VERSION ""

NS_ :

BS_:

BU_: HC IDC_L3 RRR SRR_L SRR_R GW Tester RSDS_L RSDS_R FR IFC HAP PAS CR_L CR_R IDC_L2 HAP_PAS

BO_ 642 HAP_FD4: 64 HAP
 SG_ OD_Obj1_ID : 63|4@0+ (1,0) [0|15] ""  IDC_L3
 SG_ OD_Obj1_type : 15|3@0+ (1,0) [0|3] ""  IDC_L3
 SG_ OD_Obj1_Confidence : 23|4@0+ (0.1,0) [0|1] ""  IDC_L3
 SG_ OD_Obj1_width : 12|5@0+ (0.1,0) [0.1|3.1] "m"  IDC_L3
 SG_ OD_Obj1_length : 19|6@0+ (0.1,0) [0.1|6.3] "m"  IDC_L3
 SG_ OD_Obj1_height : 29|6@0+ (0.1,0) [0.1|6.3] "m"  IDC_L3
 SG_ OD_Obj1_Ground_Pos_X : 39|12@0+ (0.01,0) [0|40] "m"  IDC_L3
 SG_ OD_Obj1_Ground_Pos_Y : 43|12@0+ (0.01,0) [-20|20] "m"  IDC_L3
 SG_ OD_Obj2_ID : 127|4@0+ (1,0) [0|15] ""  IDC_L3
 SG_ OD_Obj2_type : 79|3@0+ (1,0) [0|3] ""  IDC_L3
 SG_ OD_Obj2_Confidence : 87|4@0+ (0.1,0) [0|1] ""  IDC_L3
 SG_ OD_Obj2_width : 76|5@0+ (0.1,0) [0.1|3.1] "m"  IDC_L3
 SG_ OD_Obj2_length : 83|6@0+ (0.1,0) [0.1|6.3] "m"  IDC_L3
 SG_ OD_Obj2_height : 93|6@0+ (0.1,0) [0.1|6.3] "m"  IDC_L3
 SG_ OD_Obj2_Ground_Pos_X : 103|12@0+ (0.01,0) [0|40] "m"  IDC_L3
 SG_ OD_Obj2_Ground_Pos_Y : 107|12@0+ (0.01,0) [-20|20] "m"  IDC_L3
 SG_ OD_Obj3_ID : 191|4@0+ (1,0) [0|15] ""  IDC_L3
 SG_ OD_Obj3_type : 143|3@0+ (1,0) [0|3] ""  IDC_L3
 SG_ OD_Obj3_Confidence : 151|4@0+ (0.1,0) [0|1] ""  IDC_L3
 SG_ OD_Obj3_width : 140|5@0+ (0.1,0) [0.1|3.1] "m"  IDC_L3
 SG_ OD_Obj3_length : 147|6@0+ (0.1,0) [0.1|6.3] "m"  IDC_L3
 SG_ OD_Obj3_height : 157|6@0+ (0.1,0) [0.1|6.3] "m"  IDC_L3
 SG_ OD_Obj3_Ground_Pos_X : 167|12@0+ (0.01,0) [0|40] "m"  IDC_L3
 SG_ OD_Obj3_Ground_Pos_Y : 171|12@0+ (0.01,0) [-20|20] "m"  IDC_L3
 SG_ OD_Obj4_ID : 255|4@0+ (1,0) [0|15] ""  IDC_L3
 SG_ OD_Obj4_type : 207|3@0+ (1,0) [0|3] ""  IDC_L3
 SG_ OD_Obj4_Confidence : 215|4@0+ (0.1,0) [0|1] ""  IDC_L3
 SG_ OD_Obj4_width : 204|5@0+ (0.1,0) [0.1|3.1] "m"  IDC_L3
 SG_ OD_Obj4_length : 211|6@0+ (0.1,0) [0.1|6.3] "m"  IDC_L3
 SG_ OD_Obj4_height : 221|6@0+ (0.1,0) [0.1|6.3] "m"  IDC_L3
 SG_ OD_Obj4_Ground_Pos_X : 231|12@0+ (0.01,0) [0|40] "m"  IDC_L3
 SG_ OD_Obj4_Ground_Pos_Y : 235|12@0+ (0.01,0) [-20|20] "m"  IDC_L3
 SG_ OD_Obj5_ID : 319|4@0+ (1,0) [0|15] ""  IDC_L3
 SG_ OD_Obj5_type : 271|3@0+ (1,0) [0|3] ""  IDC_L3
 SG_ OD_Obj5_Confidence : 279|4@0+ (0.1,0) [0|1] ""  IDC_L3
 SG_ OD_Obj5_width : 268|5@0+ (0.1,0) [0.1|3.1] "m"  IDC_L3
 SG_ OD_Obj5_length : 275|6@0+ (0.1,0) [0.1|6.3] "m"  IDC_L3
 SG_ OD_Obj5_height : 285|6@0+ (0.1,0) [0.1|6.3] "m"  IDC_L3
 SG_ OD_Obj5_Ground_Pos_X : 295|12@0+ (0.01,0) [0|40] "m"  IDC_L3
 SG_ OD_Obj5_Ground_Pos_Y : 299|12@0+ (0.01,0) [-20|20] "m"  IDC_L3
 SG_ OD_Obj6_ID : 383|4@0+ (1,0) [0|15] ""  IDC_L3
 SG_ OD_Obj6_type : 335|3@0+ (1,0) [0|3] ""  IDC_L3
 SG_ OD_Obj6_Confidence : 343|4@0+ (0.1,0) [0|1] ""  IDC_L3
 SG_ OD_Obj6_width : 332|5@0+ (0.1,0) [0.1|3.1] "m"  IDC_L3
 SG_ OD_Obj6_length : 339|6@0+ (0.1,0) [0.1|6.3] "m"  IDC_L3
 SG_ OD_Obj6_height : 349|6@0+ (0.1,0) [0.1|6.3] "m"  IDC_L3
 SG_ OD_Obj6_Ground_Pos_X : 359|12@0+ (0.01,0) [0|40] "m"  IDC_L3
 SG_ OD_Obj6_Ground_Pos_Y : 363|12@0+ (0.01,0) [-20|20] "m"  IDC_L3
 SG_ OD_Obj7_ID : 447|4@0+ (1,0) [0|15] ""  IDC_L3
 SG_ OD_Obj7_type : 399|3@0+ (1,0) [0|3] ""  IDC_L3
 SG_ OD_Obj7_Confidence : 407|4@0+ (0.1,0) [0|1] ""  IDC_L3
 SG_ OD_Obj7_width : 396|5@0+ (0.1,0) [0.1|3.1] "m"  IDC_L3
 SG_ OD_Obj7_length : 403|6@0+ (0.1,0) [0.1|6.3] "m"  IDC_L3
 SG_ OD_Obj7_height : 413|6@0+ (0.1,0) [0.1|6.3] "m"  IDC_L3
 SG_ OD_Obj7_Ground_Pos_X : 423|12@0+ (0.01,0) [0|40] "m"  IDC_L3
 SG_ OD_Obj7_Ground_Pos_Y : 427|12@0+ (0.01,0) [-20|20] "m"  IDC_L3

BO_ 643 IDC_L3_FD3: 16 IDC_L3
 SG_ Checksum_IDC_L3_2 : 7|8@0+ (1,0) [0|255] ""  GW
 SG_ HWP_OperSts : 47|4@0+ (1,0) [0|15] ""  GW
 SG_ EgoVehSpd : 23|12@0+ (0.1,0) [0|200] "km/h"  GW
 SG_ HWP_SpdMaxLim : 27|12@0+ (0.1,0) [0|200] "km/h"  GW
 SG_ HWP_CrsSpdSetVal : 15|8@0+ (1,0) [0|255] "kph/mph"  GW
 SG_ HWP_VehSpdUnit : 49|1@0+ (1,0) [0|1] ""  GW
 SG_ HWP_OperStsDecision : 43|4@0+ (1,0) [0|15] ""  GW
 SG_ HWP_TextWarn : 55|4@0+ (1,0) [0|15] ""  GW
 SG_ HWP_ChimeWarn : 51|2@0+ (1,0) [0|3] ""  GW
 SG_ HWP_HAP_Cmd : 63|2@0+ (1,0) [0|3] ""  HAP
 SG_ RollingCounter_IDC_L3_2 : 59|4@0+ (1,0) [0|15] ""  GW
 SG_ FreshnessValue_IDC_L3_FD3 : 71|16@0+ (1,0) [0|65535] ""  GW
 SG_ MAC_Check_IDC_L3_FD3 : 87|48@0+ (1,0) [0|281474976710655] ""  GW

BO_ 647 HC1: 16 HC
 SG_ CheckSum_HC1 : 7|8@0+ (1,0) [0|255] ""  GW,IFC,IDC_L2
 SG_ HighBeamSts_HC : 15|1@0+ (1,0) [0|1] ""  GW,IFC,IDC_L2
 SG_ ADBstatus : 14|2@0+ (1,0) [0|3] ""  GW,IFC,IDC_L2
 SG_ LeftLowBeamFailSts : 12|1@0+ (1,0) [0|1] ""  GW,IFC,IDC_L2
 SG_ RightLowBeamFailSts : 11|1@0+ (1,0) [0|1] ""  GW,IFC,IDC_L2
 SG_ LeftHighBeamFailSts : 10|1@0+ (1,0) [0|1] ""  GW,IFC,IDC_L2
 SG_ RightHighBeamFailSts : 9|1@0+ (1,0) [0|1] ""  GW,IFC,IDC_L2
 SG_ ALS_FailSts : 8|1@0+ (1,0) [0|1] ""  GW,IFC,IDC_L2
 SG_ ALSDrvSide_FB : 39|1@0+ (1,0) [0|1] ""  GW
 SG_ HBStatusSegment0 : 23|2@0+ (1,0) [0|3] ""  IFC,IDC_L2
 SG_ HBStatusSegment1 : 21|2@0+ (1,0) [0|3] ""  IFC,IDC_L2
 SG_ HBStatusSegment2 : 19|2@0+ (1,0) [0|3] ""  IFC,IDC_L2
 SG_ HBStatusSegment3 : 17|2@0+ (1,0) [0|3] ""  IFC,IDC_L2
 SG_ HBStatusSegment4 : 31|2@0+ (1,0) [0|3] ""  IFC,IDC_L2
 SG_ HBStatusSegment5 : 29|2@0+ (1,0) [0|3] ""  IFC,IDC_L2
 SG_ HBStatusSegment6 : 27|2@0+ (1,0) [0|3] ""  IFC,IDC_L2
 SG_ HBStatusSegment7 : 25|2@0+ (1,0) [0|3] ""  IFC,IDC_L2
 SG_ RollingCounter_HC1 : 59|4@0+ (1,0) [0|15] ""  GW,IFC,IDC_L2

BO_ 648 HUT_FD2: 64 GW
 SG_ HUT_OD_Obj0_ID : 15|4@0+ (1,0) [0|9] ""  HAP_PAS
 SG_ HUT_OD_Obj0_type : 23|3@0+ (1,0) [0|7] ""  HAP_PAS
 SG_ HUT_OD_Obj0_Confidence : 11|4@0+ (0.1,0) [0|1] ""  HAP_PAS
 SG_ HUT_OD_Obj0_width : 20|7@0+ (0.1,0) [0|12.6] "m"  HAP_PAS
 SG_ HUT_OD_Obj0_Ground_Pos_X : 39|12@0+ (0.01,0) [0|40] "m"  HAP_PAS
 SG_ HUT_OD_Obj0_Ground_Pos_Y : 43|12@0+ (0.01,-20) [-20|20] "m"  HAP_PAS
 SG_ HTU_OD_Obj1_ID : 79|4@0+ (1,0) [0|9] ""  HAP_PAS
 SG_ HUT_OD_Obj1_type : 87|3@0+ (1,0) [0|7] ""  HAP_PAS
 SG_ HUT_OD_Obj1_Confidence : 75|4@0+ (0.1,0) [0|1] ""  HAP_PAS
 SG_ HUT_OD_Obj1_width : 84|7@0+ (0.1,0) [0|12.6] "m"  HAP_PAS
 SG_ HUT_OD_Obj1_Ground_Pos_X : 103|12@0+ (0.01,0) [0|40] "m"  HAP_PAS
 SG_ HUT_OD_Obj1_Ground_Pos_Y : 107|12@0+ (0.01,-20) [-20|20] "m"  HAP_PAS
 SG_ HUT_OD_Obj2_ID : 143|4@0+ (1,0) [0|9] ""  HAP_PAS
 SG_ HUT_OD_Obj2_type : 151|3@0+ (1,0) [0|7] ""  HAP_PAS
 SG_ HUT_OD_Obj2_Confidence : 139|4@0+ (0.1,0) [0|1] ""  HAP_PAS
 SG_ HUT_OD_Obj2_width : 148|7@0+ (0.1,0) [0|12.6] "m"  HAP_PAS
 SG_ HUT_OD_Obj2_Ground_Pos_X : 167|12@0+ (0.01,0) [0|40] "m"  HAP_PAS
 SG_ HUT_OD_Obj2_Ground_Pos_Y : 171|12@0+ (0.01,-20) [-20|20] "m"  HAP_PAS
 SG_ HUT_OD_Obj3_ID : 207|4@0+ (1,0) [0|9] ""  HAP_PAS
 SG_ HUT_OD_Obj3_type : 215|3@0+ (1,0) [0|7] ""  HAP_PAS
 SG_ HUT_OD_Obj3_Confidence : 203|4@0+ (0.1,0) [0|1] ""  HAP_PAS
 SG_ HUT_OD_Obj3_width : 212|7@0+ (0.1,0) [0|12.6] "m"  HAP_PAS
 SG_ HUT_OD_Obj3_Ground_Pos_X : 231|12@0+ (0.01,0) [0|40] "m"  HAP_PAS
 SG_ HUT_OD_Obj3_Ground_Pos_Y : 235|12@0+ (0.01,-20) [-20|20] "m"  HAP_PAS
 SG_ HUT_OD_Obj4_ID : 271|4@0+ (1,0) [0|9] ""  HAP_PAS
 SG_ HUT_OD_Obj4_type : 279|3@0+ (1,0) [0|7] ""  HAP_PAS
 SG_ HUT_OD_Obj4_Confidence : 267|4@0+ (0.1,0) [0|1] ""  HAP_PAS
 SG_ HUT_OD_Obj4_width : 276|7@0+ (0.1,0) [0|12.6] "m"  HAP_PAS
 SG_ HUT_OD_Obj4_Ground_Pos_X : 295|12@0+ (0.01,0) [0|40] "m"  HAP_PAS
 SG_ HUT_OD_Obj4_Ground_Pos_Y : 299|12@0+ (0.01,-20) [-20|20] "m"  HAP_PAS
 SG_ HUT_OD_Obj5_ID : 335|4@0+ (1,0) [0|9] ""  HAP_PAS
 SG_ HUT_OD_Obj5_type : 343|3@0+ (1,0) [0|7] ""  HAP_PAS
 SG_ HUT_OD_Obj5_Confidence : 331|4@0+ (0.1,0) [0|1] ""  HAP_PAS
 SG_ HUT_OD_Obj5_width : 340|7@0+ (0.1,0) [0|12.6] "m"  HAP_PAS
 SG_ HUT_OD_Obj5_Ground_Pos_X : 359|12@0+ (0.01,0) [0|40] "m"  HAP_PAS
 SG_ HUT_OD_Obj5_Ground_Pos_Y : 363|12@0+ (0.01,-20) [-20|20] "m"  HAP_PAS
 SG_ HUT_OD_Obj6_ID : 399|4@0+ (1,0) [0|9] ""  HAP_PAS
 SG_ HUT_OD_Obj6_type : 407|3@0+ (1,0) [0|7] ""  HAP_PAS
 SG_ HUT_OD_Obj6_Confidence : 395|4@0+ (0.1,0) [0|1] ""  HAP_PAS
 SG_ HUT_OD_Obj6_width : 404|7@0+ (0.1,0) [0|12.6] "m"  HAP_PAS
 SG_ HUT_OD_Obj6_Ground_Pos_X : 423|12@0+ (0.01,0) [0|40] "m"  HAP_PAS
 SG_ HUT_OD_Obj6_Ground_Pos_Y : 427|12@0+ (0.01,-20) [-20|20] "m"  HAP_PAS

BO_ 649 HAP_FD6: 64 HAP
 SG_ HAP_RtCam_WorkSts : 61|2@0+ (1,0) [0|3] ""  GW
 SG_ HAP_RtSide_Obj1_ID : 15|4@0+ (1,0) [0|3] ""  GW
 SG_ HAP_RtSide_Obj1_type : 11|3@0+ (1,0) [0|7] ""  GW
 SG_ HAP_RtSide_Obj1_Confidence : 27|4@0+ (0.1,0) [0|1] ""  GW
 SG_ HAP_RtSide_Obj1_Ground_Pos_X : 23|12@0+ (0.01,0) [0|40] "m"  GW
 SG_ HAP_RtSide_Obj1_Ground_Pos_Y : 39|12@0+ (0.01,-20) [-20|20] "m"  GW
 SG_ HAP_RtSide_Obj2_ID : 79|4@0+ (1,0) [0|3] ""  GW
 SG_ HAP_RtSide_Obj2_type : 75|3@0+ (1,0) [0|7] ""  GW
 SG_ HAP_RtSide_Obj2_Confidence : 91|4@0+ (0.1,0) [0|1] ""  GW
 SG_ HAP_RtSide_Obj2_Ground_Pos_X : 87|12@0+ (0.01,0) [0|40] "m"  GW
 SG_ HAP_RtSide_Obj2_Ground_Pos_Y : 103|12@0+ (0.01,-20) [-20|20] "m"  GW
 SG_ HAP_RtSide_Obj3_ID : 143|4@0+ (1,0) [0|3] ""  GW
 SG_ HAP_RtSide_Obj3_type : 139|3@0+ (1,0) [0|7] ""  GW
 SG_ HAP_RtSide_Obj3_Confidence : 155|4@0+ (0.1,0) [0|1] ""  GW
 SG_ HAP_RtSide_Obj3_Ground_Pos_X : 151|12@0+ (0.01,0) [0|40] "m"  GW
 SG_ HAP_RtSide_Obj3_Ground_Pos_Y : 167|12@0+ (0.01,-20) [-20|20] "m"  GW
 SG_ HAP_RtSide_Obj4_ID : 207|4@0+ (1,0) [0|3] ""  GW
 SG_ HAP_RtSide_Obj4_type : 203|3@0+ (1,0) [0|7] ""  GW
 SG_ HAP_RtSide_Obj4_Confidence : 219|4@0+ (0.1,0) [0|1] ""  GW
 SG_ HAP_RtSide_Obj4_Ground_Pos_X : 215|12@0+ (0.01,0) [0|40] "m"  GW
 SG_ HAP_RtSide_Obj4_Ground_Pos_Y : 231|12@0+ (0.01,-20) [-20|20] "m"  GW
 SG_ USS_FLSide1_Status : 271|2@0+ (1,0) [0|3] ""  GW
 SG_ USS_FLSide1_Dist : 279|7@0+ (0.1,0) [0|12.6] "m"  GW
 SG_ USS_RLSide2_Status : 269|2@0+ (1,0) [0|3] ""  GW
 SG_ USS_RLSide2_Dist : 287|7@0+ (0.1,0) [0|12.6] "m"  GW
 SG_ USS_FRSide1_Status : 267|2@0+ (1,0) [0|3] ""  GW
 SG_ USS_FRSide1_Dist : 295|7@0+ (0.1,0) [0|12.6] "m"  GW
 SG_ USS_RRSide2_Status : 265|2@0+ (1,0) [0|3] ""  GW
 SG_ USS_RRSide2_Dist : 303|7@0+ (0.1,0) [0|12.6] "m"  GW
 SG_ USS_FrontSys_Status : 383|2@0+ (1,0) [0|3] ""  FR
 SG_ USS_FLCNear_Obj_Confidence : 339|4@0+ (0.1,0) [0|1] ""  FR
 SG_ USS_FLCNear_Obj_Pos_X : 335|6@0+ (0.1,0) [0|6.2] "m"  FR
 SG_ USS_FLCNear_Obj_Pos_Y : 329|6@0+ (0.1,-3.1) [-3.1|3.1] "m"  FR
 SG_ USS_FLMNear_Obj_Confidence : 355|4@0+ (0.1,0) [0|1] ""  FR
 SG_ USS_FLMNear_Obj_Pos_X : 351|6@0+ (0.1,0) [0|6.2] "m"  FR
 SG_ USS_FLMNear_Obj_Pos_Y : 345|6@0+ (0.1,-3.1) [-3.1|3.1] "m"  FR
 SG_ USS_FRMNear_Obj_Confidence : 371|4@0+ (0.1,0) [0|1] ""  FR
 SG_ USS_FRMNear_Obj_Pos_X : 367|6@0+ (0.1,0) [0|6.2] "m"  FR
 SG_ USS_FRMNear_Obj_Pos_Y : 361|6@0+ (0.1,-3.1) [-3.1|3.1] "m"  FR
 SG_ USS_FRCNear_Obj_Confidence : 403|4@0+ (0.1,0) [0|1] ""  FR
 SG_ USS_FRCNear_Obj_Pos_X : 399|6@0+ (0.1,0) [0|6.2] "m"  FR
 SG_ USS_FRCNear_Obj_Pos_Y : 393|6@0+ (0.1,-3.1) [-3.1|3.1] "m"  FR

BO_ 657 HAP_FD5: 64 HAP
 SG_ Freespace_1_distance : 79|6@0+ (0.1,0) [0|6] "m"  IDC_L3
 SG_ Freespace_2_distance : 73|6@0+ (0.1,0) [0|6] "m"  IDC_L3
 SG_ Freespace_3_distance : 83|6@0+ (0.1,0) [0|6] "m"  IDC_L3
 SG_ Freespace_4_distance : 93|6@0+ (0.1,0) [0|6] "m"  IDC_L3
 SG_ Freespace_5_distance : 103|6@0+ (0.1,0) [0|6] "m"  IDC_L3
 SG_ Freespace_6_distance : 97|6@0+ (0.1,0) [0|6] "m"  IDC_L3
 SG_ Freespace_7_distance : 107|6@0+ (0.1,0) [0|6] "m"  IDC_L3
 SG_ Freespace_8_distance : 117|6@0+ (0.1,0) [0|6] "m"  IDC_L3
 SG_ Freespace_9_distance : 143|6@0+ (0.1,0) [0|6] "m"  IDC_L3
 SG_ Freespace_10_distance : 137|6@0+ (0.1,0) [0|6] "m"  IDC_L3
 SG_ Freespace_11_distance : 147|6@0+ (0.1,0) [0|6] "m"  IDC_L3
 SG_ Freespace_12_distance : 157|6@0+ (0.1,0) [0|6] "m"  IDC_L3
 SG_ Freespace_13_distance : 167|6@0+ (0.1,0) [0|6] "m"  IDC_L3
 SG_ Freespace_14_distance : 161|6@0+ (0.1,0) [0|6] "m"  IDC_L3
 SG_ Freespace_15_distance : 171|6@0+ (0.1,0) [0|6] "m"  IDC_L3
 SG_ Freespace_16_distance : 181|6@0+ (0.1,0) [0|6] "m"  IDC_L3
 SG_ Freespace_17_distance : 207|6@0+ (0.1,0) [0|6] "m"  IDC_L3
 SG_ Freespace_18_distance : 201|6@0+ (0.1,0) [0|6] "m"  IDC_L3
 SG_ Freespace_19_distance : 211|6@0+ (0.1,0) [0|6] "m"  IDC_L3
 SG_ Freespace_20_distance : 221|6@0+ (0.1,0) [0|6] "m"  IDC_L3
 SG_ Freespace_21_distance : 231|6@0+ (0.1,0) [0|6] "m"  IDC_L3
 SG_ Freespace_22_distance : 225|6@0+ (0.1,0) [0|6] "m"  IDC_L3
 SG_ Freespace_23_distance : 235|6@0+ (0.1,0) [0|6] "m"  IDC_L3
 SG_ Freespace_24_distance : 245|6@0+ (0.1,0) [0|6] "m"  IDC_L3
 SG_ Freespace_25_distance : 271|6@0+ (0.1,0) [0|6] "m"  IDC_L3
 SG_ Freespace_26_distance : 265|6@0+ (0.1,0) [0|6] "m"  IDC_L3
 SG_ Freespace_27_distance : 275|6@0+ (0.1,0) [0|6] "m"  IDC_L3
 SG_ Freespace_28_distance : 285|6@0+ (0.1,0) [0|6] "m"  IDC_L3
 SG_ Freespace_29_distance : 295|6@0+ (0.1,0) [0|6] "m"  IDC_L3
 SG_ Freespace_30_distance : 289|6@0+ (0.1,0) [0|6] "m"  IDC_L3
 SG_ Freespace_31_distance : 299|6@0+ (0.1,0) [0|6] "m"  IDC_L3
 SG_ Freespace_32_distance : 309|6@0+ (0.1,0) [0|6] "m"  IDC_L3
 SG_ Freespace_33_distance : 335|6@0+ (0.1,0) [0|6] "m"  IDC_L3
 SG_ Freespace_34_distance : 329|6@0+ (0.1,0) [0|6] "m"  IDC_L3
 SG_ Freespace_35_distance : 339|6@0+ (0.1,0) [0|6] "m"  IDC_L3
 SG_ Freespace_36_distance : 349|6@0+ (0.1,0) [0|6] "m"  IDC_L3
 SG_ Freespace_37_distance : 359|6@0+ (0.1,0) [0|6] "m"  IDC_L3
 SG_ Freespace_38_distance : 353|6@0+ (0.1,0) [0|6] "m"  IDC_L3
 SG_ Freespace_39_distance : 363|6@0+ (0.1,0) [0|6] "m"  IDC_L3
 SG_ Freespace_40_distance : 373|6@0+ (0.1,0) [0|6] "m"  IDC_L3
 SG_ Freespace_41_distance : 399|6@0+ (0.1,0) [0|6] "m"  IDC_L3
 SG_ Freespace_42_distance : 393|6@0+ (0.1,0) [0|6] "m"  IDC_L3
 SG_ Freespace_43_distance : 403|6@0+ (0.1,0) [0|6] "m"  IDC_L3
 SG_ Freespace_44_distance : 413|6@0+ (0.1,0) [0|6] "m"  IDC_L3
 SG_ Freespace_45_distance : 423|6@0+ (0.1,0) [0|6] "m"  IDC_L3
 SG_ Freespace_46_distance : 417|6@0+ (0.1,0) [0|6] "m"  IDC_L3
 SG_ Freespace_47_distance : 427|6@0+ (0.1,0) [0|6] "m"  IDC_L3
 SG_ Freespace_48_distance : 437|6@0+ (0.1,0) [0|6] "m"  IDC_L3

BO_ 661 PEPS2: 8 GW
 SG_ SysPowerMod : 15|2@0+ (1,0) [0|3] ""  HC,RSDS_R,RSDS_L,HAP,HAP_PAS,CR_L,CR_R,IDC_L2,IDC_L3
 SG_ SysPowerModVld : 13|1@0+ (1,0) [0|1] ""  RSDS_R,RSDS_L,HAP,HAP_PAS,CR_L,CR_R,IDC_L2,IDC_L3

BO_ 664 HAP_FD3: 64 HAP_PAS
 SG_ RPAS_NearBrrdstn : 15|8@0+ (1,0) [0|150] ""  GW
 SG_ APS_ObjRiSideAr1 : 79|4@0+ (1,0) [0|15] ""  GW
 SG_ APS_ObjRiSideAr2 : 75|4@0+ (1,0) [0|15] ""  GW
 SG_ APS_ObjRiSideAr3 : 87|4@0+ (1,0) [0|15] ""  GW
 SG_ APS_ObjRiSideAr4 : 83|4@0+ (1,0) [0|15] ""  GW
 SG_ APS_ObjRiSideAr5 : 95|4@0+ (1,0) [0|15] ""  GW
 SG_ APS_ObjLeSideAr1 : 91|4@0+ (1,0) [0|15] ""  GW
 SG_ APS_ObjLeSideAr2 : 103|4@0+ (1,0) [0|15] ""  GW
 SG_ APS_ObjLeSideAr3 : 99|4@0+ (1,0) [0|15] ""  GW
 SG_ APS_ObjLeSideAr4 : 111|4@0+ (1,0) [0|15] ""  GW
 SG_ APS_ObjLeSideAr5 : 107|4@0+ (1,0) [0|15] ""  GW
 SG_ APS_FRSideSnsrFailSts : 119|1@0+ (1,0) [0|1] ""  GW
 SG_ APS_FLSideSnsrFailSts : 118|1@0+ (1,0) [0|1] ""  GW
 SG_ APS_RRSideSnsrFailSts : 117|1@0+ (1,0) [0|1] ""  GW
 SG_ APS_RLSideSnsrFailSts : 116|1@0+ (1,0) [0|1] ""  GW
 SG_ SDW_SoundIndcn : 115|2@0+ (1,0) [0|3] ""  GW
 SG_ SDWActiveSts : 112|1@0+ (1,0) [0|1] ""  GW
 SG_ RPAS_ObjRRCornrAr1 : 143|4@0+ (1,0) [0|15] ""  GW
 SG_ RPAS_ObjRRCornrAr2 : 139|4@0+ (1,0) [0|15] ""  GW
 SG_ RPAS_ObjRRMidlAr1 : 151|4@0+ (1,0) [0|15] ""  GW
 SG_ RPAS_ObjRRMidlAr2 : 147|4@0+ (1,0) [0|15] ""  GW
 SG_ RPAS_ObjRLMidlAr1 : 159|4@0+ (1,0) [0|15] ""  GW
 SG_ RPAS_ObjRLMidlAr2 : 155|4@0+ (1,0) [0|15] ""  GW
 SG_ RPAS_ObjRLCornrAr1 : 167|4@0+ (1,0) [0|15] ""  GW
 SG_ RPAS_ObjRLCornrAr2 : 163|4@0+ (1,0) [0|15] ""  GW
 SG_ RPAS_RLCornrSnsrFailSts : 175|1@0+ (1,0) [0|1] ""  GW
 SG_ RPAS_RLMiddlSnsrFailSts : 174|1@0+ (1,0) [0|1] ""  GW
 SG_ RPAS_RRMiddlSnsrFailSts : 173|1@0+ (1,0) [0|1] ""  GW
 SG_ RPAS_RRCornrSnsrFailSts : 172|1@0+ (1,0) [0|1] ""  GW
 SG_ RPAS_WorkSts : 171|2@0+ (1,0) [0|3] ""  GW
 SG_ RPAS_SoundIndcn : 183|2@0+ (1,0) [0|3] ""  GW
 SG_ MEBWorkSts : 180|2@0+ (1,0) [0|3] ""  GW
 SG_ MEB_EnableSts : 178|1@0+ (1,0) [0|1] ""  GW
 SG_ FPAS_ObjFLCornrAr1 : 207|4@0+ (1,0) [0|15] ""  GW
 SG_ FPAS_ObjFLCornrAr2 : 203|4@0+ (1,0) [0|15] ""  GW
 SG_ FPAS_ObjFLMidlAr1 : 215|4@0+ (1,0) [0|15] ""  GW
 SG_ FPAS_ObjFLMidlAr2 : 211|4@0+ (1,0) [0|15] ""  GW
 SG_ FPAS_ObjFRMidlAr1 : 223|4@0+ (1,0) [0|15] ""  GW
 SG_ FPAS_ObjFRMidlAr2 : 219|4@0+ (1,0) [0|15] ""  GW
 SG_ FPAS_ObjFRCornrAr1 : 231|4@0+ (1,0) [0|15] ""  GW
 SG_ FPAS_ObjFRCornrAr2 : 227|4@0+ (1,0) [0|15] ""  GW
 SG_ FPAS_FLCornrSnsrFailSts : 239|1@0+ (1,0) [0|1] ""  GW
 SG_ FPAS_FLMiddlSnsrFailSts : 238|1@0+ (1,0) [0|1] ""  GW
 SG_ FPAS_FRMiddlSnsrFailSts : 237|1@0+ (1,0) [0|1] ""  GW
 SG_ FPAS_FRCornrSnsrFailSts : 236|1@0+ (1,0) [0|1] ""  GW
 SG_ FPAS_WorkSts : 235|2@0+ (1,0) [0|3] ""  GW
 SG_ FPAS_DispCmd : 233|1@0+ (1,0) [0|1] ""  GW
 SG_ FPAS_AutoModSts : 232|1@0+ (1,0) [0|1] ""  GW
 SG_ FPAS_SoundIndcn : 247|2@0+ (1,0) [0|3] ""  GW
 SG_ FPAS_NearBrrdstn : 242|7@0+ (1,0) [0|100] ""  GW
 SG_ APA_MenuDispCtrlCmd : 279|4@0+ (1,0) [0|15] ""  GW
 SG_ APA_FuncSts : 271|2@0+ (1,0) [0|3] ""  GW
 SG_ P2P_FuncSts : 269|2@0+ (1,0) [0|3] ""  GW
 SG_ RADS_FuncSts : 267|2@0+ (1,0) [0|3] ""  GW
 SG_ FADS_FuncSts : 265|2@0+ (1,0) [0|3] ""  GW
 SG_ HAP_TextIconDispCtrl : 275|2@0+ (1,0) [0|3] ""  GW
 SG_ OrvmCtrlCmd : 273|2@0+ (1,0) [0|3] ""  GW
 SG_ RmtPrkgFinishReq : 287|2@0+ (1,0) [0|3] ""  GW
 SG_ RmtPrkgSts : 285|1@0+ (1,0) [0|1] ""  GW
 SG_ APS_Coordinate_Angle : 284|9@0+ (1,0) [0|359] "deg"  GW
 SG_ APS_Coordinate_X : 291|9@0+ (2,-500) [-500|500] "cm"  GW
 SG_ APS_Coordinate_Y : 298|11@0+ (2,-2000) [-2000|2000] "cm"  GW
 SG_ HAPob_WorkSts : 335|2@0+ (1,0) [0|3] ""  IDC_L3
 SG_ LtCobfi : 375|7@0+ (0.01,0) [0|1] ""  IDC_L3
 SG_ LtCurVtur : 351|12@0+ (1E-005,-0.02) [-0.02|0.02] "1/m"  IDC_L3
 SG_ LtSlope : 333|14@0+ (0.001,-6) [-6|6] ""  IDC_L3
 SG_ Ltlntcep : 353|10@0+ (0.01,-5) [-5|5] "m"  IDC_L3
 SG_ RtCobfi : 439|7@0+ (0.01,0) [0|1] ""  IDC_L3
 SG_ RtCurVtur : 415|12@0+ (1E-005,-0.02) [-0.02|0.02] "1/m"  IDC_L3
 SG_ RtSlope : 397|14@0+ (0.001,-6) [-6|-6] ""  IDC_L3
 SG_ Rtlntcep : 417|10@0+ (0.01,-5) [-5|5] "m"  IDC_L3
 SG_ FreshnessValue_HAP_FD3 : 455|16@0+ (1,0) [0|65535] ""  GW
 SG_ MAC_Check_HAP_FD3 : 471|48@0+ (1,0) [0|281474976710655] ""  GW

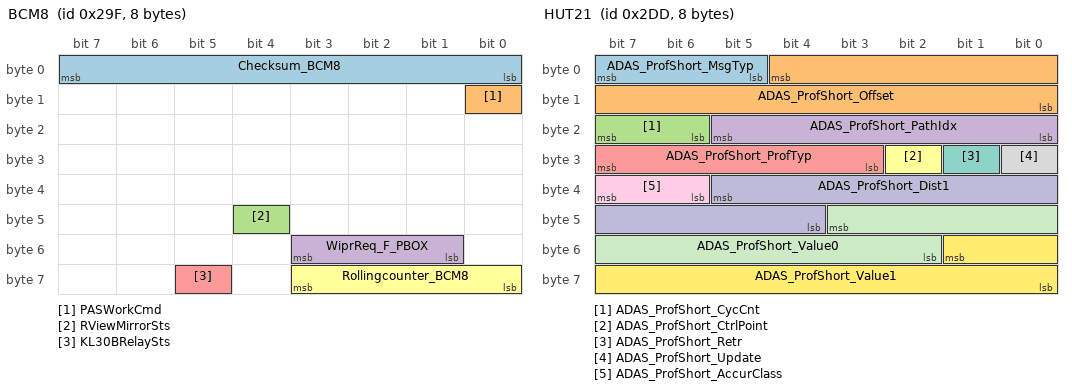
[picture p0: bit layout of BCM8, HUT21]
BO_ 671 BCM8: 8 GW
 SG_ Checksum_BCM8 : 7|8@0+ (1,0) [0|255] ""  HAP,HAP_PAS
 SG_ PASWorkCmd : 8|1@0+ (1,0) [0|1] ""  HAP,HAP_PAS
 SG_ RViewMirrorSts : 44|1@0+ (1,0) [0|1] ""  HAP,HAP_PAS
 SG_ WiprReq_F_PBOX : 51|3@0+ (1,0) [0|7] ""  IFC,HC,IDC_L2
 SG_ KL30BRelaySts : 61|1@0+ (1,0) [0|1] ""  IFC,IDC_L2
 SG_ Rollingcounter_BCM8 : 59|4@0+ (1,0) [0|15] ""  HAP,HAP_PAS

BO_ 680 EEM1: 8 GW
 SG_ TranPMode_Sts : 7|1@0+ (1,0) [0|1] ""  HC
 SG_ Stat_PwrSv_Lvl : 6|3@0+ (1,0) [0|7] ""  HC

BO_ 683 ACC_FD2: 64 FR
 SG_ ACC_LeTgt_02_Dy : 15|7@0+ (0.1,0) [0|8] "m"  GW
 SG_ ACC_LeTgt_02_Dx : 8|9@0+ (0.5,0) [0|150] "m"  GW
 SG_ ACC_LeTgt_02_Typ : 31|3@0+ (1,0) [0|7] ""  GW
 SG_ ACC_LeTargrt_02_Detn : 28|2@0+ (1,0) [0|3] ""  GW
 SG_ ACC_RiTargrt_02_Detn : 26|2@0+ (1,0) [0|3] ""  GW
 SG_ ACC_RiTgt_02_Dy : 55|7@0+ (0.1,-8) [-8|0] "m"  GW
 SG_ ACC_RiTgt_02_Dx : 24|9@0+ (0.5,0) [0|150] "m"  GW
 SG_ ACC_RiTgt_02_Typ : 63|3@0+ (1,0) [0|7] ""  GW
 SG_ ACC_LeTgtObjBarDisp : 47|3@0+ (1,0) [0|7] ""  GW
 SG_ ACC_RiTgtObjBarDisp : 44|3@0+ (1,0) [0|7] ""  GW
 SG_ Checksum_ACC3 : 71|8@0+ (1,0) [0|255] ""  GW
 SG_ ISL_Resp : 79|1@0+ (1,0) [0|1] ""  GW
 SG_ ICA_HandsOffResp : 78|1@0+ (1,0) [0|1] ""  GW
 SG_ Longctrl_VehHldReq_DVR : 87|1@0+ (1,0) [0|1] ""  GW
 SG_ Longctrl_DrvOFF_Req_DVR : 86|1@0+ (1,0) [0|1] ""  GW
 SG_ Longctrl_ModSts_DVR : 85|4@0+ (1,0) [0|15] ""  GW
 SG_ Longctrl_Decel_Req_DVR : 81|1@0+ (1,0) [0|1] ""  GW
 SG_ Longctrl_EngTrqReq_DVR : 95|16@0+ (0.0030518,-100) [-100|99.999713] "%"  GW
 SG_ Longctrl_EngTrqReqActive_DVR : 80|1@0+ (1,0) [0|1] ""  GW
 SG_ Longctrl_DecelToStopReq_DVR : 119|1@0+ (1,0) [0|1] ""  GW
 SG_ Longctrl_ParkShiftReq_DVR : 118|2@0+ (1,0) [0|3] ""  GW
 SG_ Longctrl_Decel_ReqValue_DVR : 111|8@0+ (0.05,-7) [-7|5.75] "m/s^2"  GW
 SG_ Longctrl_HCUTrqReqActive_DVR : 116|1@0+ (1,0) [0|1] ""  GW
 SG_ HWA_SnvtySet_Resp : 76|2@0+ (1,0) [0|3] ""  GW
 SG_ HWA_Resp : 77|1@0+ (1,0) [0|1] ""  GW
 SG_ ALC_Resp : 73|1@0+ (1,0) [0|1] ""  GW
 SG_ ALC_InterSysInfoDisp : 127|2@0+ (1,0) [0|3] ""  GW
 SG_ RollingCounter_ACC3 : 123|4@0+ (1,0) [0|15] ""  GW
 SG_ Checksum_ACC8 : 199|8@0+ (1,0) [0|255] ""  GW
 SG_ Longctrl_HCUTrqReq_DVR : 231|16@0+ (0.5,-16384) [-16384|16383.5] "NM"  GW
 SG_ HWA_warning : 217|2@0+ (1,0) [0|3] ""  GW
 SG_ HWA_ModDisp : 207|4@0+ (1,0) [0|15] ""  GW
 SG_ HWA_InterSysInfoDisp : 203|4@0+ (1,0) [0|15] ""  GW
 SG_ HWA_LaneChangeReq : 223|3@0+ (1,0) [0|7] ""  GW
 SG_ HWA_LaneChange : 213|2@0+ (1,0) [0|3] ""  GW
 SG_ ADAS_DriverInloop_Monitor : 211|3@0+ (1,7) [7|7] ""  GW
 SG_ RollingCounter_ACC8 : 251|4@0+ (1,0) [0|15] ""  GW
 SG_ Checksum_ACC4 : 135|8@0+ (1,0) [0|255] ""  GW
 SG_ ACC_ObjDetecte : 143|1@0+ (1,0) [0|1] ""  GW
 SG_ ACC_TakeOverReq : 142|1@0+ (1,0) [0|1] ""  GW
 SG_ ACC_InterSysInfoDisp : 141|5@0+ (1,0) [0|31] ""  GW
 SG_ ACC_ModDisp : 151|5@0+ (1,0) [0|31] ""  GW
 SG_ ACC_FctSts : 146|2@0+ (1,0) [0|3] ""  GW
 SG_ ACC_TgtObjBarDisp : 159|3@0+ (1,0) [0|7] ""  GW
 SG_ ACC_TimeGapSet : 170|3@0+ (1,0) [0|7] ""  GW
 SG_ ACC_SpdSetValue : 183|8@0+ (1,0) [0|255] "kph/mph"  GW
 SG_ Longctrl_HazActv : 156|2@0+ (1,0) [0|3] ""  GW
 SG_ TJA_ACC_SelSts : 154|3@0+ (1,0) [0|7] ""  GW
 SG_ TJA_ICA_ModDisp : 175|3@0+ (1,0) [0|7] ""  GW
 SG_ TJA_ICA_InterSysInfoDisp : 163|3@0+ (1,0) [0|7] ""  GW
 SG_ ISL_InterSysInfoDisp : 172|2@0+ (1,0) [0|3] ""  GW
 SG_ CruCha_ModDisp : 167|4@0+ (1,0) [0|15] ""  GW
 SG_ CruChar_InterSysInfoDisp : 191|4@0+ (1,0) [0|15] ""  GW
 SG_ RollingCounter_ACC4 : 187|4@0+ (1,0) [0|15] ""  GW
 SG_ Checksum_ACC6 : 263|8@0+ (1,0) [0|255] ""  GW
 SG_ ACC_PotentialTgtDy : 271|8@0+ (0.1,-8) [-8|8] "m"  GW
 SG_ ACC_PotentialTgtDx : 279|9@0+ (0.5,0) [0|150] "m"  GW
 SG_ ACC_RlvTgtDetn : 286|2@0+ (1,0) [0|3] ""  GW,HAP
 SG_ ACC_EgoStatus : 284|2@0+ (1,0) [0|3] ""  GW
 SG_ ACC_RlvTgtTyp : 282|3@0+ (1,0) [0|7] ""  GW,HAP
 SG_ ACC_RlvTgtDy : 295|8@0+ (0.1,-8) [-8|8] "m"  GW,HAP
 SG_ ACC_RlvTgtDx : 303|9@0+ (0.5,0) [0|150] "m"  GW,HAP
 SG_ ACC_PotentialTgtDetn : 309|2@0+ (1,0) [0|3] ""  GW
 SG_ ACC_PotentialTgtTyp : 307|3@0+ (1,0) [0|7] ""  GW
 SG_ IntelligentCurveAct : 319|1@0+ (1,0) [0|1] "" Vector__XXX
 SG_ RollingCounter_ACC6 : 315|4@0+ (1,0) [0|15] ""  GW
 SG_ Checksum_ACC7 : 327|8@0+ (1,0) [0|255] ""  GW
 SG_ Request_driveoff : 383|3@0+ (1,0) [0|7] ""  GW
 SG_ ACC_LeTgtDy : 335|8@0+ (0.1,-8) [-8|8] "m"  GW,HAP
 SG_ ACC_LeTgtDx : 343|9@0+ (0.5,0) [0|150] "m"  GW,HAP
 SG_ ACC_LeTgtTyp : 350|3@0+ (1,0) [0|7] ""  GW,HAP
 SG_ ACC_LeTargrtDection : 347|2@0+ (1,0) [0|3] ""  GW,HAP
 SG_ ACC_RiTargrtDetn : 345|2@0+ (1,0) [0|3] ""  GW,HAP
 SG_ ACC_RiTgtDy : 359|8@0+ (0.1,-8) [-8|8] "m"  GW,HAP
 SG_ ACC_RiTgtDx : 367|9@0+ (0.5,0) [0|150] "m"  GW,HAP
 SG_ ACC_RiTgtTyp : 374|3@0+ (1,0) [0|7] ""  GW,HAP
 SG_ RollingCounter_ACC7 : 379|4@0+ (1,0) [0|15] ""  GW
 SG_ ACC_RlvTgtfusion : 399|1@0+ (1,0) [0|1] ""  GW
 SG_ ACC_RlvTgtHeading : 398|6@0+ (0.05,-1.5) [-1.5|1.5] "rad"  GW
 SG_ ACC_LeTgtfusion : 392|1@0+ (1,0) [0|1] ""  GW
 SG_ ACC_LeTgtHeading : 407|6@0+ (0.05,-1.5) [-1.5|1.5] "rad"  GW
 SG_ ACC_RiTgtfusion : 401|1@0+ (1,0) [0|1] ""  GW
 SG_ ACC_RiTgtHeading : 415|6@0+ (0.05,-1.5) [-1.5|1.5] "rad"  GW
 SG_ ACC_PotentialTgtfusion : 400|1@0+ (1,0) [0|1] ""  GW
 SG_ ACC_PotentialTgtHeading : 409|6@0+ (0.05,-1.5) [-1.5|1.5] "rad"  GW
 SG_ TargetCutinPro : 419|6@0+ (0.02,0) [0|1] ""  GW
 SG_ TargetCutoutPro : 429|6@0+ (0.02,0) [0|1] ""  GW
 SG_ FreshnessValue_ACC_FD2 : 455|16@0+ (1,0) [0|65535] ""  GW,HAP
 SG_ MAC_Check_ACC_FD2 : 471|48@0+ (1,0) [0|281474976710655] ""  GW,HAP

BO_ 692 ACC_FD3: 64 FR
 SG_ AEB_LePedDetn : 41|2@0+ (1,0) [0|3] ""  GW
 SG_ AEB_LePedDy : 15|8@0+ (0.1,-8) [-8|8] "m"  GW
 SG_ AEB_LePedTyp : 55|3@0+ (1,0) [0|7] ""  GW
 SG_ AEB_LePed_collisionprob : 63|1@0+ (1,0) [0|1] ""  GW
 SG_ AEB_RiPedDetn : 49|2@0+ (1,0) [0|3] ""  GW
 SG_ AEB_RiPedDy : 23|8@0+ (0.1,-8) [-8|8] "m"  GW
 SG_ AEB_RiPedTyp : 52|3@0+ (1,0) [0|7] ""  GW
 SG_ AEB_RiPed_collisionprob : 62|1@0+ (1,0) [0|1] ""  GW
 SG_ AEB_LeCyclistDy : 31|8@0+ (0.1,-8) [-8|8] "m"  GW
 SG_ AEB_LeCyclist_collisionprob : 61|1@0+ (1,0) [0|1] ""  GW
 SG_ AEB_RiCyclistDy : 39|8@0+ (0.1,-8) [-8|8] "m"  GW
 SG_ AEB_RiCyclist_collisionprob : 60|1@0+ (1,0) [0|1] ""  GW
 SG_ JAPedObjExist : 47|6@0+ (0.015625,0) [0|0.984375] "%"  GW
 SG_ AEBJAObjID : 79|8@0+ (1,0) [0|255] ""  GW
 SG_ AEBJAObjExist : 87|6@0+ (0.015625,0) [0|0.984375] "%"  GW
 SG_ JAPedObjID : 119|8@0+ (1,0) [0|255] ""  GW
 SG_ AEBJAObjVideoCfmd : 81|1@0+ (1,0) [0|1] ""  GW
 SG_ AEBJAObjVx : 95|12@0+ (0.0625,-128) [-128|127] "m/s"  GW
 SG_ AEBJAObjDx : 99|12@0+ (0.0625,0) [0|255.9375] "m"  GW
 SG_ JAPedObjVideoCfmd : 80|1@0+ (1,0) [0|1] ""  GW
 SG_ AEBJAObjState : 127|3@0+ (1,0) [0|7] ""  GW
 SG_ AEBJAObjCntAlive : 143|12@0+ (17,0) [0|65535] ""  GW
 SG_ AEBJAObjDy : 147|11@0+ (0.125,-128) [-128|127.875] "m"  GW
 SG_ JAPedObjState : 191|3@0+ (1,0) [0|7] ""  GW
 SG_ AEBJAObjObstcl : 152|5@0+ (0.03125,0) [0|0.96875] "%"  GW
 SG_ AEBJAObjVy : 163|10@0+ (0.125,-64) [-64|63.875] "m/s"  GW
 SG_ AEBJAObjAx : 169|10@0+ (0.03125,-16) [-16|15.96875] "m/s2"  GW
 SG_ AEBJAObjAy : 207|10@0+ (0.03125,-16) [-16|15.96875] "m/s2"  GW
 SG_ JAPedObjObstcl : 213|5@0+ (0.03125,0) [0|0.96875] "%"  GW
 SG_ JAPedObjDy : 223|11@0+ (0.125,-128) [-128|127.875] "m"  GW
 SG_ JAPedObjDx : 228|12@0+ (0.0625,0) [0|255.9375] "m"  GW
 SG_ FCWAEB_JATTC : 247|6@0+ (0.1,0) [0|6.3] "s"  GW
 SG_ JAPedObjVx : 271|12@0+ (0.0625,-128) [-128|127] "m/s"  GW
 SG_ JAPedObjVy : 295|10@0+ (0.125,-64) [-64|63.875] "m/s"  GW
 SG_ JAPedObjAy : 301|10@0+ (0.03125,-16) [-16|15.96875] "m/s2"  GW
 SG_ JAPedObjCntAlive : 275|12@0+ (17,0) [0|65535] ""  GW
 SG_ AEB_LePedHeading : 341|6@0+ (0.05,-3) [-3|0] "rad"  GW
 SG_ AEB_RiPedHeading : 351|6@0+ (0.05,0) [0|3] "rad"  GW
 SG_ AEB_LeCyclistHeading : 345|6@0+ (0.05,-3) [-3|0] "rad"  GW
 SG_ AEB_RiCyclistHeading : 355|6@0+ (0.05,0) [0|3] "rad"  GW
 SG_ FCWAEB_longTTC : 365|6@0+ (0.1,0) [0|6.3] "s"  GW
 SG_ FCWAEB_crossingTTC : 375|6@0+ (0.1,0) [0|6.3] "s"  GW
 SG_ JAPedObjAx : 335|10@0+ (0.03125,-16) [-16|15.96875] "m/s2"  GW
 SG_ AEB_LePedDx : 399|9@0+ (0.5,0) [0|150] "m"  GW
 SG_ AEB_RiPedDx : 406|9@0+ (0.5,0) [0|150] "m"  GW
 SG_ AEB_LeCyclistDetn : 413|2@0+ (1,0) [0|3] ""  GW
 SG_ AEB_LeCyclistDx : 423|9@0+ (0.5,0) [0|150] "m"  GW
 SG_ AEB_LeCyclistTyp : 411|3@0+ (1,0) [0|7] ""  GW
 SG_ AEB_RiCyclistDetn : 430|2@0+ (1,0) [0|3] ""  GW
 SG_ AEB_RiCyclistDx : 428|9@0+ (0.5,0) [0|150] "m"  GW
 SG_ AEB_RiCyclistTyp : 435|3@0+ (1,0) [0|7] ""  GW

BO_ 696 ACC_FD4: 64 FR
 SG_ AEBObjID : 7|8@0+ (1,0) [0|255] ""  GW
 SG_ AEBObjExist : 15|6@0+ (0.015625,0) [0|0.984375] "%"  GW
 SG_ AEBObjVideoCfmd : 9|1@0+ (1,0) [0|1] ""  GW
 SG_ AEBObjVx : 23|12@0+ (0.0625,-128) [-128|127] "m/s"  GW
 SG_ AEBObjDx : 27|12@0+ (0.0625,0) [0|255.9375] "m"  GW
 SG_ AEBObjCntAlive : 47|12@0+ (17,0) [0|65535] ""  GW
 SG_ AEBObjDy : 50|11@0+ (0.125,-128) [-128|127.875] "m"  GW
 SG_ AEBObjState : 71|3@0+ (1,0) [0|7] ""  GW
 SG_ AEBObjObstcl : 68|5@0+ (0.03125,0) [0|0.96875] "%"  GW
 SG_ AEBObjVy : 79|10@0+ (0.125,-64) [-64|63.875] "m/s"  GW
 SG_ CyclistObjExist : 85|6@0+ (0.015625,0) [0|0.984375] "%"  GW
 SG_ AEBObjAx : 95|10@0+ (0.03125,-16) [-16|15.96875] "m/s2"  GW
 SG_ AEBObjAy : 101|10@0+ (0.03125,-16) [-16|15.96875] "m/s2"  GW
 SG_ CyclistObjDx : 107|12@0+ (0.0625,0) [0|255.9375] "m"  GW
 SG_ CyclistObjID : 127|8@0+ (1,0) [0|255] ""  GW
 SG_ CyclistObjObstcl : 135|5@0+ (0.03125,0) [0|0.96875] "%"  GW
 SG_ CyclistObjDy : 130|11@0+ (0.125,-128) [-128|127.875] "m"  GW
 SG_ CyclistObjVx : 151|12@0+ (0.0625,-128) [-128|127] "m/s"  GW
 SG_ CyclistObjCntAlive : 155|12@0+ (17,0) [0|65535] ""  GW
 SG_ CyclistObjVy : 175|10@0+ (0.125,-64) [-64|63.875] "m/s"  GW
 SG_ CyclistObjState : 181|3@0+ (1,0) [0|7] ""  GW
 SG_ CyclistObjVideoCfmd : 178|1@0+ (1,0) [0|1] ""  GW
 SG_ CyclistObjAx : 177|10@0+ (0.03125,-16) [-16|15.96875] "m/s2"  GW
 SG_ CyclistObjAy : 199|10@0+ (0.03125,-16) [-16|15.96875] "m/s2"  GW
 SG_ PedObjExist : 205|6@0+ (0.015625,0) [0|0.984375] "%"  GW
 SG_ PedObjID : 215|8@0+ (1,0) [0|255] ""  GW
 SG_ PedObjObstcl : 223|5@0+ (0.03125,0) [0|0.96875] "%"  GW
 SG_ PedObjDy : 218|11@0+ (0.125,-128) [-128|127.875] "m"  GW
 SG_ PedObjDx : 239|12@0+ (0.0625,0) [0|255.9375] "m"  GW
 SG_ PedObjVx : 243|12@0+ (0.0625,-128) [-128|127] "m/s"  GW
 SG_ PedObjVy : 263|10@0+ (0.125,-64) [-64|63.875] "m/s"  GW
 SG_ PedObjVideoCfmd : 269|1@0+ (1,0) [0|1] ""  GW
 SG_ ACCTgtObjDx : 267|12@0+ (0.0625,0) [0|255.9375] "m"  GW
 SG_ PedObjAy : 287|10@0+ (0.03125,-16) [-16|15.96875] "m/s2"  GW
 SG_ PedObjCntAlive : 293|12@0+ (17,0) [0|65535] ""  GW
 SG_ PedObjAx : 297|10@0+ (0.03125,-16) [-16|15.96875] "m/s2"  GW
 SG_ ACCTgtObjID : 319|8@0+ (1,0) [0|255] ""  GW
 SG_ ACCTgtObjObstcl : 327|5@0+ (0.03125,0) [0|0.96875] "%"  GW
 SG_ ACCTgtObjDy : 322|11@0+ (0.125,-128) [-128|127.875] "m"  GW
 SG_ ACCTgtObjExist : 343|6@0+ (0.015625,0) [0|0.984375] "%"  GW
 SG_ ACCTgtObjVy : 337|10@0+ (0.125,-64) [-64|63.875] "m/s"  GW
 SG_ ACCTgtObjVx : 359|12@0+ (0.0625,-128) [-128|127] "m/s"  GW
 SG_ ACCTgtObjAx : 363|10@0+ (0.03125,-16) [-16|15.96875] "m/s2"  GW
 SG_ ACCTgtObjAy : 369|10@0+ (0.03125,-16) [-16|15.96875] "m/s2"  GW
 SG_ ACCTgtObjState : 391|3@0+ (1,0) [0|7] ""  GW
 SG_ ACCTgtObjVideoCfmd : 388|1@0+ (1,0) [0|1] ""  GW
 SG_ ACCTgtObjCntAlive : 387|12@0+ (17,0) [0|65536] ""  GW
 SG_ RadarHorMisalign : 407|12@0+ (0.0001,-0.2048) [-0.2048|0.2047] "rad"  GW
 SG_ HandsoffDetd : 411|2@0+ (1,0) [0|3] ""  GW
 SG_ DrvgOnHiWay : 409|2@0+ (1,0) [0|3] ""  GW
 SG_ RoadCrvt : 423|10@0+ (0.00032,-0.16352) [-0.16352|0.16352] ""  GW
 SG_ SpdLimitDst : 429|6@0+ (10,0) [0|600] "m"  GW
 SG_ RoadCrvtFar : 439|10@0+ (0.00032,-0.16352) [-0.16352|0.16352] ""  GW
 SG_ RampDst : 445|6@0+ (10,0) [0|600] "m"  GW
 SG_ SpdLimit : 455|8@0+ (1,0) [0|255] ""  GW
 SG_ CurveDst : 463|6@0+ (10,0) [0|600] "m"  GW
 SG_ NavSpdLimUnit : 457|2@0+ (1,0) [0|3] ""  GW
 SG_ TunnelDst : 471|6@0+ (10,0) [0|600] "m"  GW
 SG_ DrvgOnRiLane : 465|2@0+ (1,0) [0|3] ""  GW
 SG_ BrdgDst : 479|6@0+ (10,0) [0|600] "m"  GW
 SG_ RadarDrvrAttentive : 473|1@0+ (1,0) [0|1] ""  GW
 SG_ ACC_DataRecReq : 487|3@0+ (1,0) [0|7] ""  GW
 SG_ ACC_SOSReq : 484|2@0+ (1,0) [0|3] ""  GW
 SG_ PedObjState : 482|3@0+ (1,0) [0|7] ""  GW
 SG_ MapDataValid : 495|1@0+ (1,0) [0|1] ""  GW
 SG_ DrvrSts : 494|3@0+ (1,0) [0|7] ""  GW
 SG_ AEBObjOverlap : 491|5@0+ (1,0) [0|1] ""  GW
 SG_ AEBObjDrvby : 502|5@0+ (1,0) [0|1] ""  GW

BO_ 707 HUT_FD1: 64 GW
 SG_ IFC_SnvtySet : 77|2@0+ (1,0) [0|3] ""  IFC,IDC_L2
 SG_ DOWSwtReq : 104|1@0+ (1,0) [0|1] ""  RSDS_R,RSDS_L
 SG_ AEB_PedSwtReq : 105|1@0+ (1,0) [0|1] ""  FR,IDC_L2
 SG_ LCASwtReq : 85|1@0+ (1,0) [0|1] ""  RSDS_R,RSDS_L
 SG_ RCTASwtReq : 84|1@0+ (1,0) [0|1] ""  RSDS_R,RSDS_L
 SG_ RCTABrkSwtReq : 83|1@0+ (1,0) [0|1] ""  RSDS_R,RSDS_L
 SG_ RCWSwtReq : 82|1@0+ (1,0) [0|1] ""  RSDS_R,RSDS_L
 SG_ FCW_SnvtySet : 81|2@0+ (1,0) [0|3] ""  FR,CR_L,CR_R,IDC_L2
 SG_ AEB_VehSwtReq : 95|1@0+ (1,0) [0|1] ""  FR,IDC_L2
 SG_ LKASwtReq : 93|1@0+ (1,0) [0|1] ""  IFC,IDC_L2
 SG_ LCKSwtReq : 92|1@0+ (1,0) [0|1] ""  IFC,IDC_L2
 SG_ ELKSwtReq : 91|1@0+ (1,0) [0|1] ""  IFC,IDC_L2
 SG_ ESS_PedSwtReq : 90|1@0+ (1,0) [0|1] ""  IFC,IDC_L2
 SG_ ESS_VehSwtReq : 89|1@0+ (1,0) [0|1] ""  IFC,IDC_L2
 SG_ LDWSwtReq : 88|1@0+ (1,0) [0|1] ""  IFC,IDC_L2
 SG_ TSRSwtReq : 102|1@0+ (1,0) [0|1] ""  IFC,IDC_L2
 SG_ TSRWarnSwtReq : 101|1@0+ (1,0) [0|1] ""  IFC,IDC_L2
 SG_ ICA_HandsOffSwtReq : 127|1@0+ (1,0) [0|1] ""  FR,IDC_L2
 SG_ ISLSwtReq : 126|1@0+ (1,0) [0|1] ""  FR,IDC_L2
 SG_ TSR_SnvtySet : 125|5@0+ (1,-15) [-15|15] "km/h"  IFC,IDC_L2
 SG_ LSSWarnFormSwtReq : 100|2@0+ (1,0) [0|3] ""  IFC,IDC_L2
 SG_ LSSSwtReq : 106|1@0+ (1,0) [0|1] ""  IFC,IDC_L2
 SG_ IntelligentEvaSwtReq : 107|1@0+ (1,0) [0|1] ""  IFC,IDC_L2
 SG_ NavVehToTrafEyeDist : 239|10@0+ (1,0) [0|1023] ""  IFC,IDC_L2
 SG_ NavRoadType : 311|4@0+ (1,0) [0|15] ""  IFC,IDC_L2
 SG_ NavSpdLimType : 307|2@0+ (1,0) [0|3] ""  IFC,IDC_L2
 SG_ NavSpdLimValue : 271|6@0+ (1,0) [0|63] ""  IFC,IDC_L2
 SG_ NavSpdLimUnit_HUT : 265|2@0+ (1,0) [0|3] ""  IFC,IDC_L2
 SG_ NavCtryType : 279|10@0+ (1,0) [0|1023] ""  IFC,IDC_L2
 SG_ NavSpdLimSignSts : 285|3@0+ (1,0) [0|7] ""  IFC,IDC_L2
 SG_ NavTSRTrafSign : 295|8@0+ (1,0) [0|255] ""  IFC,IDC_L2
 SG_ FCTASwtReq : 301|1@0+ (1,0) [0|1] ""  CR_L,CR_R
 SG_ AESSwtReq : 298|1@0+ (1,0) [0|1] ""  IFC,IDC_L2
 SG_ FCTABrkSwtReq : 300|1@0+ (1,0) [0|1] ""  CR_L,CR_R
 SG_ HWA_SwtReq : 280|1@0+ (1,0) [0|1] ""  IDC_L2
 SG_ HWA_SnvtySet : 303|2@0+ (1,0) [0|3] ""  IDC_L2
 SG_ AEB_JASwtReq : 299|1@0+ (1,0) [0|1] ""  FR,IDC_L2
 SG_ ALC_SwtReq : 296|1@0+ (1,0) [0|1] ""  IDC_L2
 SG_ ADAS_Posn_MsgTye : 327|3@0+ (1,0) [0|7] ""  IFC,IDC_L2
 SG_ ADAS_Posn_Offset : 324|13@0+ (1,0) [0|8190] "m"  IFC,IDC_L2
 SG_ ADAS_Posn_CycCnt : 343|2@0+ (1,0) [0|3] ""  IFC,IDC_L2
 SG_ ADAS_Posn_Pathldx : 341|6@0+ (1,0) [0|63] ""  IFC,IDC_L2
 SG_ ADAS_Posn_Idx : 351|2@0+ (1,0) [0|3] "m"  IFC,IDC_L2
 SG_ ADAS_Posn_PosProbb : 349|5@0+ (3.33,0) [0|100] ""  IFC,IDC_L2
 SG_ ADAS_Posn_Age : 344|9@0+ (5,0) [0|2545] "ms"  IFC,IDC_L2
 SG_ ADAS_Posn_PosConfdc : 366|3@0+ (1,0) [0|7] ""  IFC,IDC_L2
 SG_ ADAS_Posn_CurLane : 363|3@0+ (1,0) [0|7] ""  IFC,IDC_L2
 SG_ ADAS_Posn_Spd : 360|9@0+ (0.2,-12.8) [-12.8|89.2] "m/s"  IFC,IDC_L2
 SG_ ADAS_Posn_Rehead : 383|8@0+ (3,0) [0|358.583] ""  IFC,IDC_L2
 SG_ FreshnessValue_HUT_FD1 : 455|16@0+ (1,0) [0|65535] ""  FR,IDC_L2
 SG_ MAC_Check_HUT_FD1 : 471|48@0+ (1,0) [0|281474976710655] ""  FR,IDC_L2

BO_ 714 DDCM1: 8 GW
 SG_ RSDS_Driver_LED_Sts : 9|1@0+ (1,0) [0|1] ""  RSDS_R,RSDS_L
 SG_ DrvMirrFold_UnfoldSts : 23|1@0+ (1,0) [0|1] ""  HAP,HAP_PAS

BO_ 717 PDCM1: 8 GW
 SG_ PassMirrFold_UnfoldSts : 12|1@0+ (1,0) [0|1] ""  HAP,HAP_PAS
 SG_ RSDS_Pass_LED_Sts : 8|1@0+ (1,0) [0|1] ""  RSDS_R,RSDS_L

BO_ 719 IFC_FD3: 64 IFC
 SG_ Checksum_IFC7 : 71|8@0+ (1,0) [0|255] "" Vector__XXX
 SG_ TSRResp : 79|1@0+ (1,0) [0|1] ""  GW
 SG_ TSRSpdLimUnit : 78|2@0+ (1,0) [0|3] ""  GW
 SG_ TSRSpdLim : 87|6@0+ (1,0) [0|63] ""  GW
 SG_ TSRSpdLimCfdc : 76|2@0+ (1,0) [0|3] ""  GW
 SG_ TSRSts : 74|3@0+ (1,0) [0|7] ""  GW
 SG_ TSRSpdLimSts : 81|2@0+ (1,0) [0|3] ""  GW
 SG_ TSRTrfcSignValCfdc : 95|2@0+ (1,0) [0|3] ""  GW
 SG_ TSRTrfcSignVal : 93|8@0+ (1,0) [0|255] ""  GW
 SG_ TSRSpdLimWarn : 101|1@0+ (1,0) [0|1] ""  GW
 SG_ TSRWarnResp : 108|1@0+ (1,0) [0|1] ""  GW
 SG_ TSR_Snvty : 100|5@0+ (1,-15) [-15|15] "km/h"  GW
 SG_ HMA_Sts : 127|3@0+ (1,0) [0|7] ""  GW
 SG_ HMA_HibeamReq : 113|2@0+ (1,0) [0|3] ""  GW
 SG_ RollingCounter_IFC7 : 123|4@0+ (1,0) [0|15] "" Vector__XXX

BO_ 728 HUT23: 8 GW
 SG_ ADAS_Stub_MsgTyp : 7|3@0+ (1,0) [0|7] ""  IFC,IDC_L2
 SG_ ADAS_Stub_Offset : 4|13@0+ (1,0) [0|8190] "m"  IFC,IDC_L2
 SG_ ADAS_Stub_CycCnt : 23|2@0+ (1,0) [0|3] ""  IFC,IDC_L2
 SG_ ADAS_Stub_PathIdx : 21|6@0+ (1,0) [0|63] ""  IFC,IDC_L2
 SG_ ADAS_Stub_StubPathIdx : 31|6@0+ (1,0) [0|63] ""  IFC,IDC_L2
 SG_ ADAS_Stub_Retr : 25|1@0+ (1,0) [0|1] ""  IFC,IDC_L2
 SG_ ADAS_Stub_Update : 24|1@0+ (1,0) [0|1] ""  IFC,IDC_L2
 SG_ ADAS_Stub_RelProbb : 39|5@0+ (1,0) [0|100] ""  IFC,IDC_L2
 SG_ ADAS_Stub_FuncRoadClass : 34|3@0+ (1,0) [0|7] ""  IFC,IDC_L2
 SG_ ADAS_Stub_PartOfCalcRoute : 47|2@0+ (1,0) [0|3] ""  IFC,IDC_L2
 SG_ ADAS_Stub_CmplxInsct : 45|2@0+ (1,0) [0|3] ""  IFC,IDC_L2
 SG_ ADAS_Stub_FormOfWay : 43|4@0+ (1,0) [0|15] ""  IFC,IDC_L2
 SG_ ADAS_Stub_TurnAngl : 55|8@0+ (3,0) [0|358.583] ""  IFC,IDC_L2
 SG_ ADAS_Stub_LastStub : 63|1@0+ (1,0) [0|1] ""  IFC,IDC_L2
 SG_ ADAS_Stub_RtOfWay : 62|2@0+ (1,0) [0|3] ""  IFC,IDC_L2
 SG_ ADAS_Stub_NumOfLaneOppDir : 60|2@0+ (1,0) [0|3] ""  IFC,IDC_L2
 SG_ ADAS_Stub_NumOfLaneDrvDir : 58|3@0+ (1,0) [0|7] ""  IFC,IDC_L2

BO_ 730 HUT22: 8 GW
 SG_ ADAS_Seg_MsgTyp : 7|3@0+ (1,0) [0|7] ""  IFC,IDC_L2
 SG_ ADAS_Seg_Offset : 4|13@0+ (1,0) [0|8190] "m"  IFC,IDC_L2
 SG_ ADAS_Seg_CycCnt : 23|2@0+ (1,0) [0|3] ""  IFC,IDC_L2
 SG_ ADAS_Seg_PathIdx : 21|6@0+ (1,0) [0|63] "0"  IFC,IDC_L2
 SG_ ADAS_Seg_Tunnel : 31|2@0+ (1,0) [0|3] ""  IFC,IDC_L2
 SG_ ADAS_Seg_Brdg : 29|2@0+ (1,0) [0|3] ""  IFC,IDC_L2
 SG_ ADAS_Seg_BuildUpArea : 27|2@0+ (1,0) [0|3] ""  IFC,IDC_L2
 SG_ ADAS_Seg_Retr : 25|1@0+ (1,0) [0|1] ""  IFC,IDC_L2
 SG_ ADAS_Seg_Update : 24|1@0+ (1,0) [0|1] ""  IFC,IDC_L2
 SG_ ADAS_Seg_RelProbb : 39|5@0+ (1,0) [0|100] ""  IFC,IDC_L2
 SG_ ADAS_Seg_FuncRoadClass : 34|3@0+ (1,0) [0|7] ""  IFC,IDC_L2
 SG_ ADAS_Seg_PartOfCalcRoute : 47|2@0+ (1,0) [0|3] ""  IFC,IDC_L2
 SG_ ADAS_Seg_CmplxInsct : 45|2@0+ (1,0) [0|3] ""  IFC,IDC_L2
 SG_ ADAS_Seg_FormOfWay : 43|4@0+ (1,0) [0|15] ""  IFC,IDC_L2
 SG_ ADAS_Seg_EffSpdLmt : 55|5@0+ (1,0) [0|31] ""  IFC,IDC_L2
 SG_ ADAS_Seg_EffSpdLmtTyp : 50|3@0+ (1,0) [0|7] ""  IFC,IDC_L2
 SG_ ADAS_Seg_DivideRoad : 62|2@0+ (1,0) [0|3] ""  IFC,IDC_L2
 SG_ ADAS_Seg_NumOfLaneOppDir : 60|2@0+ (1,0) [0|3] ""  IFC,IDC_L2
 SG_ ADAS_Seg_NumOfLaneDrvDir : 58|3@0+ (1,0) [0|7] ""  IFC,IDC_L2

BO_ 733 HUT21: 8 GW
 SG_ ADAS_ProfShort_MsgTyp : 7|3@0+ (1,0) [0|7] ""  IFC,IDC_L2
 SG_ ADAS_ProfShort_Offset : 4|13@0+ (1,0) [0|8190] "m"  IFC,IDC_L2
 SG_ ADAS_ProfShort_CycCnt : 23|2@0+ (1,0) [0|3] ""  IFC,IDC_L2
 SG_ ADAS_ProfShort_PathIdx : 21|6@0+ (1,0) [0|63] ""  IFC,IDC_L2
 SG_ ADAS_ProfShort_ProfTyp : 31|5@0+ (1,0) [0|31] ""  IFC,IDC_L2
 SG_ ADAS_ProfShort_CtrlPoint : 26|1@0+ (1,0) [0|1] ""  IFC,IDC_L2
 SG_ ADAS_ProfShort_Retr : 25|1@0+ (1,0) [0|1] ""  IFC,IDC_L2
 SG_ ADAS_ProfShort_Update : 24|1@0+ (1,0) [0|1] ""  IFC,IDC_L2
 SG_ ADAS_ProfShort_AccurClass : 39|2@0+ (1,0) [0|3] ""  IFC,IDC_L2
 SG_ ADAS_ProfShort_Dist1 : 37|10@0+ (1,0) [0|1022] "m"  IFC,IDC_L2
 SG_ ADAS_ProfShort_Value0 : 43|10@0+ (1,0) [0|1022] ""  IFC,IDC_L2
 SG_ ADAS_ProfShort_Value1 : 49|10@0+ (1,0) [0|1022] ""  IFC,IDC_L2

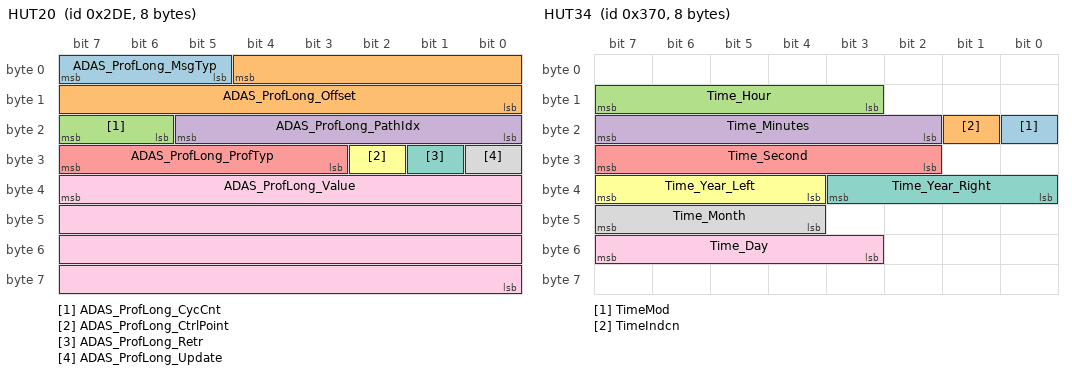
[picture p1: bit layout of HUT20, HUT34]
BO_ 734 HUT20: 8 GW
 SG_ ADAS_ProfLong_MsgTyp : 7|3@0+ (1,0) [0|7] ""  IFC,IDC_L2
 SG_ ADAS_ProfLong_Offset : 4|13@0+ (1,0) [0|8190] "m"  IFC,IDC_L2
 SG_ ADAS_ProfLong_CycCnt : 23|2@0+ (1,0) [0|3] ""  IFC,IDC_L2
 SG_ ADAS_ProfLong_PathIdx : 21|6@0+ (1,0) [0|63] ""  IFC,IDC_L2
 SG_ ADAS_ProfLong_ProfTyp : 31|5@0+ (1,0) [0|31] ""  IFC,IDC_L2
 SG_ ADAS_ProfLong_CtrlPoint : 26|1@0+ (1,0) [0|1] ""  IFC,IDC_L2
 SG_ ADAS_ProfLong_Retr : 25|1@0+ (1,0) [0|1] ""  IFC,IDC_L2
 SG_ ADAS_ProfLong_Update : 24|1@0+ (1,0) [0|1] ""  IFC,IDC_L2
 SG_ ADAS_ProfLong_Value : 39|32@0+ (1,0) [0|4294967295] ""  IFC,IDC_L2

BO_ 743 BCM10: 16 GW
 SG_ Checksum_BCM10 : 7|8@0+ (1,0) [0|255] ""  IDC_L3
 SG_ HiBeamWorkCmd : 11|1@0+ (1,0) [0|1] ""  IDC_L3
 SG_ LowBeamWorkCmd : 10|1@0+ (1,0) [0|1] ""  IDC_L3
 SG_ RTurnLmpWorkCmd : 9|1@0+ (1,0) [0|1] ""  IDC_L3
 SG_ LTurnLampWorkCmd : 8|1@0+ (1,0) [0|1] ""  IDC_L3
 SG_ FFogLmpAsstSts : 23|1@0+ (1,0) [0|1] ""  IDC_L3
 SG_ HornWorkCmd : 22|1@0+ (1,0) [0|1] ""  IDC_L3
 SG_ RDayRunngLmpWorkCmd : 21|1@0+ (1,0) [0|1] ""  IDC_L3
 SG_ LDayRunngLmpWorkCmd : 20|1@0+ (1,0) [0|1] ""  IDC_L3
 SG_ RFFogLmpWorkCmd : 19|1@0+ (1,0) [0|1] ""  IDC_L3
 SG_ LFFogLmpWorkCmd : 18|1@0+ (1,0) [0|1] ""  IDC_L3
 SG_ AsstPosnLmpSts : 31|1@0+ (1,0) [0|1] ""  IDC_L3
 SG_ ChildLockProtWorkCmd : 30|2@0+ (1,0) [0|3] ""  IDC_L3
 SG_ LicPlateLmpWorkCmd : 27|1@0+ (1,0) [0|1] ""  IDC_L3
 SG_ ReversLampWorkCmd : 26|1@0+ (1,0) [0|1] ""  IDC_L3
 SG_ BrkLmpWorkCmd : 25|1@0+ (1,0) [0|1] ""  IDC_L3
 SG_ RFogLmpWorkCmd : 24|1@0+ (1,0) [0|1] ""  IDC_L3
 SG_ LasHdLmpWorkCmd : 37|1@0+ (1,0) [0|1] ""  IDC_L3
 SG_ LCornrLmpWorkCmd : 36|1@0+ (1,0) [0|1] ""  IDC_L3
 SG_ RCornrLmpWorkCmd : 35|1@0+ (1,0) [0|1] ""  IDC_L3
 SG_ RHorseRaceLmpWorkCmd : 34|1@0+ (1,0) [0|1] ""  IDC_L3
 SG_ LHorseRaceLmpWorkCmd : 33|1@0+ (1,0) [0|1] ""  IDC_L3
 SG_ TrunkLmpWorkCmd : 32|1@0+ (1,0) [0|1] ""  IDC_L3
 SG_ Rollingcounter_BCM10 : 59|4@0+ (1,0) [0|15] ""  IDC_L3
 SG_ FreshnessValue_BCM10 : 71|16@0+ (1,0) [0|65535] ""  IDC_L3
 SG_ MAC_Check_BCM10 : 87|48@0+ (1,0) [0|281474976710655] ""  IDC_L3

BO_ 745 HUT_FD3: 64 GW
 SG_ HUT_OD_Obj7_ID : 15|4@0+ (1,0) [0|9] ""  HAP_PAS
 SG_ HUT_OD_Obj7_type : 23|3@0+ (1,0) [0|7] ""  HAP_PAS
 SG_ HUT_OD_Obj7_Confidence : 11|4@0+ (0.1,0) [0|1] ""  HAP_PAS
 SG_ HUT_OD_Obj7_width : 20|7@0+ (0.1,0) [0|12.6] "m"  HAP_PAS
 SG_ HUT_OD_Obj7_Ground_Pos_X : 39|12@0+ (0.01,0) [0|40] "m"  HAP_PAS
 SG_ HUT_OD_Obj7_Ground_Pos_Y : 43|12@0+ (0.01,-20) [-20|20] "m"  HAP_PAS
 SG_ HUT_OD_WorkSts : 113|2@0+ (1,0) [0|3] ""  HAP_PAS
 SG_ HUT_OD_Obj_Timestamp : 79|16@0+ (1,0) [0|65535] "ms"  HAP_PAS
 SG_ HUT_FSD1_distance : 95|6@0+ (0.1,0) [0|6] "m"  HAP_PAS
 SG_ HUT_FSD2_distance : 89|6@0+ (0.1,0) [0|6] "m"  HAP_PAS
 SG_ HUT_FSD3_distance : 99|6@0+ (0.1,0) [0|6] "m"  HAP_PAS
 SG_ HUT_FSD4_distance : 109|6@0+ (0.1,0) [0|6] "m"  HAP_PAS
 SG_ HUT_FSD5_distance : 119|6@0+ (0.1,0) [0|6] "m"  HAP_PAS
 SG_ HUT_FSD6_distance : 143|6@0+ (0.1,0) [0|6] "m"  HAP_PAS
 SG_ HUT_FSD7_distance : 137|6@0+ (0.1,0) [0|6] "m"  HAP_PAS
 SG_ HUT_FSD8_distance : 147|6@0+ (0.1,0) [0|6] "m"  HAP_PAS
 SG_ HUT_FSD9_distance : 157|6@0+ (0.1,0) [0|6] "m"  HAP_PAS
 SG_ HUT_FSD10_distance : 167|6@0+ (0.1,0) [0|6] "m"  HAP_PAS
 SG_ HUT_FSD11_distance : 161|6@0+ (0.1,0) [0|6] "m"  HAP_PAS
 SG_ HUT_FSD12_distance : 171|6@0+ (0.1,0) [0|6] "m"  HAP_PAS
 SG_ HUT_FSD13_distance : 181|6@0+ (0.1,0) [0|6] "m"  HAP_PAS
 SG_ HUT_FSD14_distance : 207|6@0+ (0.1,0) [0|6] "m"  HAP_PAS
 SG_ HUT_FSD15_distance : 201|6@0+ (0.1,0) [0|6] "m"  HAP_PAS
 SG_ HUT_FSD16_distance : 211|6@0+ (0.1,0) [0|6] "m"  HAP_PAS
 SG_ HUT_FSD17_distance : 221|6@0+ (0.1,0) [0|6] "m"  HAP_PAS
 SG_ HUT_FSD18_distance : 231|6@0+ (0.1,0) [0|6] "m"  HAP_PAS

BO_ 748 DVR_FD1: 64 GW
 SG_ DVR_360VideoCaptureReq : 9|1@0+ (1,0) [0|1] ""  HAP

BO_ 762 HCU_PT4: 8 GW
 SG_ HCU_RdyLmpSts : 37|1@0+ (1,0) [0|1] ""  HC

BO_ 769 ECM_FD3: 64 GW
 SG_ MaxEngTrqNorm : 87|7@0+ (5,0) [0|510] "Nm"  FR,HAP,IDC_L2,IDC_L3
 SG_ EngLimpHomeSts : 115|1@0+ (1,0) [0|1] ""  FR,IDC_L2,IDC_L3

BO_ 778 RSDS_FD2: 64 RSDS_R
 SG_ RCTA_B_TTC : 15|6@0+ (0.1,0) [0|6.3] "s"  GW
 SG_ BSD_LCA_Left_TTC : 9|6@0+ (0.1,0) [0|6.3] "s"  GW
 SG_ BSD_LCA_Right_TTC : 19|6@0+ (0.1,0) [0|6.3] "s"  GW
 SG_ RCW_TTC : 29|6@0+ (0.1,0) [0|6.3] "s"  GW
 SG_ RSDS_LeTgt_01 : 79|1@0+ (1,0) [0|1] ""  GW
 SG_ RSDS_LeTgt_01_dx : 87|10@0+ (0.1,-90) [-90|5] "m"  GW
 SG_ RSDS_LeTgt_01_dy : 78|7@0+ (0.1,0) [0|8] "m"  GW
 SG_ RSDS_LeTgt_02 : 93|1@0+ (1,0) [0|1] ""  GW
 SG_ RSDS_LeTgt_02_dx : 92|10@0+ (0.1,-90) [-90|5] "m"  GW
 SG_ RSDS_LeTgt_02_dy : 98|7@0+ (0.1,0) [0|8] "m"  GW
 SG_ RSDS_RiTgt_01 : 107|1@0+ (1,0) [0|1] ""  GW
 SG_ RSDS_RiTgt_01_dx : 106|10@0+ (0.1,-90) [-90|5] "m"  GW
 SG_ RSDS_RiTgt_01_dy : 143|7@0+ (0.1,-8) [-8|0] "m"  GW
 SG_ RSDS_RiTgt_02 : 136|1@0+ (1,0) [0|1] ""  GW
 SG_ RSDS_RiTgt_02_dx : 151|10@0+ (0.1,-90) [-90|5] "m"  GW
 SG_ RSDS_RiTgt_02_dy : 157|7@0+ (0.1,-8) [-8|0] "m"  GW
 SG_ RSDS_MidTgt_01 : 166|1@0+ (1,0) [0|1] ""  GW
 SG_ RSDS_MidTgt_01_dx : 165|10@0+ (0.1,-90) [-90|5] "m"  GW
 SG_ RSDS_MidTgt_01_dy : 171|7@0+ (0.1,-4) [-4|4] "m"  GW
 SG_ RSDS_MidTgt_02 : 180|1@0+ (1,0) [0|1] ""  GW
 SG_ RSDS_MidTgt_02_dx : 207|10@0+ (0.1,-90) [-90|5] "m"  GW
 SG_ RSDS_MidTgt_02_dy : 213|7@0+ (0.1,-4) [-4|4] "m"  GW

BO_ 793 BCM1: 16 GW
 SG_ TrunkSts : 23|1@0+ (1,0) [0|1] ""  HAP,HAP_PAS,IDC_L3
 SG_ DrvDoorSts : 22|1@0+ (1,0) [0|1] ""  IFC,FR,RSDS_R,RSDS_L,HAP,HAP_PAS,CR_L,CR_R,IDC_L2,IDC_L3
 SG_ LRDoorSts : 21|1@0+ (1,0) [0|1] ""  IFC,FR,RSDS_R,RSDS_L,HAP,HAP_PAS,IDC_L2,IDC_L3
 SG_ PassengerDoorSts : 20|1@0+ (1,0) [0|1] ""  IFC,FR,RSDS_R,RSDS_L,HAP,HAP_PAS,IDC_L2,IDC_L3
 SG_ RRDoorSts : 19|1@0+ (1,0) [0|1] ""  IFC,FR,RSDS_R,RSDS_L,HAP,HAP_PAS,IDC_L2,IDC_L3
 SG_ WindshldWiprActvSts : 17|1@0+ (1,0) [0|1] ""  IFC,FR,IDC_L2,IDC_L3
 SG_ BrkPedalSts_BCM : 16|1@0+ (1,0) [0|1] ""  IDC_L3
 SG_ BrkPedalFailSts : 31|1@0+ (1,0) [0|1] ""  IDC_L3
 SG_ ParkBrkSts : 46|2@0+ (1,0) [0|3] ""  IDC_L3
 SG_ ReversGearSts : 42|2@0+ (1,0) [0|3] ""  IDC_L3
 SG_ PosnLightReq : 61|1@0+ (1,0) [0|1] ""  IDC_L3
 SG_ RLSFailSts : 63|1@0+ (1,0) [0|1] ""  IDC_L3
 SG_ FreshnessValue_BCM1 : 71|16@0+ (1,0) [0|65535] ""  FR,IDC_L2,IDC_L3
 SG_ MAC_Check_BCM1 : 87|48@0+ (1,0) [0|281474976710655] ""  FR,IDC_L2,IDC_L3

BO_ 833 TPMS1: 16 GW
 SG_ FLTirePressIndSts : 15|3@0+ (1,0) [0|4] ""  IDC_L3
 SG_ FRTirePressIndSts : 12|3@0+ (1,0) [0|4] ""  IDC_L3
 SG_ TirePressSysFailrIndcn : 9|2@0+ (1,0) [0|1] ""  IDC_L3
 SG_ RLTirePressIndSts : 23|3@0+ (1,0) [0|4] ""  IDC_L3
 SG_ RRTirePressIndSts : 20|3@0+ (1,0) [0|4] ""  IDC_L3
 SG_ FLTireTempSts : 31|2@0+ (1,0) [0|3] ""  IDC_L3
 SG_ FRTireTempSts : 29|2@0+ (1,0) [0|3] ""  IDC_L3
 SG_ RLTireTempSts : 27|2@0+ (1,0) [0|3] ""  IDC_L3
 SG_ RRTireTempSts : 25|2@0+ (1,0) [0|3] ""  IDC_L3
 SG_ TPMS_AutoLoctSts : 39|4@0+ (1,0) [0|5] ""  IDC_L3
 SG_ FreshnessValue_TPMS1 : 71|16@0+ (1,0) [0|65535] ""  IDC_L3
 SG_ MAC_Check_TPMS1 : 87|48@0+ (1,0) [0|281474976710655] ""  IDC_L3

BO_ 837 BCM3: 16 GW
 SG_ BCM_HWPWorkSts : 42|2@0+ (1,0) [0|3] ""  IDC_L3
 SG_ HazardLmpSwtSts : 8|1@0+ (1,0) [0|1] ""  IFC,FR,IDC_L2,IDC_L3
 SG_ FreshnessValue_BCM3 : 71|16@0+ (1,0) [0|65535] ""  FR,IDC_L2,IDC_L3
 SG_ MAC_Check_BCM3 : 87|48@0+ (1,0) [0|281474976710655] ""  FR,IDC_L2,IDC_L3

BO_ 846 ACC_FD5: 16 FR
 SG_ Sync_CRC : 15|8@0+ (1,0) [0|255] ""  CR_L,CR_R
 SG_ Sync_OVS : 25|2@0+ (1,0) [0|3] ""  CR_L,CR_R
 SG_ Sync_Resd : 31|5@0+ (1,0) [0|31] ""  CR_L,CR_R
 SG_ Sync_Counter : 19|4@0+ (1,0) [0|15] ""  CR_L,CR_R
 SG_ Sync_SGW : 26|1@0+ (1,0) [0|1] ""  CR_L,CR_R
 SG_ Sync_SyncTime : 39|32@0+ (1,0) [0|4294967295] ""  CR_L,CR_R
 SG_ Sync_TimeDomain : 23|4@0+ (1,0) [0|15] ""  CR_L,CR_R
 SG_ Sync_Type : 7|8@0+ (1,0) [0|255] ""  CR_L,CR_R

BO_ 849 ABM1: 16 GW
 SG_ CheckSum_ABM1 : 7|8@0+ (1,0) [0|255] ""  FR,HAP,HAP_PAS,IDC_L2,IDC_L3
 SG_ DrvSBR : 11|1@0+ (1,0) [0|1] ""  IFC,FR,HAP,HAP_PAS,IDC_L2,IDC_L3
 SG_ PassSBR : 9|1@0+ (1,0) [0|1] ""  IFC,FR,HAP,HAP_PAS,IDC_L2,IDC_L3
 SG_ PABSwtSts : 15|1@0+ (1,0) [0|1] ""  IDC_L3
 SG_ SecRowLSBR : 14|1@0+ (1,0) [0|1] ""  IDC_L3
 SG_ AirbFailLmpCmd : 13|1@0+ (1,0) [0|1] ""  IDC_L3
 SG_ SecRowMidSBR : 12|1@0+ (1,0) [0|1] ""  IDC_L3
 SG_ SecRowRSBR : 10|1@0+ (1,0) [0|1] ""  IDC_L3
 SG_ PassSBR_Visual : 27|2@0+ (1,0) [0|3] ""  IDC_L3
 SG_ DrvSBR_Visual : 25|2@0+ (1,0) [0|3] ""  IDC_L3
 SG_ SecRowLSBR_Visual : 29|2@0+ (1,0) [0|3] ""  IDC_L3
 SG_ SecRowMidSBR_Visual : 31|2@0+ (1,0) [0|3] ""  IDC_L3
 SG_ SecRowRSBR_Visual : 33|2@0+ (1,0) [0|3] ""  IDC_L3
 SG_ CrashOutputSts : 23|8@0+ (1,0) [0|18] ""  IDC_L3
 SG_ RollingCounter_ABM1 : 59|4@0+ (1,0) [0|15] ""  FR,HAP,HAP_PAS,IDC_L2,IDC_L3
 SG_ FreshnessValue_ABM1 : 71|16@0+ (1,0) [0|65535] ""  FR,IDC_L2,IDC_L3
 SG_ MAC_Check_ABM1 : 87|48@0+ (1,0) [0|281474976710655] ""  FR,IDC_L2,IDC_L3

BO_ 880 HUT34: 8 GW
 SG_ TimeMod : 16|1@0+ (1,0) [0|1] ""  IFC,HAP,HAP_PAS,IDC_L2,IDC_L3
 SG_ TimeIndcn : 17|1@0+ (1,0) [0|1] ""  IFC,HAP,HAP_PAS,IDC_L2,IDC_L3
 SG_ Time_Hour : 15|5@0+ (1,0) [0|31] ""  IFC,HC,FR,RSDS_R,RSDS_L,HAP,HAP_PAS,CR_L,CR_R,IDC_L2,IDC_L3
 SG_ Time_Minutes : 23|6@0+ (1,0) [0|63] ""  IFC,HC,FR,RSDS_R,RSDS_L,HAP,HAP_PAS,CR_L,CR_R,IDC_L2,IDC_L3
 SG_ Time_Second : 31|6@0+ (1,0) [0|63] ""  IFC,FR,RSDS_R,RSDS_L,HAP,HAP_PAS,CR_L,CR_R,IDC_L2,IDC_L3
 SG_ Time_Year_Left : 39|4@0+ (1,0) [0|15] ""  IFC,HC,FR,RSDS_R,RSDS_L,HAP,HAP_PAS,CR_L,CR_R,IDC_L2,IDC_L3
 SG_ Time_Year_Right : 35|4@0+ (1,0) [0|15] ""  IFC,HC,FR,RSDS_R,RSDS_L,HAP,HAP_PAS,CR_L,CR_R,IDC_L2,IDC_L3
 SG_ Time_Month : 47|4@0+ (1,0) [0|15] ""  IFC,HC,FR,RSDS_R,RSDS_L,HAP,HAP_PAS,CR_L,CR_R,IDC_L2,IDC_L3
 SG_ Time_Day : 55|5@0+ (1,0) [0|31] ""  IFC,HC,FR,RSDS_R,RSDS_L,HAP,HAP_PAS,CR_L,CR_R,IDC_L2,IDC_L3

BO_ 901 AC2: 8 GW
 SG_ ACAmbTemp : 23|8@0+ (0.5,-40) [-40|86.5] "буC"  IFC,FR,HAP,HAP_PAS,IDC_L2,IDC_L3
 SG_ ACFrntBlwrSpd : 11|4@0+ (1,0) [0|15] ""  IDC_L3

BO_ 1001 T_Box_FD3: 16 GW
 SG_ T_Box_SysErrSts : 7|5@0+ (1,0) [0|1] ""  FR,IDC_L2
 SG_ FreshnessValue_T_Box_FD3 : 71|16@0+ (1,0) [0|65535] ""  FR,IDC_L2
 SG_ MAC_Check_T_Box_FD3 : 87|48@0+ (1,0) [0|281474976710655] ""  FR,IDC_L2

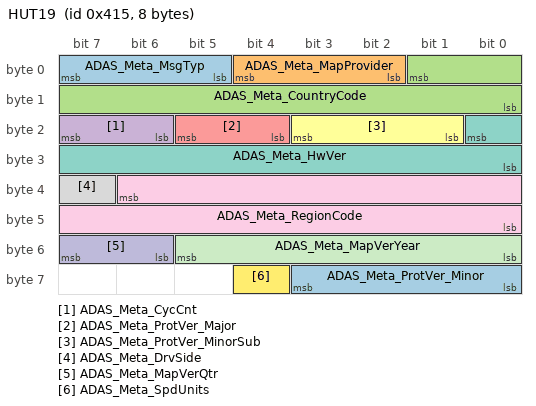
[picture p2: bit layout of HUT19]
BO_ 1045 HUT19: 8 GW
 SG_ ADAS_Meta_MsgTyp : 7|3@0+ (1,0) [0|7] ""  IFC,IDC_L2
 SG_ ADAS_Meta_MapProvider : 4|3@0+ (1,0) [0|7] ""  IFC,IDC_L2
 SG_ ADAS_Meta_CountryCode : 1|10@0+ (1,0) [0|1023] ""  IFC,IDC_L2
 SG_ ADAS_Meta_CycCnt : 23|2@0+ (1,0) [0|3] ""  IFC,IDC_L2
 SG_ ADAS_Meta_ProtVer_Major : 21|2@0+ (1,0) [0|3] ""  IFC,IDC_L2
 SG_ ADAS_Meta_ProtVer_MinorSub : 19|3@0+ (1,0) [0|7] ""  IFC,IDC_L2
 SG_ ADAS_Meta_HwVer : 16|9@0+ (1,0) [0|511] ""  IFC,IDC_L2
 SG_ ADAS_Meta_DrvSide : 39|1@0+ (1,0) [0|1] ""  IFC,IDC_L2
 SG_ ADAS_Meta_RegionCode : 38|15@0+ (1,0) [0|32767] ""  IFC,IDC_L2
 SG_ ADAS_Meta_MapVerQtr : 55|2@0+ (1,0) [0|3] ""  IFC,IDC_L2
 SG_ ADAS_Meta_MapVerYear : 53|6@0+ (1,0) [0|63] ""  IFC,IDC_L2
 SG_ ADAS_Meta_SpdUnits : 60|1@0+ (1,0) [0|1] ""  IFC,IDC_L2
 SG_ ADAS_Meta_ProtVer_Minor : 59|4@0+ (1,0) [0|15] ""  IFC,IDC_L2

BO_ 1305 HC_NM: 8 HC
 SG_ Destination_HC_NM : 7|8@0+ (1,0) [0|63] ""  GW,IDC_L3
 SG_ OpCode_HC_NM : 15|8@0+ (1,0) [0|63] ""  GW,IDC_L3

BO_ 1308 IDC_L3_NM: 8 IDC_L3
 SG_ Destination_IDC_L3_NM : 7|8@0+ (1,0) [0|63] ""  GW,HC,RRR,SRR_L,SRR_R
 SG_ OpCode_IDC_L3_NM : 15|8@0+ (1,0) [0|63] ""  GW,HC,RRR,SRR_L,SRR_R

BO_ 1309 RRR_NM: 8 RRR
 SG_ Destination_RRR_NM : 7|8@0+ (1,0) [0|63] ""  IDC_L3
 SG_ OpCode_RRR_NM : 15|8@0+ (1,0) [0|63] ""  IDC_L3

BO_ 1310 SRR_L_NM: 8 SRR_L
 SG_ Destination_SRR_L_NM : 7|8@0+ (1,0) [0|63] ""  IDC_L3,SRR_R
 SG_ OpCode_SRR_L_NM : 15|8@0+ (1,0) [0|63] ""  IDC_L3,SRR_R

BO_ 1311 SRR_R_NM: 8 SRR_R
 SG_ Destination_SRR_R_NM : 7|8@0+ (1,0) [0|63] ""  IDC_L3,SRR_L
 SG_ OpCode_SRR_R_NM : 15|8@0+ (1,0) [0|63] ""  IDC_L3,SRR_L

BO_ 1281 GW_NM: 8 GW
 SG_ Destination_GW_NM : 7|8@0+ (1,0) [0|63] ""  HC,IDC_L3
 SG_ OpCode_GW_NM : 15|8@0+ (1,0) [0|63] ""  HC,IDC_L3

BO_ 1888 DiagFuncReq: 8 Tester
 SG_ DiagFuncReq : 7|64@0+ (1,0) [0|1.84467440737096E+019] ""  GW,RSDS_L,RSDS_R,FR,IFC,HC,CR_L,CR_R,IDC_L2,IDC_L3,HAP,PAS,RRR,SRR_L,SRR_R

BO_ 1889 GW_Phy_Req: 8 Tester
 SG_ GW_Phy_Req : 7|64@0+ (1,0) [0|1.84467440737096E+019] ""  GW

BO_ 1902 RSDS_L_Phy_Req: 8 Tester
 SG_ RSDS_L_Phy_Req : 7|64@0+ (1,0) [0|1.84467440737096E+019] ""  GW,RSDS_L

BO_ 1903 RSDS_R_Phy_Req: 8 Tester
 SG_ RSDS_R_Phy_Req : 7|64@0+ (1,0) [0|1.84467440737096E+019] ""  GW,RSDS_R

BO_ 1906 FR_Phy_Req: 8 Tester
 SG_ FR_Phy_Req : 7|64@0+ (1,0) [0|1.84467440737096E+019] ""  GW,FR

BO_ 1914 IFC_Phy_Req: 8 Tester
 SG_ IFC_Phy_Req : 7|64@0+ (1,0) [0|1.84467440737096E+019] ""  GW,IFC

BO_ 1899 HC_Phy_Req: 8 Tester
 SG_ HC_Phy_Req : 7|64@0+ (1,0) [0|1.84467440737096E+019] ""  GW,HC

BO_ 1910 HAP_Phy_Req: 8 Tester
 SG_ HAP_Phy_Req : 7|64@0+ (1,0) [0|1.84467440737096E+019] ""  GW,HAP

BO_ 1909 PAS_Phy_Req: 8 Tester
 SG_ PAS_Phy_Req : 7|64@0+ (1,0) [0|1.84467440737096E+019] ""  GW,PAS

BO_ 1550 CR_L_Phy_Req: 8 Tester
 SG_ CR_L_Phy_Req : 7|64@0+ (1,0) [0|1.84467440737096E+019] ""  GW,CR_L

BO_ 1551 CR_R_Phy_Req: 8 Tester
 SG_ CR_R_Phy_Req : 7|64@0+ (1,0) [0|1.84467440737096E+019] ""  GW,CR_R

BO_ 1946 IDC_L2_Phy_Req: 8 Tester
 SG_ IDC_L2_Phy_Req : 7|64@0+ (1,0) [0|1.84467440737096E+019] ""  GW,IDC_L2

BO_ 1751 IDC_L3_Phy_Req: 8 Tester
 SG_ IDC_L3_Phy_Req : 7|64@0+ (1,0) [0|1.84467440737096E+019] ""  GW,IDC_L3

BO_ 1762 RRR_Phy_Req: 8 Tester
 SG_ RRR_Phy_Req : 7|64@0+ (1,0) [0|1.84467440737096E+019] ""  GW,IDC_L3,RRR

BO_ 1763 SRR_L_Phy_Req: 8 Tester
 SG_ SRR_L_Phy_Req : 7|64@0+ (1,0) [0|1.84467440737096E+019] ""  GW,IDC_L3,SRR_L

BO_ 1764 SRR_R_Phy_Req: 8 Tester
 SG_ SRR_R_Phy_Req : 7|64@0+ (1,0) [0|1.84467440737096E+019] ""  GW,IDC_L3,SRR_R

BO_ 1953 GW_Phy_Resp: 8 GW
 SG_ GW_Phy_Resp : 7|64@0+ (1,0) [0|1.84467440737096E+019] ""  Tester

BO_ 1966 RSDS_L_Phy_Resp: 8 RSDS_L
 SG_ RSDS_L_Phy_Resp : 7|64@0+ (1,0) [0|1.84467440737096E+019] ""  GW,Tester

BO_ 1967 RSDS_R_Phy_Resp: 8 RSDS_R
 SG_ RSDS_R_Phy_Resp : 7|64@0+ (1,0) [0|1.84467440737096E+019] ""  GW,Tester

BO_ 1970 FR_Phy_Resp: 8 FR
 SG_ FR_Phy_Resp : 7|64@0+ (1,0) [0|1.84467440737096E+019] ""  GW,Tester

BO_ 1978 IFC_Phy_Resp: 8 IFC
 SG_ IFC_Phy_Resp : 7|64@0+ (1,0) [0|1.84467440737096E+019] ""  GW,Tester

BO_ 1963 HC_Phy_Resp: 8 HC
 SG_ HC_Phy_Resp : 7|64@0+ (1,0) [0|1.84467440737096E+019] ""  GW,Tester

BO_ 1974 HAP_Phy_Resp: 8 HAP
 SG_ HAP_Phy_Resp : 7|64@0+ (1,0) [0|1.84467440737096E+019] ""  GW,Tester

BO_ 1973 PAS_Phy_Resp: 8 PAS
 SG_ PAS_Phy_Resp : 7|64@0+ (1,0) [0|1.84467440737096E+019] ""  GW,Tester

BO_ 1614 CR_L_Phy_Resp: 8 CR_L
 SG_ CR_L_Phy_Resp : 7|64@0+ (1,0) [0|1.84467440737096E+019] ""  GW,Tester

BO_ 1615 CR_R_Phy_Resp: 8 CR_R
 SG_ CR_R_Phy_Resp : 7|64@0+ (1,0) [0|1.84467440737096E+019] ""  GW,Tester

BO_ 2010 IDC_L2_Phy_Resp: 8 IDC_L2
 SG_ IDC_L2_Phy_Resp : 7|64@0+ (1,0) [0|1.84467440737096E+019] ""  GW,Tester

BO_ 1759 IDC_L3_Phy_Resp: 8 IDC_L3
 SG_ IDC_L3_Phy_Resp : 7|64@0+ (1,0) [0|1.84467440737096E+019] ""  GW,Tester

BO_ 1770 RRR_Phy_Resp: 8 RRR
 SG_ RRR_Phy_Resp : 7|64@0+ (1,0) [0|1.84467440737096E+019] ""  IDC_L3,GW,Tester

BO_ 1771 SRR_L_Phy_Resp: 8 SRR_L
 SG_ SRR_L_Phy_Resp : 7|64@0+ (1,0) [0|1.84467440737096E+019] ""  IDC_L3,GW,Tester

BO_ 1772 SRR_R_Phy_Resp: 8 SRR_R
 SG_ SRR_R_Phy_Resp : 7|64@0+ (1,0) [0|1.84467440737096E+019] ""  IDC_L3,GW,Tester

BA_DEF_ BO_  "DiagState" ENUM  "No","Yes";
BA_DEF_ BO_  "NmMessage" ENUM  "no","yes";
BA_DEF_ BO_  "GenMsgILSupport" ENUM  "No","Yes";
BA_DEF_ BO_  "GenMsgCycleTime" INT 0 65535;
BA_DEF_ BO_  "GenMsgMinAcceptLength" INT 0 8;
BA_DEF_ BO_  "GenMsgSendType" ENUM  "Cyclic","CyclicAndSpontanX","Event";
BA_DEF_ BO_  "CANFD_BRS" ENUM  "0","1";
BA_DEF_ BO_  "VFrameFormat" ENUM  "StandardCAN","ExtendedCAN","reserved","reserved","reserved","reserved","reserved","reserved","reserved","reserved","reserved","reserved","reserved","reserved","StandardCAN_FD","ExtendedCAN_FD";
BA_DEF_ SG_  "GenSigEnvVarType" ENUM  "undef","int","float";
BA_DEF_ SG_  "GenSigSendType" ENUM  "Cyclic","OnWrite","OnWriteWithRepetition","OnChange","OnChangeWithRepetition","IfActive","IfActiveWithRepetition","NoSigSendType","NotUsed","NotUsed","NotUsed","NotUsed","NotUsed";
BA_DEF_ SG_  "GenSigStartValue" FLOAT 0 1215752192;
BA_DEF_ SG_  "SystemSignalLongSymbol" STRING ;
BA_DEF_DEF_  "DiagState" "No";
BA_DEF_DEF_  "NmMessage" "no";
BA_DEF_DEF_  "GenMsgILSupport" "Yes";
BA_DEF_DEF_  "GenMsgCycleTime" 10;
BA_DEF_DEF_  "GenMsgMinAcceptLength" 8;
BA_DEF_DEF_  "GenMsgSendType" "Cyclic";
BA_DEF_DEF_  "CANFD_BRS" "1";
BA_DEF_DEF_  "VFrameFormat" "StandardCAN";
BA_DEF_DEF_  "GenSigEnvVarType" "undef";
BA_DEF_DEF_  "GenSigSendType" "Cyclic";
BA_DEF_DEF_  "GenSigStartValue" 0;
BA_DEF_DEF_  "SystemSignalLongSymbol" "";
BA_ "GenMsgCycleTime" BO_ 642 100;
BA_ "VFrameFormat" BO_ 642 14;
BA_ "GenMsgCycleTime" BO_ 643 100;
BA_ "VFrameFormat" BO_ 643 14;
BA_ "GenMsgCycleTime" BO_ 647 100;
BA_ "VFrameFormat" BO_ 647 14;
BA_ "GenMsgCycleTime" BO_ 648 100;
BA_ "VFrameFormat" BO_ 648 14;
BA_ "GenMsgCycleTime" BO_ 649 100;
BA_ "VFrameFormat" BO_ 649 14;
BA_ "GenMsgCycleTime" BO_ 657 100;
BA_ "VFrameFormat" BO_ 657 14;
BA_ "GenMsgCycleTime" BO_ 661 50;
BA_ "VFrameFormat" BO_ 661 14;
BA_ "GenMsgCycleTime" BO_ 664 100;
BA_ "VFrameFormat" BO_ 664 14;
BA_ "GenMsgCycleTime" BO_ 671 100;
BA_ "VFrameFormat" BO_ 671 14;
BA_ "GenMsgCycleTime" BO_ 680 100;
BA_ "VFrameFormat" BO_ 680 14;
BA_ "GenMsgCycleTime" BO_ 683 100;
BA_ "VFrameFormat" BO_ 683 14;
BA_ "GenMsgCycleTime" BO_ 692 100;
BA_ "VFrameFormat" BO_ 692 14;
BA_ "GenMsgCycleTime" BO_ 696 100;
BA_ "VFrameFormat" BO_ 696 14;
BA_ "GenMsgCycleTime" BO_ 707 100;
BA_ "VFrameFormat" BO_ 707 14;
BA_ "GenMsgCycleTime" BO_ 714 100;
BA_ "VFrameFormat" BO_ 714 14;
BA_ "GenMsgCycleTime" BO_ 717 100;
BA_ "VFrameFormat" BO_ 717 14;
BA_ "GenMsgCycleTime" BO_ 719 100;
BA_ "VFrameFormat" BO_ 719 14;
BA_ "GenMsgCycleTime" BO_ 728 0;
BA_ "GenMsgSendType" BO_ 728 2;
BA_ "VFrameFormat" BO_ 728 14;
BA_ "GenMsgCycleTime" BO_ 730 0;
BA_ "GenMsgSendType" BO_ 730 2;
BA_ "VFrameFormat" BO_ 730 14;
BA_ "GenMsgCycleTime" BO_ 733 0;
BA_ "GenMsgSendType" BO_ 733 2;
BA_ "VFrameFormat" BO_ 733 14;
BA_ "GenMsgCycleTime" BO_ 734 0;
BA_ "GenMsgSendType" BO_ 734 2;
BA_ "VFrameFormat" BO_ 734 14;
BA_ "GenMsgCycleTime" BO_ 743 50;
BA_ "VFrameFormat" BO_ 743 14;
BA_ "GenMsgCycleTime" BO_ 745 100;
BA_ "VFrameFormat" BO_ 745 14;
BA_ "GenMsgCycleTime" BO_ 748 100;
BA_ "VFrameFormat" BO_ 748 14;
BA_ "GenMsgCycleTime" BO_ 762 100;
BA_ "VFrameFormat" BO_ 762 14;
BA_ "GenMsgCycleTime" BO_ 769 100;
BA_ "VFrameFormat" BO_ 769 14;
BA_ "GenMsgCycleTime" BO_ 778 200;
BA_ "VFrameFormat" BO_ 778 14;
BA_ "GenMsgCycleTime" BO_ 793 50;
BA_ "VFrameFormat" BO_ 793 14;
BA_ "GenMsgCycleTime" BO_ 833 500;
BA_ "VFrameFormat" BO_ 833 14;
BA_ "GenMsgCycleTime" BO_ 837 50;
BA_ "VFrameFormat" BO_ 837 14;
BA_ "GenMsgCycleTime" BO_ 846 500;
BA_ "VFrameFormat" BO_ 846 14;
BA_ "GenMsgCycleTime" BO_ 849 500;
BA_ "GenMsgSendType" BO_ 849 1;
BA_ "VFrameFormat" BO_ 849 14;
BA_ "GenMsgCycleTime" BO_ 880 1000;
BA_ "VFrameFormat" BO_ 880 14;
BA_ "GenMsgCycleTime" BO_ 901 100;
BA_ "VFrameFormat" BO_ 901 14;
BA_ "GenMsgCycleTime" BO_ 1001 1000;
BA_ "VFrameFormat" BO_ 1001 14;
BA_ "GenMsgCycleTime" BO_ 1045 5000;
BA_ "VFrameFormat" BO_ 1045 14;
BA_ "NmMessage" BO_ 1305 1;
BA_ "GenMsgCycleTime" BO_ 1305 0;
BA_ "GenMsgSendType" BO_ 1305 2;
BA_ "NmMessage" BO_ 1308 1;
BA_ "GenMsgCycleTime" BO_ 1308 0;
BA_ "GenMsgSendType" BO_ 1308 2;
BA_ "NmMessage" BO_ 1309 1;
BA_ "GenMsgCycleTime" BO_ 1309 0;
BA_ "GenMsgSendType" BO_ 1309 2;
BA_ "NmMessage" BO_ 1310 1;
BA_ "GenMsgCycleTime" BO_ 1310 0;
BA_ "GenMsgSendType" BO_ 1310 2;
BA_ "NmMessage" BO_ 1311 1;
BA_ "GenMsgCycleTime" BO_ 1311 0;
BA_ "GenMsgSendType" BO_ 1311 2;
BA_ "NmMessage" BO_ 1281 1;
BA_ "GenMsgCycleTime" BO_ 1281 0;
BA_ "GenMsgSendType" BO_ 1281 2;
BA_ "DiagState" BO_ 1888 1;
BA_ "GenMsgCycleTime" BO_ 1888 0;
BA_ "GenMsgSendType" BO_ 1888 2;
BA_ "GenMsgCycleTime" BO_ 1889 0;
BA_ "GenMsgSendType" BO_ 1889 2;
BA_ "GenMsgCycleTime" BO_ 1902 0;
BA_ "GenMsgSendType" BO_ 1902 2;
BA_ "GenMsgCycleTime" BO_ 1903 0;
BA_ "GenMsgSendType" BO_ 1903 2;
BA_ "GenMsgCycleTime" BO_ 1906 0;
BA_ "GenMsgSendType" BO_ 1906 2;
BA_ "GenMsgCycleTime" BO_ 1914 0;
BA_ "GenMsgSendType" BO_ 1914 2;
BA_ "GenMsgCycleTime" BO_ 1899 0;
BA_ "GenMsgSendType" BO_ 1899 2;
BA_ "GenMsgCycleTime" BO_ 1910 0;
BA_ "GenMsgSendType" BO_ 1910 2;
BA_ "GenMsgCycleTime" BO_ 1909 0;
BA_ "GenMsgSendType" BO_ 1909 2;
BA_ "GenMsgCycleTime" BO_ 1550 0;
BA_ "GenMsgSendType" BO_ 1550 2;
BA_ "GenMsgCycleTime" BO_ 1551 0;
BA_ "GenMsgSendType" BO_ 1551 2;
BA_ "GenMsgCycleTime" BO_ 1946 0;
BA_ "GenMsgSendType" BO_ 1946 2;
BA_ "GenMsgCycleTime" BO_ 1751 0;
BA_ "GenMsgSendType" BO_ 1751 2;
BA_ "GenMsgCycleTime" BO_ 1762 0;
BA_ "GenMsgSendType" BO_ 1762 2;
BA_ "GenMsgCycleTime" BO_ 1763 0;
BA_ "GenMsgSendType" BO_ 1763 2;
BA_ "GenMsgCycleTime" BO_ 1764 0;
BA_ "GenMsgSendType" BO_ 1764 2;
BA_ "GenMsgCycleTime" BO_ 1953 0;
BA_ "GenMsgSendType" BO_ 1953 2;
BA_ "GenMsgCycleTime" BO_ 1966 0;
BA_ "GenMsgSendType" BO_ 1966 2;
BA_ "GenMsgCycleTime" BO_ 1967 0;
BA_ "GenMsgSendType" BO_ 1967 2;
BA_ "GenMsgCycleTime" BO_ 1970 0;
BA_ "GenMsgSendType" BO_ 1970 2;
BA_ "GenMsgCycleTime" BO_ 1978 0;
BA_ "GenMsgSendType" BO_ 1978 2;
BA_ "GenMsgCycleTime" BO_ 1963 0;
BA_ "GenMsgSendType" BO_ 1963 2;
BA_ "GenMsgCycleTime" BO_ 1974 0;
BA_ "GenMsgSendType" BO_ 1974 2;
BA_ "GenMsgCycleTime" BO_ 1973 0;
BA_ "GenMsgSendType" BO_ 1973 2;
BA_ "GenMsgCycleTime" BO_ 1614 0;
BA_ "GenMsgSendType" BO_ 1614 2;
BA_ "GenMsgCycleTime" BO_ 1615 0;
BA_ "GenMsgSendType" BO_ 1615 2;
BA_ "GenMsgCycleTime" BO_ 2010 0;
BA_ "GenMsgSendType" BO_ 2010 2;
BA_ "GenMsgCycleTime" BO_ 1759 0;
BA_ "GenMsgSendType" BO_ 1759 2;
BA_ "GenMsgCycleTime" BO_ 1770 0;
BA_ "GenMsgSendType" BO_ 1770 2;
BA_ "GenMsgCycleTime" BO_ 1771 0;
BA_ "GenMsgSendType" BO_ 1771 2;
BA_ "GenMsgCycleTime" BO_ 1772 0;
BA_ "GenMsgSendType" BO_ 1772 2;
BA_ "GenSigStartValue" SG_ 642 OD_Obj1_ID 15;
BA_ "GenSigStartValue" SG_ 642 OD_Obj1_type 7;
BA_ "GenSigStartValue" SG_ 642 OD_Obj1_Confidence 15;
BA_ "GenSigStartValue" SG_ 642 OD_Obj1_Ground_Pos_X 4095;
BA_ "GenSigStartValue" SG_ 642 OD_Obj1_Ground_Pos_Y 4095;
BA_ "GenSigStartValue" SG_ 642 OD_Obj2_ID 15;
BA_ "GenSigStartValue" SG_ 642 OD_Obj2_type 7;
BA_ "GenSigStartValue" SG_ 642 OD_Obj2_Confidence 15;
BA_ "GenSigStartValue" SG_ 642 OD_Obj2_Ground_Pos_X 4095;
BA_ "GenSigStartValue" SG_ 642 OD_Obj2_Ground_Pos_Y 4095;
BA_ "GenSigStartValue" SG_ 642 OD_Obj3_ID 15;
BA_ "GenSigStartValue" SG_ 642 OD_Obj3_type 7;
BA_ "GenSigStartValue" SG_ 642 OD_Obj3_Confidence 15;
BA_ "GenSigStartValue" SG_ 642 OD_Obj3_Ground_Pos_X 4095;
BA_ "GenSigStartValue" SG_ 642 OD_Obj3_Ground_Pos_Y 4095;
BA_ "GenSigStartValue" SG_ 642 OD_Obj4_ID 15;
BA_ "GenSigStartValue" SG_ 642 OD_Obj4_type 7;
BA_ "GenSigStartValue" SG_ 642 OD_Obj4_Confidence 15;
BA_ "GenSigStartValue" SG_ 642 OD_Obj4_Ground_Pos_X 4095;
BA_ "GenSigStartValue" SG_ 642 OD_Obj4_Ground_Pos_Y 4095;
BA_ "GenSigStartValue" SG_ 642 OD_Obj5_ID 15;
BA_ "GenSigStartValue" SG_ 642 OD_Obj5_type 7;
BA_ "GenSigStartValue" SG_ 642 OD_Obj5_Confidence 15;
BA_ "GenSigStartValue" SG_ 642 OD_Obj5_Ground_Pos_X 4095;
BA_ "GenSigStartValue" SG_ 642 OD_Obj5_Ground_Pos_Y 4095;
BA_ "GenSigStartValue" SG_ 642 OD_Obj6_ID 15;
BA_ "GenSigStartValue" SG_ 642 OD_Obj6_type 7;
BA_ "GenSigStartValue" SG_ 642 OD_Obj6_Confidence 15;
BA_ "GenSigStartValue" SG_ 642 OD_Obj6_Ground_Pos_X 4095;
BA_ "GenSigStartValue" SG_ 642 OD_Obj6_Ground_Pos_Y 4095;
BA_ "GenSigStartValue" SG_ 642 OD_Obj7_ID 15;
BA_ "GenSigStartValue" SG_ 642 OD_Obj7_type 7;
BA_ "GenSigStartValue" SG_ 642 OD_Obj7_Confidence 15;
BA_ "GenSigStartValue" SG_ 642 OD_Obj7_Ground_Pos_X 4095;
BA_ "GenSigStartValue" SG_ 642 OD_Obj7_Ground_Pos_Y 4095;
BA_ "GenSigStartValue" SG_ 643 HWP_CrsSpdSetVal 255;
BA_ "GenSigStartValue" SG_ 643 HWP_VehSpdUnit 1;
BA_ "GenSigStartValue" SG_ 649 HAP_RtCam_WorkSts 1;
BA_ "GenSigStartValue" SG_ 649 USS_FLSide1_Status 1;
BA_ "GenSigStartValue" SG_ 649 USS_RLSide2_Status 1;
BA_ "GenSigStartValue" SG_ 649 USS_FRSide1_Status 1;
BA_ "GenSigStartValue" SG_ 649 USS_RRSide2_Status 1;
BA_ "GenSigStartValue" SG_ 649 USS_FrontSys_Status 1;
BA_ "GenSigStartValue" SG_ 657 Freespace_1_distance 63;
BA_ "GenSigStartValue" SG_ 657 Freespace_2_distance 63;
BA_ "GenSigStartValue" SG_ 657 Freespace_3_distance 63;
BA_ "GenSigStartValue" SG_ 657 Freespace_4_distance 63;
BA_ "GenSigStartValue" SG_ 657 Freespace_5_distance 63;
BA_ "GenSigStartValue" SG_ 657 Freespace_6_distance 63;
BA_ "GenSigStartValue" SG_ 657 Freespace_7_distance 63;
BA_ "GenSigStartValue" SG_ 657 Freespace_8_distance 63;
BA_ "GenSigStartValue" SG_ 657 Freespace_9_distance 63;
BA_ "GenSigStartValue" SG_ 657 Freespace_10_distance 63;
BA_ "GenSigStartValue" SG_ 657 Freespace_11_distance 63;
BA_ "GenSigStartValue" SG_ 657 Freespace_12_distance 63;
BA_ "GenSigStartValue" SG_ 657 Freespace_13_distance 63;
BA_ "GenSigStartValue" SG_ 657 Freespace_14_distance 63;
BA_ "GenSigStartValue" SG_ 657 Freespace_15_distance 63;
BA_ "GenSigStartValue" SG_ 657 Freespace_16_distance 63;
BA_ "GenSigStartValue" SG_ 657 Freespace_17_distance 63;
BA_ "GenSigStartValue" SG_ 657 Freespace_18_distance 63;
BA_ "GenSigStartValue" SG_ 657 Freespace_19_distance 63;
BA_ "GenSigStartValue" SG_ 657 Freespace_20_distance 63;
BA_ "GenSigStartValue" SG_ 657 Freespace_21_distance 63;
BA_ "GenSigStartValue" SG_ 657 Freespace_22_distance 63;
BA_ "GenSigStartValue" SG_ 657 Freespace_23_distance 63;
BA_ "GenSigStartValue" SG_ 657 Freespace_24_distance 63;
BA_ "GenSigStartValue" SG_ 657 Freespace_25_distance 63;
BA_ "GenSigStartValue" SG_ 657 Freespace_26_distance 63;
BA_ "GenSigStartValue" SG_ 657 Freespace_27_distance 63;
BA_ "GenSigStartValue" SG_ 657 Freespace_28_distance 63;
BA_ "GenSigStartValue" SG_ 657 Freespace_29_distance 63;
BA_ "GenSigStartValue" SG_ 657 Freespace_30_distance 63;
BA_ "GenSigStartValue" SG_ 657 Freespace_31_distance 63;
BA_ "GenSigStartValue" SG_ 657 Freespace_32_distance 63;
BA_ "GenSigStartValue" SG_ 657 Freespace_33_distance 63;
BA_ "GenSigStartValue" SG_ 657 Freespace_34_distance 63;
BA_ "GenSigStartValue" SG_ 657 Freespace_35_distance 63;
BA_ "GenSigStartValue" SG_ 657 Freespace_36_distance 63;
BA_ "GenSigStartValue" SG_ 657 Freespace_37_distance 63;
BA_ "GenSigStartValue" SG_ 657 Freespace_38_distance 63;
BA_ "GenSigStartValue" SG_ 657 Freespace_39_distance 63;
BA_ "GenSigStartValue" SG_ 657 Freespace_40_distance 63;
BA_ "GenSigStartValue" SG_ 657 Freespace_41_distance 63;
BA_ "GenSigStartValue" SG_ 657 Freespace_42_distance 63;
BA_ "GenSigStartValue" SG_ 657 Freespace_43_distance 63;
BA_ "GenSigStartValue" SG_ 657 Freespace_44_distance 63;
BA_ "GenSigStartValue" SG_ 657 Freespace_45_distance 63;
BA_ "GenSigStartValue" SG_ 657 Freespace_46_distance 63;
BA_ "GenSigStartValue" SG_ 657 Freespace_47_distance 63;
BA_ "GenSigStartValue" SG_ 657 Freespace_48_distance 63;
BA_ "GenSigStartValue" SG_ 664 RPAS_NearBrrdstn 255;
BA_ "GenSigStartValue" SG_ 664 FPAS_NearBrrdstn 127;
BA_ "GenSigStartValue" SG_ 664 LtCobfi 127;
BA_ "GenSigStartValue" SG_ 664 LtCurVtur 4095;
BA_ "GenSigStartValue" SG_ 664 LtSlope 16383;
BA_ "GenSigStartValue" SG_ 664 Ltlntcep 1023;
BA_ "GenSigStartValue" SG_ 664 RtCobfi 255;
BA_ "GenSigStartValue" SG_ 664 RtCurVtur 4095;
BA_ "GenSigStartValue" SG_ 664 RtSlope 16383;
BA_ "GenSigStartValue" SG_ 664 Rtlntcep 1023;
BA_ "GenSigStartValue" SG_ 683 Longctrl_ModSts_DVR 1;
BA_ "GenSigStartValue" SG_ 683 Longctrl_EngTrqReq_DVR 32767;
BA_ "GenSigStartValue" SG_ 683 ACC_ModDisp 1;
BA_ "GenSigStartValue" SG_ 683 ACC_SpdSetValue 255;
BA_ "GenSigStartValue" SG_ 683 TJA_ICA_ModDisp 1;
BA_ "GenSigStartValue" SG_ 692 AEBJAObjID 255;
BA_ "GenSigStartValue" SG_ 692 JAPedObjID 255;
BA_ "GenSigStartValue" SG_ 696 AEBObjID 255;
BA_ "GenSigStartValue" SG_ 696 CyclistObjID 255;
BA_ "GenSigStartValue" SG_ 696 PedObjID 255;
BA_ "GenSigStartValue" SG_ 696 ACCTgtObjID 255;
BA_ "GenSigStartValue" SG_ 696 RoadCrvt 511;
BA_ "GenSigStartValue" SG_ 696 SpdLimitDst 63;
BA_ "GenSigStartValue" SG_ 696 RoadCrvtFar 511;
BA_ "GenSigStartValue" SG_ 696 RampDst 63;
BA_ "GenSigStartValue" SG_ 696 SpdLimit 254;
BA_ "GenSigStartValue" SG_ 696 CurveDst 63;
BA_ "GenSigStartValue" SG_ 696 TunnelDst 63;
BA_ "GenSigStartValue" SG_ 696 BrdgDst 63;
BA_ "GenSigStartValue" SG_ 707 AEB_PedSwtReq 1;
BA_ "GenSigStartValue" SG_ 707 AEB_VehSwtReq 1;
BA_ "GenSigStartValue" SG_ 707 TSR_SnvtySet 15;
BA_ "GenSigStartValue" SG_ 707 NavSpdLimUnit_HUT 1;
BA_ "GenSigStartValue" SG_ 707 NavCtryType 156;
BA_ "GenSigStartValue" SG_ 707 HWA_SwtReq 1;
BA_ "GenSigStartValue" SG_ 707 ADAS_Posn_Offset 8191;
BA_ "GenSigStartValue" SG_ 707 ADAS_Posn_Spd 511;
BA_ "GenSigStartValue" SG_ 719 TSRSpdLimUnit 1;
BA_ "GenSigStartValue" SG_ 719 TSR_Snvty 15;
BA_ "GenSigSendType" SG_ 728 ADAS_Stub_MsgTyp 10;
BA_ "GenSigSendType" SG_ 728 ADAS_Stub_Offset 10;
BA_ "GenSigSendType" SG_ 728 ADAS_Stub_CycCnt 10;
BA_ "GenSigSendType" SG_ 728 ADAS_Stub_PathIdx 10;
BA_ "GenSigSendType" SG_ 728 ADAS_Stub_StubPathIdx 10;
BA_ "GenSigSendType" SG_ 728 ADAS_Stub_Retr 10;
BA_ "GenSigSendType" SG_ 728 ADAS_Stub_Update 10;
BA_ "GenSigSendType" SG_ 728 ADAS_Stub_RelProbb 10;
BA_ "GenSigSendType" SG_ 728 ADAS_Stub_FuncRoadClass 10;
BA_ "GenSigSendType" SG_ 728 ADAS_Stub_PartOfCalcRoute 10;
BA_ "GenSigSendType" SG_ 728 ADAS_Stub_CmplxInsct 10;
BA_ "GenSigSendType" SG_ 728 ADAS_Stub_FormOfWay 10;
BA_ "GenSigSendType" SG_ 728 ADAS_Stub_TurnAngl 10;
BA_ "GenSigSendType" SG_ 728 ADAS_Stub_LastStub 10;
BA_ "GenSigSendType" SG_ 728 ADAS_Stub_RtOfWay 10;
BA_ "GenSigSendType" SG_ 728 ADAS_Stub_NumOfLaneOppDir 10;
BA_ "GenSigSendType" SG_ 728 ADAS_Stub_NumOfLaneDrvDir 10;
BA_ "GenSigSendType" SG_ 730 ADAS_Seg_MsgTyp 10;
BA_ "GenSigSendType" SG_ 730 ADAS_Seg_Offset 10;
BA_ "GenSigSendType" SG_ 730 ADAS_Seg_CycCnt 10;
BA_ "GenSigSendType" SG_ 730 ADAS_Seg_PathIdx 10;
BA_ "GenSigSendType" SG_ 730 ADAS_Seg_Tunnel 10;
BA_ "GenSigSendType" SG_ 730 ADAS_Seg_Brdg 10;
BA_ "GenSigSendType" SG_ 730 ADAS_Seg_BuildUpArea 10;
BA_ "GenSigSendType" SG_ 730 ADAS_Seg_Retr 10;
BA_ "GenSigSendType" SG_ 730 ADAS_Seg_Update 10;
BA_ "GenSigSendType" SG_ 730 ADAS_Seg_RelProbb 10;
BA_ "GenSigSendType" SG_ 730 ADAS_Seg_FuncRoadClass 10;
BA_ "GenSigSendType" SG_ 730 ADAS_Seg_PartOfCalcRoute 10;
BA_ "GenSigSendType" SG_ 730 ADAS_Seg_CmplxInsct 10;
BA_ "GenSigSendType" SG_ 730 ADAS_Seg_FormOfWay 10;
BA_ "GenSigSendType" SG_ 730 ADAS_Seg_EffSpdLmt 10;
BA_ "GenSigSendType" SG_ 730 ADAS_Seg_EffSpdLmtTyp 10;
BA_ "GenSigSendType" SG_ 730 ADAS_Seg_DivideRoad 10;
BA_ "GenSigSendType" SG_ 730 ADAS_Seg_NumOfLaneOppDir 10;
BA_ "GenSigSendType" SG_ 730 ADAS_Seg_NumOfLaneDrvDir 10;
BA_ "GenSigSendType" SG_ 733 ADAS_ProfShort_MsgTyp 10;
BA_ "GenSigSendType" SG_ 733 ADAS_ProfShort_Offset 10;
BA_ "GenSigSendType" SG_ 733 ADAS_ProfShort_CycCnt 10;
BA_ "GenSigSendType" SG_ 733 ADAS_ProfShort_PathIdx 10;
BA_ "GenSigSendType" SG_ 733 ADAS_ProfShort_ProfTyp 10;
BA_ "GenSigSendType" SG_ 733 ADAS_ProfShort_CtrlPoint 10;
BA_ "GenSigSendType" SG_ 733 ADAS_ProfShort_Retr 10;
BA_ "GenSigSendType" SG_ 733 ADAS_ProfShort_Update 10;
BA_ "GenSigStartValue" SG_ 733 ADAS_ProfShort_AccurClass 3;
BA_ "GenSigSendType" SG_ 733 ADAS_ProfShort_AccurClass 10;
BA_ "GenSigSendType" SG_ 733 ADAS_ProfShort_Dist1 10;
BA_ "GenSigSendType" SG_ 733 ADAS_ProfShort_Value0 10;
BA_ "GenSigSendType" SG_ 733 ADAS_ProfShort_Value1 10;
BA_ "GenSigSendType" SG_ 734 ADAS_ProfLong_MsgTyp 10;
BA_ "GenSigSendType" SG_ 734 ADAS_ProfLong_Offset 10;
BA_ "GenSigSendType" SG_ 734 ADAS_ProfLong_CycCnt 10;
BA_ "GenSigSendType" SG_ 734 ADAS_ProfLong_PathIdx 10;
BA_ "GenSigSendType" SG_ 734 ADAS_ProfLong_ProfTyp 10;
BA_ "GenSigSendType" SG_ 734 ADAS_ProfLong_CtrlPoint 10;
BA_ "GenSigSendType" SG_ 734 ADAS_ProfLong_Retr 10;
BA_ "GenSigSendType" SG_ 734 ADAS_ProfLong_Update 10;
BA_ "GenSigSendType" SG_ 734 ADAS_ProfLong_Value 10;
BA_ "GenSigStartValue" SG_ 849 DrvSBR 1;
BA_ "GenSigStartValue" SG_ 849 PassSBR 1;
BA_ "GenSigStartValue" SG_ 849 PABSwtSts 1;
BA_ "GenSigStartValue" SG_ 849 SecRowLSBR 1;
BA_ "GenSigStartValue" SG_ 849 AirbFailLmpCmd 1;
BA_ "GenSigStartValue" SG_ 849 SecRowMidSBR 1;
BA_ "GenSigStartValue" SG_ 849 SecRowRSBR 1;
BA_ "GenSigStartValue" SG_ 849 PassSBR_Visual 1;
BA_ "GenSigStartValue" SG_ 849 DrvSBR_Visual 1;
BA_ "GenSigStartValue" SG_ 849 SecRowLSBR_Visual 1;
BA_ "GenSigStartValue" SG_ 849 SecRowMidSBR_Visual 1;
BA_ "GenSigStartValue" SG_ 849 SecRowRSBR_Visual 1;
BA_ "GenSigStartValue" SG_ 880 Time_Hour 31;
BA_ "GenSigStartValue" SG_ 880 Time_Minutes 63;
BA_ "GenSigStartValue" SG_ 880 Time_Second 63;
BA_ "GenSigStartValue" SG_ 880 Time_Year_Left 15;
BA_ "GenSigStartValue" SG_ 880 Time_Year_Right 15;
BA_ "GenSigStartValue" SG_ 901 ACAmbTemp 254;
BA_ "GenSigStartValue" SG_ 901 ACFrntBlwrSpd 15;
BA_ "GenSigStartValue" SG_ 1045 ADAS_Meta_DrvSide 1;
BA_ "GenSigSendType" SG_ 1305 Destination_HC_NM 10;
BA_ "GenSigSendType" SG_ 1305 OpCode_HC_NM 10;
BA_ "GenSigSendType" SG_ 1308 Destination_IDC_L3_NM 10;
BA_ "GenSigSendType" SG_ 1308 OpCode_IDC_L3_NM 10;
BA_ "GenSigSendType" SG_ 1309 Destination_RRR_NM 10;
BA_ "GenSigSendType" SG_ 1309 OpCode_RRR_NM 10;
BA_ "GenSigSendType" SG_ 1310 Destination_SRR_L_NM 10;
BA_ "GenSigSendType" SG_ 1310 OpCode_SRR_L_NM 10;
BA_ "GenSigSendType" SG_ 1311 Destination_SRR_R_NM 10;
BA_ "GenSigSendType" SG_ 1311 OpCode_SRR_R_NM 10;
BA_ "GenSigSendType" SG_ 1281 Destination_GW_NM 10;
BA_ "GenSigSendType" SG_ 1281 OpCode_GW_NM 10;
BA_ "GenSigSendType" SG_ 1888 DiagFuncReq 10;
BA_ "GenSigSendType" SG_ 1889 GW_Phy_Req 10;
BA_ "GenSigSendType" SG_ 1902 RSDS_L_Phy_Req 10;
BA_ "GenSigSendType" SG_ 1903 RSDS_R_Phy_Req 10;
BA_ "GenSigSendType" SG_ 1906 FR_Phy_Req 10;
BA_ "GenSigSendType" SG_ 1914 IFC_Phy_Req 10;
BA_ "GenSigSendType" SG_ 1899 HC_Phy_Req 10;
BA_ "GenSigSendType" SG_ 1910 HAP_Phy_Req 10;
BA_ "GenSigSendType" SG_ 1909 PAS_Phy_Req 10;
BA_ "GenSigSendType" SG_ 1550 CR_L_Phy_Req 10;
BA_ "GenSigSendType" SG_ 1551 CR_R_Phy_Req 10;
BA_ "GenSigSendType" SG_ 1946 IDC_L2_Phy_Req 10;
BA_ "GenSigSendType" SG_ 1751 IDC_L3_Phy_Req 10;
BA_ "GenSigSendType" SG_ 1762 RRR_Phy_Req 10;
BA_ "GenSigSendType" SG_ 1763 SRR_L_Phy_Req 10;
BA_ "GenSigSendType" SG_ 1764 SRR_R_Phy_Req 10;
BA_ "GenSigSendType" SG_ 1953 GW_Phy_Resp 10;
BA_ "GenSigSendType" SG_ 1966 RSDS_L_Phy_Resp 10;
BA_ "GenSigSendType" SG_ 1967 RSDS_R_Phy_Resp 10;
BA_ "GenSigSendType" SG_ 1970 FR_Phy_Resp 10;
BA_ "GenSigSendType" SG_ 1978 IFC_Phy_Resp 10;
BA_ "GenSigSendType" SG_ 1963 HC_Phy_Resp 10;
BA_ "GenSigSendType" SG_ 1974 HAP_Phy_Resp 10;
BA_ "GenSigSendType" SG_ 1973 PAS_Phy_Resp 10;
BA_ "GenSigSendType" SG_ 1614 CR_L_Phy_Resp 10;
BA_ "GenSigSendType" SG_ 1615 CR_R_Phy_Resp 10;
BA_ "GenSigSendType" SG_ 2010 IDC_L2_Phy_Resp 10;
BA_ "GenSigSendType" SG_ 1759 IDC_L3_Phy_Resp 10;
BA_ "GenSigSendType" SG_ 1770 RRR_Phy_Resp 10;
BA_ "GenSigSendType" SG_ 1771 SRR_L_Phy_Resp 10;
BA_ "GenSigSendType" SG_ 1772 SRR_R_Phy_Resp 10;
VAL_ 642 OD_Obj1_ID 0 " Valid values " ;
VAL_ 642 OD_Obj1_type 0 " No target " 1 " Pedestrian and biker " 2 " vehicle " 3 " Unknown type " 4 " Reserved " ;
VAL_ 642 OD_Obj1_Confidence 0 " Valid value " 10 " Invalid " ;
VAL_ 642 OD_Obj1_width 0 " Invalid " 1 " Valid values " ;
VAL_ 642 OD_Obj1_length 0 " Invalid " 1 " Valid values " ;
VAL_ 642 OD_Obj1_height 0 " Invalid " 1 " Valid values " ;
VAL_ 642 OD_Obj1_Ground_Pos_X 0 " Valid values " 4001 " Reserved " 4095 " Invalid values " ;
VAL_ 642 OD_Obj1_Ground_Pos_Y 0 " Valid values " 4001 " Reserved " 4095 " Invalid values " ;
VAL_ 642 OD_Obj2_ID 0 " Valid values " ;
VAL_ 642 OD_Obj2_type 0 " No target " 1 " Pedestrian and biker " 2 " vehicle " 3 " Unknown type " 4 " Reserved " ;
VAL_ 642 OD_Obj2_Confidence 0 " Valid value " 10 " Invalid " ;
VAL_ 642 OD_Obj2_width 0 " Invalid " 1 " Valid values " ;
VAL_ 642 OD_Obj2_length 0 " Invalid " 1 " Valid values " ;
VAL_ 642 OD_Obj2_height 0 " Invalid " 1 " Valid values " ;
VAL_ 642 OD_Obj2_Ground_Pos_X 0 " Valid values " 4001 " Reserved " 4095 " Invalid values " ;
VAL_ 642 OD_Obj2_Ground_Pos_Y 0 " Valid values " 4001 " Reserved " 4095 " Invalid values " ;
VAL_ 642 OD_Obj3_ID 0 " Valid values " ;
VAL_ 642 OD_Obj3_type 0 " No target " 1 " Pedestrian and biker " 2 " vehicle " 3 " Unknown type " 4 " Reserved " ;
VAL_ 642 OD_Obj3_Confidence 0 " Valid value " 10 " Invalid " ;
VAL_ 642 OD_Obj3_width 0 " Invalid " 1 " Valid values " ;
VAL_ 642 OD_Obj3_length 0 " Invalid " 1 " Valid values " ;
VAL_ 642 OD_Obj3_height 0 " Invalid " 1 " Valid values " ;
VAL_ 642 OD_Obj3_Ground_Pos_X 0 " Valid values " 4001 " Reserved " 4095 " Invalid values " ;
VAL_ 642 OD_Obj3_Ground_Pos_Y 0 " Valid values " 4001 " Reserved " 4095 " Invalid values " ;
VAL_ 642 OD_Obj4_ID 0 " Valid values " ;
VAL_ 642 OD_Obj4_type 0 " No target " 1 " Pedestrian and biker " 2 " vehicle " 3 " Unknown type " 4 " Reserved " ;
VAL_ 642 OD_Obj4_Confidence 0 " Valid value " 10 " Invalid " ;
VAL_ 642 OD_Obj4_width 0 " Invalid " 1 " Valid values " ;
VAL_ 642 OD_Obj4_length 0 " Invalid " 1 " Valid values " ;
VAL_ 642 OD_Obj4_height 0 " Invalid " 1 " Valid values " ;
VAL_ 642 OD_Obj4_Ground_Pos_X 0 " Valid values " 4001 " Reserved " 4095 " Invalid values " ;
VAL_ 642 OD_Obj4_Ground_Pos_Y 0 " Valid values " 4001 " Reserved " 4095 " Invalid values " ;
VAL_ 642 OD_Obj5_ID 0 " Valid values " ;
VAL_ 642 OD_Obj5_type 0 " No target " 1 " Pedestrian and biker " 2 " vehicle " 3 " Unknown type " 4 " Reserved " ;
VAL_ 642 OD_Obj5_Confidence 0 " Valid value " 10 " Invalid " ;
VAL_ 642 OD_Obj5_width 0 " Invalid " 1 " Valid values " ;
VAL_ 642 OD_Obj5_length 0 " Invalid " 1 " Valid values " ;
VAL_ 642 OD_Obj5_height 0 " Invalid " 1 " Valid values " ;
VAL_ 642 OD_Obj5_Ground_Pos_X 0 " Valid values " 4001 " Reserved " 4095 " Invalid values " ;
VAL_ 642 OD_Obj5_Ground_Pos_Y 0 " Valid values " 4001 " Reserved " 4095 " Invalid values " ;
VAL_ 642 OD_Obj6_ID 0 " Valid values " ;
VAL_ 642 OD_Obj6_type 0 " No target " 1 " Pedestrian and biker " 2 " vehicle " 3 " Unknown type " 4 " Reserved " ;
VAL_ 642 OD_Obj6_Confidence 0 " Valid value " 10 " Invalid " ;
VAL_ 642 OD_Obj6_width 0 " Invalid " 1 " Valid values " ;
VAL_ 642 OD_Obj6_length 0 " Invalid " 1 " Valid values " ;
VAL_ 642 OD_Obj6_height 0 " Invalid " 1 " Valid values " ;
VAL_ 642 OD_Obj6_Ground_Pos_X 0 " Valid values " 4001 " Reserved " 4095 " Invalid values " ;
VAL_ 642 OD_Obj6_Ground_Pos_Y 0 " Valid values " 4001 " Reserved " 4095 " Invalid values " ;
VAL_ 642 OD_Obj7_ID 0 " Valid values " ;
VAL_ 642 OD_Obj7_type 0 " No target " 1 " Pedestrian and biker " 2 " vehicle " 3 " Unknown type " 4 " Reserved " ;
VAL_ 642 OD_Obj7_Confidence 0 " Valid value " 10 " Invalid " ;
VAL_ 642 OD_Obj7_width 0 " Invalid " 1 " Valid values " ;
VAL_ 642 OD_Obj7_length 0 " Invalid " 1 " Valid values " ;
VAL_ 642 OD_Obj7_height 0 " Invalid " 1 " Valid values " ;
VAL_ 642 OD_Obj7_Ground_Pos_X 0 " Valid values " 4001 " Reserved " 4095 " Invalid values " ;
VAL_ 642 OD_Obj7_Ground_Pos_Y 0 " Valid values " 4001 " Reserved " 4095 " Invalid values " ;
VAL_ 643 Checksum_IDC_L3_2 0 " Valid value " ;
VAL_ 643 HWP_OperSts 0 " OFF State " 1 " Standby State " 2 " Ready State " 3 " Active State " 4 " Safe State " 5 " Failure State " 6 " Reserved " ;
VAL_ 643 EgoVehSpd 0 " Validvalue  " 2000 " reserved " ;
VAL_ 643 HWP_SpdMaxLim 0 " Validvalue  " 2000 " reserved " ;
VAL_ 643 HWP_CrsSpdSetVal 0 " Valid value " 255 " No display " ;
VAL_ 643 HWP_VehSpdUnit 0 " kph " 1 " mph " ;
VAL_ 643 HWP_OperStsDecision 0 " No display " 1 " LC " 2 " LK " 3 " AEB " 4 " ALC " 5 " Cruise " 6 " Follow " 7 " Traffic jam " 8 " Reserved no display " ;
VAL_ 643 HWP_TextWarn 0 " No display " 1 " Take over request " 2 " Attention please " 3 " Handsoff alert " 4 " HWP need to restart the engine " 5 " Tunnel ahead " 6 " Road split ahead " 7 " Road merge ahead " 8 " Overtime for lane change " 9 " HWP control cancelled " 10 " Reserved " ;
VAL_ 643 HWP_ChimeWarn 0 " No Warning " 1 " Warning Level 1 " 2 " Warning Level 2 " 3 " Warning Level 3 " ;
VAL_ 643 HWP_HAP_Cmd 0 " OFF " 1 " Active " 2 " Reserved " ;
VAL_ 643 RollingCounter_IDC_L3_2 0 " Valid value " 15 " Invalid value " ;
VAL_ 647 CheckSum_HC1 0 " Valid values " ;
VAL_ 647 HighBeamSts_HC 0 " Off " 1 " On " ;
VAL_ 647 ADBstatus 0 " Off " 1 " ON " 2 " error " 3 " Reserved " ;
VAL_ 647 LeftLowBeamFailSts 0 " No failure " 1 " Failure " ;
VAL_ 647 RightLowBeamFailSts 0 " No failure " 1 " Failure " ;
VAL_ 647 LeftHighBeamFailSts 0 " No failure " 1 " Failure " ;
VAL_ 647 RightHighBeamFailSts 0 " No failure " 1 " Failure " ;
VAL_ 647 ALS_FailSts 0 " No failure " 1 " Failure " ;
VAL_ 647 ALSDrvSide_FB 0 " Normal Mode " 1 " Temporary Mode " ;
VAL_ 647 HBStatusSegment0 0 " All LEDs OFF " 1 " All LEDs ON " 2 " Mixed " 3 " Reserved " ;
VAL_ 647 HBStatusSegment1 0 " All LEDs OFF " 1 " All LEDs ON " 2 " Mixed " 3 " Reserved " ;
VAL_ 647 HBStatusSegment2 0 " All LEDs OFF " 1 " All LEDs ON " 2 " Mixed " 3 " Reserved " ;
VAL_ 647 HBStatusSegment3 0 " All LEDs OFF " 1 " All LEDs ON " 2 " Mixed " 3 " Reserved " ;
VAL_ 647 HBStatusSegment4 0 " All LEDs OFF " 1 " All LEDs ON " 2 " Mixed " 3 " Reserved " ;
VAL_ 647 HBStatusSegment5 0 " All LEDs OFF " 1 " All LEDs ON " 2 " Mixed " 3 " Reserved " ;
VAL_ 647 HBStatusSegment6 0 " All LEDs OFF " 1 " All LEDs ON " 2 " Mixed " 3 " Reserved " ;
VAL_ 647 HBStatusSegment7 0 " All LEDs OFF " 1 " All LEDs ON " 2 " Mixed " 3 " Reserved " ;
VAL_ 647 RollingCounter_HC1 0 " Valid value " 15 " Invalid value " ;
VAL_ 648 HUT_OD_Obj0_ID 0 " Valid values " 10 " Invalid values " ;
VAL_ 648 HUT_OD_Obj0_type 0 " No target " 1 " Pedestrian or Biker " 2 " Vehicle " 3 " Ground Locker or Barrier " 4 " Unknown type " 5 " Invalid values " ;
VAL_ 648 HUT_OD_Obj0_Confidence 0 " 0-1 " 11 " Invalid values " ;
VAL_ 648 HUT_OD_Obj0_width 0 " Valid values " 127 " Invalid values " ;
VAL_ 648 HUT_OD_Obj0_Ground_Pos_X 0 " Valid values " 4001 " Reserved " 4095 " Invalid values " ;
VAL_ 648 HUT_OD_Obj0_Ground_Pos_Y 0 " Valid values " 4001 " Reserved " 4095 " Invalid values " ;
VAL_ 648 HTU_OD_Obj1_ID 0 " Valid values " 10 " Invalid values " ;
VAL_ 648 HUT_OD_Obj1_type 0 " No target " 1 " Pedestrian or Biker " 2 " Vehicle " 3 " Ground Locker or Barrier " 4 " Unknown type " 5 " Invalid values " ;
VAL_ 648 HUT_OD_Obj1_Confidence 0 " 0-1 " 11 " Invalid values " ;
VAL_ 648 HUT_OD_Obj1_width 0 " Valid values " 127 " Invalid values " ;
VAL_ 648 HUT_OD_Obj1_Ground_Pos_X 0 " Valid values " 4001 " Reserved " 4095 " Invalid values " ;
VAL_ 648 HUT_OD_Obj1_Ground_Pos_Y 0 " Valid values " 4001 " Reserved " 4095 " Invalid values " ;
VAL_ 648 HUT_OD_Obj2_ID 0 " Valid values " 10 " Invalid values " ;
VAL_ 648 HUT_OD_Obj2_type 0 " No target " 1 " Pedestrian or Biker " 2 " Vehicle " 3 " Ground Locker or Barrier " 4 " Unknown type " 5 " Invalid values " ;
VAL_ 648 HUT_OD_Obj2_Confidence 0 " 0-1 " 11 " Invalid values " ;
VAL_ 648 HUT_OD_Obj2_width 0 " Valid values " 127 " Invalid values " ;
VAL_ 648 HUT_OD_Obj2_Ground_Pos_X 0 " Valid values " 4001 " Reserved " 4095 " Invalid values " ;
VAL_ 648 HUT_OD_Obj2_Ground_Pos_Y 0 " Valid values " 4001 " Reserved " 4095 " Invalid values " ;
VAL_ 648 HUT_OD_Obj3_ID 0 " Valid values " 10 " Invalid values " ;
VAL_ 648 HUT_OD_Obj3_type 0 " No target " 1 " Pedestrian or Biker " 2 " Vehicle " 3 " Ground Locker or Barrier " 4 " Unknown type " 5 " Invalid values " ;
VAL_ 648 HUT_OD_Obj3_Confidence 0 " 0-1 " 11 " Invalid values " ;
VAL_ 648 HUT_OD_Obj3_width 0 " Valid values " 127 " Invalid values " ;
VAL_ 648 HUT_OD_Obj3_Ground_Pos_X 0 " Valid values " 4001 " Reserved " 4095 " Invalid values " ;
VAL_ 648 HUT_OD_Obj3_Ground_Pos_Y 0 " Valid values " 4001 " Reserved " 4095 " Invalid values " ;
VAL_ 648 HUT_OD_Obj4_ID 0 " Valid values " 10 " Invalid values " ;
VAL_ 648 HUT_OD_Obj4_type 0 " No target " 1 " Pedestrian or Biker " 2 " Vehicle " 3 " Ground Locker or Barrier " 4 " Unknown type " 5 " Invalid values " ;
VAL_ 648 HUT_OD_Obj4_Confidence 0 " 0-1 " 11 " Invalid values " ;
VAL_ 648 HUT_OD_Obj4_width 0 " Valid values " 127 " Invalid values " ;
VAL_ 648 HUT_OD_Obj4_Ground_Pos_X 0 " Valid values " 4001 " Reserved " 4095 " Invalid values " ;
VAL_ 648 HUT_OD_Obj4_Ground_Pos_Y 0 " Valid values " 4001 " Reserved " 4095 " Invalid values " ;
VAL_ 648 HUT_OD_Obj5_ID 0 " Valid values " 10 " Invalid values " ;
VAL_ 648 HUT_OD_Obj5_type 0 " No target " 1 " Pedestrian or Biker " 2 " Vehicle " 3 " Ground Locker or Barrier " 4 " Unknown type " 5 " Invalid values " ;
VAL_ 648 HUT_OD_Obj5_Confidence 0 " 0-1 " 11 " Invalid values " ;
VAL_ 648 HUT_OD_Obj5_width 0 " Valid values " 127 " Invalid values " ;
VAL_ 648 HUT_OD_Obj5_Ground_Pos_X 0 " Valid values " 4001 " Reserved " 4095 " Invalid values " ;
VAL_ 648 HUT_OD_Obj5_Ground_Pos_Y 0 " Valid values " 4001 " Reserved " 4095 " Invalid values " ;
VAL_ 648 HUT_OD_Obj6_ID 0 " Valid values " 10 " Invalid values " ;
VAL_ 648 HUT_OD_Obj6_type 0 " No target " 1 " Pedestrian or Biker " 2 " Vehicle " 3 " Ground Locker or Barrier " 4 " Unknown type " 5 " Invalid values " ;
VAL_ 648 HUT_OD_Obj6_Confidence 0 " 0-1 " 11 " Invalid values " ;
VAL_ 648 HUT_OD_Obj6_width 0 " Valid values " 127 " Invalid values " ;
VAL_ 648 HUT_OD_Obj6_Ground_Pos_X 0 " Valid values " 4001 " Reserved " 4095 " Invalid values " ;
VAL_ 648 HUT_OD_Obj6_Ground_Pos_Y 0 " Valid values " 4001 " Reserved " 4095 " Invalid values " ;
VAL_ 649 HAP_RtCam_WorkSts 0 " Disable " 1 " Enable " 2 " Active " 3 " Failed " ;
VAL_ 649 HAP_RtSide_Obj1_ID 0 " Valid values " 4 " Invalid values " ;
VAL_ 649 HAP_RtSide_Obj1_type 0 " No target " 1 " Pedestrian " 2 " Biker " 3 " Vehicle " 4 " Ground Locker " 5 " Barrier " 6 " Reserved " 7 " Unknown type " ;
VAL_ 649 HAP_RtSide_Obj1_Confidence 0 " Valid value " 10 " Invalid " ;
VAL_ 649 HAP_RtSide_Obj1_Ground_Pos_X 0 " Valid values " 4001 " Reserved " 4095 " Invalid values " ;
VAL_ 649 HAP_RtSide_Obj1_Ground_Pos_Y 0 " Valid values " 4001 " Reserved " 4095 " Invalid values " ;
VAL_ 649 HAP_RtSide_Obj2_ID 0 " Valid values " 4 " Invalid values " ;
VAL_ 649 HAP_RtSide_Obj2_type 0 " No target " 1 " Pedestrian " 2 " Biker " 3 " Vehicle " 4 " Ground Locker " 5 " Barrier " 6 " Reserved " 7 " Unknown type " ;
VAL_ 649 HAP_RtSide_Obj2_Confidence 0 " Valid value " 10 " Invalid " ;
VAL_ 649 HAP_RtSide_Obj2_Ground_Pos_X 0 " Valid values " 4001 " Reserved " 4095 " Invalid values " ;
VAL_ 649 HAP_RtSide_Obj2_Ground_Pos_Y 0 " Valid values " 4001 " Reserved " 4095 " Invalid values " ;
VAL_ 649 HAP_RtSide_Obj3_ID 0 " Valid values " 4 " Invalid values " ;
VAL_ 649 HAP_RtSide_Obj3_type 0 " No target " 1 " Pedestrian " 2 " Biker " 3 " Vehicle " 4 " Ground Locker " 5 " Barrier " 6 " Reserved " 7 " Unknown type " ;
VAL_ 649 HAP_RtSide_Obj3_Confidence 0 " Valid value " 10 " Invalid " ;
VAL_ 649 HAP_RtSide_Obj3_Ground_Pos_X 0 " Valid values " 4001 " Reserved " 4095 " Invalid values " ;
VAL_ 649 HAP_RtSide_Obj3_Ground_Pos_Y 0 " Valid values " 4001 " Reserved " 4095 " Invalid values " ;
VAL_ 649 HAP_RtSide_Obj4_ID 0 " Valid values " 4 " Invalid values " ;
VAL_ 649 HAP_RtSide_Obj4_type 0 " No target " 1 " Pedestrian " 2 " Biker " 3 " Vehicle " 4 " Ground Locker " 5 " Barrier " 6 " Reserved " 7 " Unknown type " ;
VAL_ 649 HAP_RtSide_Obj4_Confidence 0 " Valid value " 10 " Invalid " ;
VAL_ 649 HAP_RtSide_Obj4_Ground_Pos_X 0 " Valid values " 4001 " Reserved " 4095 " Invalid values " ;
VAL_ 649 HAP_RtSide_Obj4_Ground_Pos_Y 0 " Valid values " 4001 " Reserved " 4095 " Invalid values " ;
VAL_ 649 USS_FLSide1_Status 0 " Disable " 1 " Enable " 2 " Active " 3 " Failed " ;
VAL_ 649 USS_FLSide1_Dist 0 " Valid values " 127 " Invalid " ;
VAL_ 649 USS_RLSide2_Status 0 " Disable " 1 " Enable " 2 " Active " 3 " Failed " ;
VAL_ 649 USS_RLSide2_Dist 0 " Valid values " 127 " Invalid " ;
VAL_ 649 USS_FRSide1_Status 0 " Disable " 1 " Enable " 2 " Active " 3 " Failed " ;
VAL_ 649 USS_FRSide1_Dist 0 " Valid values " 127 " Invalid " ;
VAL_ 649 USS_RRSide2_Status 0 " Disable " 1 " Enable " 2 " Active " 3 " Failed " ;
VAL_ 649 USS_RRSide2_Dist 0 " Valid values " 127 " Invalid " ;
VAL_ 649 USS_FrontSys_Status 0 " Disable " 1 " Enable " 2 " Active " 3 " Failed " ;
VAL_ 649 USS_FLCNear_Obj_Confidence 0 " Valid value " 10 " Invalid " ;
VAL_ 649 USS_FLCNear_Obj_Pos_X 0 " Valid values " 63 " Invalid " ;
VAL_ 649 USS_FLCNear_Obj_Pos_Y 0 " Valid values " 63 " Invalid " ;
VAL_ 649 USS_FLMNear_Obj_Confidence 0 " Valid value " 10 " Invalid " ;
VAL_ 649 USS_FLMNear_Obj_Pos_X 0 " Valid values " 63 " Invalid " ;
VAL_ 649 USS_FLMNear_Obj_Pos_Y 0 " Valid values " 63 " Invalid " ;
VAL_ 649 USS_FRMNear_Obj_Confidence 0 " Valid value " 10 " Invalid " ;
VAL_ 649 USS_FRMNear_Obj_Pos_X 0 " Valid values " 63 " Invalid " ;
VAL_ 649 USS_FRMNear_Obj_Pos_Y 0 " Valid values " 63 " Invalid " ;
VAL_ 649 USS_FRCNear_Obj_Confidence 0 " Valid value " 10 " Invalid " ;
VAL_ 649 USS_FRCNear_Obj_Pos_X 0 " Valid values " 63 " Invalid " ;
VAL_ 649 USS_FRCNear_Obj_Pos_Y 0 " Valid values " 63 " Invalid " ;
VAL_ 657 Freespace_1_distance 0 " Valid values " 61 " Invalid values " ;
VAL_ 657 Freespace_2_distance 0 " Valid values " 61 " Invalid values " ;
VAL_ 657 Freespace_3_distance 0 " Valid values " 61 " Invalid values " ;
VAL_ 657 Freespace_4_distance 0 " Valid values " 61 " Invalid values " ;
VAL_ 657 Freespace_5_distance 0 " Valid values " 61 " Invalid values " ;
VAL_ 657 Freespace_6_distance 0 " Valid values " 61 " Invalid values " ;
VAL_ 657 Freespace_7_distance 0 " Valid values " 61 " Invalid values " ;
VAL_ 657 Freespace_8_distance 0 " Valid values " 61 " Invalid values " ;
VAL_ 657 Freespace_9_distance 0 " Valid values " 61 " Invalid values " ;
VAL_ 657 Freespace_10_distance 0 " Valid values " 61 " Invalid values " ;
VAL_ 657 Freespace_11_distance 0 " Valid values " 61 " Invalid values " ;
VAL_ 657 Freespace_12_distance 0 " Valid values " 61 " Invalid values " ;
VAL_ 657 Freespace_13_distance 0 " Valid values " 61 " Invalid values " ;
VAL_ 657 Freespace_14_distance 0 " Valid values " 61 " Invalid values " ;
VAL_ 657 Freespace_15_distance 0 " Valid values " 61 " Invalid values " ;
VAL_ 657 Freespace_16_distance 0 " Valid values " 61 " Invalid values " ;
VAL_ 657 Freespace_17_distance 0 " Valid values " 61 " Invalid values " ;
VAL_ 657 Freespace_18_distance 0 " Valid values " 61 " Invalid values " ;
VAL_ 657 Freespace_19_distance 0 " Valid values " 61 " Invalid values " ;
VAL_ 657 Freespace_20_distance 0 " Valid values " 61 " Invalid values " ;
VAL_ 657 Freespace_21_distance 0 " Valid values " 61 " Invalid values " ;
VAL_ 657 Freespace_22_distance 0 " Valid values " 61 " Invalid values " ;
VAL_ 657 Freespace_23_distance 0 " Valid values " 61 " Invalid values " ;
VAL_ 657 Freespace_24_distance 0 " Valid values " 61 " Invalid values " ;
VAL_ 657 Freespace_25_distance 0 " Valid values " 61 " Invalid values " ;
VAL_ 657 Freespace_26_distance 0 " Valid values " 61 " Invalid values " ;
VAL_ 657 Freespace_27_distance 0 " Valid values " 61 " Invalid values " ;
VAL_ 657 Freespace_28_distance 0 " Valid values " 61 " Invalid values " ;
VAL_ 657 Freespace_29_distance 0 " Valid values " 61 " Invalid values " ;
VAL_ 657 Freespace_30_distance 0 " Valid values " 61 " Invalid values " ;
VAL_ 657 Freespace_31_distance 0 " Valid values " 61 " Invalid values " ;
VAL_ 657 Freespace_32_distance 0 " Valid values " 61 " Invalid values " ;
VAL_ 657 Freespace_33_distance 0 " Valid values " 61 " Invalid values " ;
VAL_ 657 Freespace_34_distance 0 " Valid values " 61 " Invalid values " ;
VAL_ 657 Freespace_35_distance 0 " Valid values " 61 " Invalid values " ;
VAL_ 657 Freespace_36_distance 0 " Valid values " 61 " Invalid values " ;
VAL_ 657 Freespace_37_distance 0 " Valid values " 61 " Invalid values " ;
VAL_ 657 Freespace_38_distance 0 " Valid values " 61 " Invalid values " ;
VAL_ 657 Freespace_39_distance 0 " Valid values " 61 " Invalid values " ;
VAL_ 657 Freespace_40_distance 0 " Valid values " 61 " Invalid values " ;
VAL_ 657 Freespace_41_distance 0 " Valid values " 61 " Invalid values " ;
VAL_ 657 Freespace_42_distance 0 " Valid values " 61 " Invalid values " ;
VAL_ 657 Freespace_43_distance 0 " Valid values " 61 " Invalid values " ;
VAL_ 657 Freespace_44_distance 0 " Valid values " 61 " Invalid values " ;
VAL_ 657 Freespace_45_distance 0 " Valid values " 61 " Invalid values " ;
VAL_ 657 Freespace_46_distance 0 " Valid values " 61 " Invalid values " ;
VAL_ 657 Freespace_47_distance 0 " Valid values " 61 " Invalid values " ;
VAL_ 657 Freespace_48_distance 0 " Valid values " 61 " Invalid values " ;
VAL_ 661 SysPowerMod 0 " OFF " 1 " ACC (reserved) " 2 " ON " 3 " Crank " ;
VAL_ 661 SysPowerModVld 0 " Invalid " 1 " Valid " ;
VAL_ 664 RPAS_NearBrrdstn 0 " Valid value " 151 " Reserved " 255 " No Display " ;
VAL_ 664 APS_ObjRiSideAr1 0 " No object " 1 " Object in zone 1, 0~10cm " 2 " Object in zone 2, 11~20cm " 3 " Object in zone 3, 21~30cm " 4 " Object in zone 4, 31~40cm " 5 " Object in zone 5, 41~50cm " 6 " Object in zone 6, 51~60cm " 7 " Reserved " ;
VAL_ 664 APS_ObjRiSideAr2 0 " No object " 1 " Object in zone 1, 0~10cm " 2 " Object in zone 2, 11~20cm " 3 " Object in zone 3, 21~30cm " 4 " Object in zone 4, 31~40cm " 5 " Object in zone 5, 41~50cm " 6 " Object in zone 6, 51~60cm " 7 " Reserved " ;
VAL_ 664 APS_ObjRiSideAr3 0 " No object " 1 " Object in zone 1, 0~10cm " 2 " Object in zone 2, 11~20cm " 3 " Object in zone 3, 21~30cm " 4 " Object in zone 4, 31~40cm " 5 " Object in zone 5, 41~50cm " 6 " Object in zone 6, 51~60cm " 7 " Reserved " ;
VAL_ 664 APS_ObjRiSideAr4 0 " No object " 1 " Object in zone 1, 0~10cm " 2 " Object in zone 2, 11~20cm " 3 " Object in zone 3, 21~30cm " 4 " Object in zone 4, 31~40cm " 5 " Object in zone 5, 41~50cm " 6 " Object in zone 6, 51~60cm " 7 " Reserved " ;
VAL_ 664 APS_ObjRiSideAr5 0 " No object " 1 " Object in zone 1, 0~10cm " 2 " Object in zone 2, 11~20cm " 3 " Object in zone 3, 21~30cm " 4 " Object in zone 4, 31~40cm " 5 " Object in zone 5, 41~50cm " 6 " Object in zone 6, 51~60cm " 7 " Reserved " ;
VAL_ 664 APS_ObjLeSideAr1 0 " No object " 1 " Object in zone 1, 0~10cm " 2 " Object in zone 2, 11~20cm " 3 " Object in zone 3, 21~30cm " 4 " Object in zone 4, 31~40cm " 5 " Object in zone 5, 41~50cm " 6 " Object in zone 6, 51~60cm " 7 " Reserved " ;
VAL_ 664 APS_ObjLeSideAr2 0 " No object " 1 " Object in zone 1, 0~10cm " 2 " Object in zone 2, 11~20cm " 3 " Object in zone 3, 21~30cm " 4 " Object in zone 4, 31~40cm " 5 " Object in zone 5, 41~50cm " 6 " Object in zone 6, 51~60cm " 7 " Reserved " ;
VAL_ 664 APS_ObjLeSideAr3 0 " No object " 1 " Object in zone 1, 0~10cm " 2 " Object in zone 2, 11~20cm " 3 " Object in zone 3, 21~30cm " 4 " Object in zone 4, 31~40cm " 5 " Object in zone 5, 41~50cm " 6 " Object in zone 6, 51~60cm " 7 " Reserved " ;
VAL_ 664 APS_ObjLeSideAr4 0 " No object " 1 " Object in zone 1, 0~10cm " 2 " Object in zone 2, 11~20cm " 3 " Object in zone 3, 21~30cm " 4 " Object in zone 4, 31~40cm " 5 " Object in zone 5, 41~50cm " 6 " Object in zone 6, 51~60cm " 7 " Reserved " ;
VAL_ 664 APS_ObjLeSideAr5 0 " No object " 1 " Object in zone 1, 0~10cm " 2 " Object in zone 2, 11~20cm " 3 " Object in zone 3, 21~30cm " 4 " Object in zone 4, 31~40cm " 5 " Object in zone 5, 41~50cm " 6 " Object in zone 6, 51~60cm " 7 " Reserved " ;
VAL_ 664 APS_FRSideSnsrFailSts 0 " no failure " 1 " failure " ;
VAL_ 664 APS_FLSideSnsrFailSts 0 " no failure " 1 " failure " ;
VAL_ 664 APS_RRSideSnsrFailSts 0 " no failure " 1 " failure " ;
VAL_ 664 APS_RLSideSnsrFailSts 0 " no failure " 1 " failure " ;
VAL_ 664 SDW_SoundIndcn 0 " Tone 0 - No warning " 1 " Tone 1 - Long beep " 2 " Tone 2 - 1.5 Hz " 3 " Tone 3 - 3Hz " ;
VAL_ 664 SDWActiveSts 0 " Not active " 1 " Active " ;
VAL_ 664 RPAS_ObjRRCornrAr1 0 " No object " 1 " Object in zone 1, 0~10cm " 2 " Object in zone 2, 11~20cm " 3 " Object in zone 3, 21~30cm " 4 " Object in zone 4, 31~40cm " 5 " Object in zone 5, 41~50cm " 6 " Object in zone 6, 51~60cm " 7 " Reserved " ;
VAL_ 664 RPAS_ObjRRCornrAr2 0 " No object " 1 " Object in zone 1, 0~10cm " 2 " Object in zone 2, 11~20cm " 3 " Object in zone 3, 21~30cm " 4 " Object in zone 4, 31~40cm " 5 " Object in zone 5, 41~50cm " 6 " Object in zone 6, 51~60cm " 7 " Reserved " ;
VAL_ 664 RPAS_ObjRRMidlAr1 0 " No object " 1 " Object in zone 1, 0~10cm " 2 " Object in zone 2, 11~20cm " 3 " Object in zone 3, 21~30cm " 4 " Object in zone 4, 31~40cm " 5 " Object in zone 5, 41~50cm " 6 " Object in zone 6, 51~60cm " 7 " Object in zone 7, 61~70cm " 8 " Object in zone 8, 71~80cm " 9 " Object in zone 9, 81~90cm " 10 " Object in zone 10, 91~100cm " 11 " Object in zone 11, 101~110cm " 12 " Object in zone 12, 111~120cm " 13 " Object in zone 13, 121~130cm " 14 " Object in zone 14, 131~140cm " 15 " Object in zone 15, 141~150cm " ;
VAL_ 664 RPAS_ObjRRMidlAr2 0 " No object " 1 " Object in zone 1, 0~10cm " 2 " Object in zone 2, 11~20cm " 3 " Object in zone 3, 21~30cm " 4 " Object in zone 4, 31~40cm " 5 " Object in zone 5, 41~50cm " 6 " Object in zone 6, 51~60cm " 7 " Object in zone 7, 61~70cm " 8 " Object in zone 8, 71~80cm " 9 " Object in zone 9, 81~90cm " 10 " Object in zone 10, 91~100cm " 11 " Object in zone 11, 101~110cm " 12 " Object in zone 12, 111~120cm " 13 " Object in zone 13, 121~130cm " 14 " Object in zone 14, 131~140cm " 15 " Object in zone 15, 141~150cm " ;
VAL_ 664 RPAS_ObjRLMidlAr1 0 " No object " 1 " Object in zone 1, 0~10cm " 2 " Object in zone 2, 11~20cm " 3 " Object in zone 3, 21~30cm " 4 " Object in zone 4, 31~40cm " 5 " Object in zone 5, 41~50cm " 6 " Object in zone 6, 51~60cm " 7 " Object in zone 7, 61~70cm " 8 " Object in zone 8, 71~80cm " 9 " Object in zone 9, 81~90cm " 10 " Object in zone 10, 91~100cm " 11 " Object in zone 11, 101~110cm " 12 " Object in zone 12, 111~120cm " 13 " Object in zone 13, 121~130cm " 14 " Object in zone 14, 131~140cm " 15 " Object in zone 15, 141~150cm " ;
VAL_ 664 RPAS_ObjRLMidlAr2 0 " No object " 1 " Object in zone 1, 0~10cm " 2 " Object in zone 2, 11~20cm " 3 " Object in zone 3, 21~30cm " 4 " Object in zone 4, 31~40cm " 5 " Object in zone 5, 41~50cm " 6 " Object in zone 6, 51~60cm " 7 " Object in zone 7, 61~70cm " 8 " Object in zone 8, 71~80cm " 9 " Object in zone 9, 81~90cm " 10 " Object in zone 10, 91~100cm " 11 " Object in zone 11, 101~110cm " 12 " Object in zone 12, 111~120cm " 13 " Object in zone 13, 121~130cm " 14 " Object in zone 14, 131~140cm " 15 " Object in zone 15, 141~150cm " ;
VAL_ 664 RPAS_ObjRLCornrAr1 0 " No object " 1 " Object in zone 1, 0~10cm " 2 " Object in zone 2, 11~20cm " 3 " Object in zone 3, 21~30cm " 4 " Object in zone 4, 31~40cm " 5 " Object in zone 5, 41~50cm " 6 " Object in zone 6, 51~60cm " 7 " Reserved " ;
VAL_ 664 RPAS_ObjRLCornrAr2 0 " No object " 1 " Object in zone 1, 0~10cm " 2 " Object in zone 2, 11~20cm " 3 " Object in zone 3, 21~30cm " 4 " Object in zone 4, 31~40cm " 5 " Object in zone 5, 41~50cm " 6 " Object in zone 6, 51~60cm " 7 " Reserved " ;
VAL_ 664 RPAS_RLCornrSnsrFailSts 0 " no failure " 1 " failure " ;
VAL_ 664 RPAS_RLMiddlSnsrFailSts 0 " no failure " 1 " failure " ;
VAL_ 664 RPAS_RRMiddlSnsrFailSts 0 " no failure " 1 " failure " ;
VAL_ 664 RPAS_RRCornrSnsrFailSts 0 " no failure " 1 " failure " ;
VAL_ 664 RPAS_WorkSts 0 " Disable " 1 " Enable " 2 " Active " 3 " Failed " ;
VAL_ 664 RPAS_SoundIndcn 0 " Tone zero No warning " 1 " Tone one  Long beep " 2 " Tone two 1.5 Hz " 3 " Tone three  3Hz " ;
VAL_ 664 MEBWorkSts 0 " Off " 1 " Enable " 2 " Active " 3 " Failed " ;
VAL_ 664 MEB_EnableSts 0 " Disable " 1 " Enable " ;
VAL_ 664 FPAS_ObjFLCornrAr1 0 " No object " 1 " Object in zone 1, 0~10cm " 2 " Object in zone 2, 11~20cm " 3 " Object in zone 3, 21~30cm " 4 " Object in zone 4, 31~40cm " 5 " Object in zone 5, 41~50cm " 6 " Object in zone 6, 51~60cm " 7 " Reserved " ;
VAL_ 664 FPAS_ObjFLCornrAr2 0 " No object " 1 " Object in zone 1, 0~10cm " 2 " Object in zone 2, 11~20cm " 3 " Object in zone 3, 21~30cm " 4 " Object in zone 4, 31~40cm " 5 " Object in zone 5, 41~50cm " 6 " Object in zone 6, 51~60cm " 7 " Reserved " ;
VAL_ 664 FPAS_ObjFLMidlAr1 0 " No object " 1 " Object in zone 1, 0~10cm " 2 " Object in zone 2, 11~20cm " 3 " Object in zone 3, 21~30cm " 4 " Object in zone 4, 31~40cm " 5 " Object in zone 5, 41~50cm " 6 " Object in zone 6, 51~60cm " 7 " Object in zone 7, 61~70cm " 8 " Object in zone 8, 71~80cm " 9 " Object in zone 9, 81~90cm " 10 " Object in zone 10, 91~100cm " 11 " Reserved " ;
VAL_ 664 FPAS_ObjFLMidlAr2 0 " No object " 1 " Object in zone 1, 0~10cm " 2 " Object in zone 2, 11~20cm " 3 " Object in zone 3, 21~30cm " 4 " Object in zone 4, 31~40cm " 5 " Object in zone 5, 41~50cm " 6 " Object in zone 6, 51~60cm " 7 " Object in zone 7, 61~70cm " 8 " Object in zone 8, 71~80cm " 9 " Object in zone 9, 81~90cm " 10 " Object in zone 10, 91~100cm " 11 " Reserved " ;
VAL_ 664 FPAS_ObjFRMidlAr1 0 " No object " 1 " Object in zone 1, 0~10cm " 2 " Object in zone 2, 11~20cm " 3 " Object in zone 3, 21~30cm " 4 " Object in zone 4, 31~40cm " 5 " Object in zone 5, 41~50cm " 6 " Object in zone 6, 51~60cm " 7 " Object in zone 7, 61~70cm " 8 " Object in zone 8, 71~80cm " 9 " Object in zone 9, 81~90cm " 10 " Object in zone 10, 91~100cm " 11 " Reserved " ;
VAL_ 664 FPAS_ObjFRMidlAr2 0 " No object " 1 " Object in zone 1, 0~10cm " 2 " Object in zone 2, 11~20cm " 3 " Object in zone 3, 21~30cm " 4 " Object in zone 4, 31~40cm " 5 " Object in zone 5, 41~50cm " 6 " Object in zone 6, 51~60cm " 7 " Object in zone 7, 61~70cm " 8 " Object in zone 8, 71~80cm " 9 " Object in zone 9, 81~90cm " 10 " Object in zone 10, 91~100cm " 11 " Reserved " ;
VAL_ 664 FPAS_ObjFRCornrAr1 0 " No object " 1 " Object in zone 1, 0~10cm " 2 " Object in zone 2, 11~20cm " 3 " Object in zone 3, 21~30cm " 4 " Object in zone 4, 31~40cm " 5 " Object in zone 5, 41~50cm " 6 " Object in zone 6, 51~60cm " 7 " Reserved " ;
VAL_ 664 FPAS_ObjFRCornrAr2 0 " No object " 1 " Object in zone 1, 0~10cm " 2 " Object in zone 2, 11~20cm " 3 " Object in zone 3, 21~30cm " 4 " Object in zone 4, 31~40cm " 5 " Object in zone 5, 41~50cm " 6 " Object in zone 6, 51~60cm " 7 " Reserved " ;
VAL_ 664 FPAS_FLCornrSnsrFailSts 0 " no failure " 1 " failure " ;
VAL_ 664 FPAS_FLMiddlSnsrFailSts 0 " no failure " 1 " failure " ;
VAL_ 664 FPAS_FRMiddlSnsrFailSts 0 " no failure " 1 " failure " ;
VAL_ 664 FPAS_FRCornrSnsrFailSts 0 " no failure " 1 " failure " ;
VAL_ 664 FPAS_WorkSts 0 " Disable " 1 " Enable " 2 " Active " 3 " Failed " ;
VAL_ 664 FPAS_DispCmd 0 " OFF " 1 " ON " ;
VAL_ 664 FPAS_AutoModSts 0 " Not available " 1 " available " ;
VAL_ 664 FPAS_SoundIndcn 0 " Tone zero  No warning " 1 " Tone one  Long beep " 2 " Tone two 1.5 Hz " 3 " Tone three 3Hz " ;
VAL_ 664 FPAS_NearBrrdstn 0 " Valid value " 101 " Reserved " 127 " No Display " ;
VAL_ 664 APA_MenuDispCtrlCmd 0 " No_Disp_avm_menu " 1 " park_in_indicate_menu " 2 " park_in_select_slot_menu " 3 " park_in_mode_select_menu " 4 " park_in_process " 5 " remote_park_in_process " 6 " park_out_confirm_menu " 7 " park_out_process " 8 " park_in_indicate_menu_NoRPA " 9 " park_in_select_slot_menu_NoRPA " 10 " park_in_mode_select_menu_NoRPA " 11 " park_out _indicate_menu " 12 " Reversed " ;
VAL_ 664 APA_FuncSts 0 " APA Function standby " 1 " APA Function active " 2 " APA Function disable " 3 " Reserved " ;
VAL_ 664 P2P_FuncSts 0 " P2P Functionstandby " 1 " P2P Function active " 2 " P2P Function disable " 3 " Reserved " ;
VAL_ 664 RADS_FuncSts 0 " Reverse Asist Function standby " 1 " Reverse Asist Function active " 2 " Reverse Asist Function disable " 3 " Reserved " ;
VAL_ 664 FADS_FuncSts 0 " FADS Function standby " 1 " FADS Function active " 2 " FADS Function disable " 3 " Reserved " ;
VAL_ 664 HAP_TextIconDispCtrl 0 " No display " 1 " Display according to text info " 2 " Display parking mode  " 3 " Reserved " ;
VAL_ 664 OrvmCtrlCmd 0 " NO request " 1 " Request to Fold " 2 " Request to Unfold " 3 " Reserved " ;
VAL_ 664 RmtPrkgFinishReq 0 " No Request " 1 " Park in finish " 2 " Park out finish " 3 " Park error exit " ;
VAL_ 664 RmtPrkgSts 0 " No action " 1 " In processing " ;
VAL_ 664 APS_Coordinate_Angle 0 " Valid value " 360 " Invalid value " ;
VAL_ 664 APS_Coordinate_X 0 " Valid value " 501 " Invalid value " ;
VAL_ 664 APS_Coordinate_Y 0 " Valid value " 2001 " Invalid value " ;
VAL_ 664 HAPob_WorkSts 0 " Disable " 1 " Enable " 2 " Active " 3 " Failed " ;
VAL_ 664 LtCobfi 0 " Valid values " 101 " Invalid values " ;
VAL_ 664 LtCurVtur 0 " Valid values " 4001 " Reserved " 4095 " Invalid values " ;
VAL_ 664 LtSlope 0 " Valid values " 12001 " Reserved " 16383 " Invalid values " ;
VAL_ 664 Ltlntcep 0 " Valid values " 1001 " Reserved " 1023 " Invalid values " ;
VAL_ 664 RtCobfi 0 " Valid values " 101 " Invalid values " ;
VAL_ 664 RtCurVtur 0 " Valid values " 4001 " Reserved " 4095 " Invalid values " ;
VAL_ 664 RtSlope 0 " Valid values " 12001 " Reserved " 16383 " Invalid values " ;
VAL_ 664 Rtlntcep 0 " Valid values " 1001 " Reserved " 1023 " Invalid values " ;
VAL_ 671 Checksum_BCM8 0 " Valid values " ;
VAL_ 671 PASWorkCmd 0 " OFF " 1 " ON " ;
VAL_ 671 RViewMirrorSts 0 " Unfold " 1 " Fold " ;
VAL_ 671 WiprReq_F_PBOX 0 " Wiper Off " 1 " Wiper action once " 2 " Speed1 (Lo) " 3 " Speed2 (Hi) " 4 " Reserved " 7 " Invalid " ;
VAL_ 671 KL30BRelaySts 0 " Off " 1 " On " ;
VAL_ 671 Rollingcounter_BCM8 0 " Valid value " 15 " Invalid value " ;
VAL_ 680 TranPMode_Sts 0 " Normal Mode " 1 " Transport Mode " ;
VAL_ 680 Stat_PwrSv_Lvl 0 " Normal " 1 " Level 1 " 2 " Level 2 " 3 " Reserved " ;
VAL_ 683 ACC_LeTgt_02_Dy 0 " Valid value " 82 " Reserved " ;
VAL_ 683 ACC_LeTgt_02_Dx 0 " Valid value " 301 " Reserved " ;
VAL_ 683 ACC_LeTgt_02_Typ 0 " Unkown " 1 " Sedan " 2 " Truck " 3 " Motorcycle " 4 " Pedestrian " 5 " Bicycle " 6 " Reserved " 7 " Invalid " ;
VAL_ 683 ACC_LeTargrt_02_Detn 0 " Not dectected " 1 " Dectected " 2 " Reserved " 3 " Invalid " ;
VAL_ 683 ACC_RiTargrt_02_Detn 0 " Not dectected " 1 " Dectected " 2 " Reserved " 3 " Invalid " ;
VAL_ 683 ACC_RiTgt_02_Dy 0 " Valid value " 82 " Reserved " ;
VAL_ 683 ACC_RiTgt_02_Dx 0 " Valid value " 301 " Reserved " ;
VAL_ 683 ACC_RiTgt_02_Typ 0 " Unkown " 1 " Sedan " 2 " Truck " 3 " Motorcycle " 4 " Pedestrian " 5 " Bicycle " 6 " Reserved " 7 " Invalid " ;
VAL_ 683 ACC_LeTgtObjBarDisp 0 " No display " 1 " Distance_1 one bar " 2 " Distance_2 two bars " 3 " Distance_3 three bars " 4 " Distance_4 four bars " 5 " Resvered " ;
VAL_ 683 ACC_RiTgtObjBarDisp 0 " No display " 1 " Distance_1 one bar " 2 " Distance_2 two bars " 3 " Distance_3 three bars " 4 " Distance_4 four bars " 5 " Resvered " ;
VAL_ 683 Checksum_ACC3 0 " Valid value " ;
VAL_ 683 ISL_Resp 0 " OFF " 1 " ON " ;
VAL_ 683 ICA_HandsOffResp 0 " OFF " 1 " ON " ;
VAL_ 683 Longctrl_VehHldReq_DVR 0 " No Request " 1 " Request " ;
VAL_ 683 Longctrl_DrvOFF_Req_DVR 0 " No Request " 1 " Request " ;
VAL_ 683 Longctrl_ModSts_DVR 0 " OFF mode " 1 " Passive mode(Reject) " 2 " Passive mode(Stand-by) " 3 " Active-Control mode " 4 " Brake-only mode " 5 " Override " 6 " Standstill " 7 " Failure mode Longctrl " 8 " Reserved " 9 " Shut off " 10 " Reserved " ;
VAL_ 683 Longctrl_Decel_Req_DVR 0 " No Request " 1 " Request " ;
VAL_ 683 Longctrl_EngTrqReq_DVR 0 " Valid value " ;
VAL_ 683 Longctrl_EngTrqReqActive_DVR 0 " Not active " 1 " Active " ;
VAL_ 683 Longctrl_DecelToStopReq_DVR 0 " No Request " 1 " Request " ;
VAL_ 683 Longctrl_ParkShiftReq_DVR 0 " No request " 1 " Request park Shift " 2 " Invalid " 3 " Reserved " ;
VAL_ 683 Longctrl_Decel_ReqValue_DVR 0 " Valid value " ;
VAL_ 683 Longctrl_HCUTrqReqActive_DVR 0 " Not active " 1 " Active " ;
VAL_ 683 HWA_SnvtySet_Resp 0 " Normal " 1 " High sensitivity " 2 " Low sensitivity " 3 " Reserved " ;
VAL_ 683 HWA_Resp 0 " OFF " 1 " ON " ;
VAL_ 683 ALC_Resp 0 " OFF " 1 " ON " ;
VAL_ 683 ALC_InterSysInfoDisp 0 " No display " 1 " Automatic lane change function failure " 2 " Reserve " ;
VAL_ 683 RollingCounter_ACC3 0 " Valid value " 15 " Invalid value " ;
VAL_ 683 Checksum_ACC8 0 " Valid value " ;
VAL_ 683 Longctrl_HCUTrqReq_DVR 0 " Valid value " ;
VAL_ 683 HWA_warning 0 " No Warning " 1 " Warning Level 1 " 2 " Warning Level 2 " 3 " Warning Level 3 " ;
VAL_ 683 HWA_ModDisp 0 " OFF " 1 " Safstop " 2 " Passive " 3 " Ready " 4 " Active " 5 " Override " 6 " Slow retreat " 7 " Standstill " 8 " Reserved " 15 " Fault " ;
VAL_ 683 HWA_InterSysInfoDisp 0 " No display " 1 " Unable to activate HWA due to other limitation " 2 " HWA active control is cancelled   " 3 " Turn off the turn light " 4 " Active confirm " 5 " Overtime for lane change " 6 " lane change is cancelled " 7 " HWA temporary unavailable " 8 " Speed is too low to support lane change " 9 " HWA need to restart the engine " 10 " Take over request " 11 " Please Keep Attention " 12 " To cross the tunnel, please take over??in time " 13 " Have a branch road ahead. Please take over in time " 14 " Reserve " ;
VAL_ 683 HWA_LaneChangeReq 0 " No display  " 1 " left satisfied " 2 " right satisfied " 3 " left not satisfied " 4 " right not satisfied " 5 " reserved  " ;
VAL_ 683 HWA_LaneChange 0 " No display  " 1 " left  " 2 " right " 3 " reserved " ;
VAL_ 683 ADAS_DriverInloop_Monitor 0 " No Display " 1 " HOD Level 1 " 2 " HOD Level 2 " 3 " DAM Warning " 4 " Resvered  " ;
VAL_ 683 RollingCounter_ACC8 0 " Valid value " 15 " Invalid value " ;
VAL_ 683 Checksum_ACC4 0 " Valid value " ;
VAL_ 683 ACC_ObjDetecte 0 " No object " 1 " Target object detected " ;
VAL_ 683 ACC_TakeOverReq 0 " No TakeOver request " 1 " Valid TakeOver request " ;
VAL_ 683 ACC_InterSysInfoDisp 0 " No display " 1 " Unable to activate ACC due to speed not achive " 2 " ACC active control is cancelled " 3 " Resvered " 4 " ACC and PEBS temporary unavailable " 5 " Unable to activate ACC due to other limitation(except speed not achive) " 6 " ACC and PEBS error " 7 " ACC temporary unavailable " 8 " Resvered " 9 " Blindness " 10 " Resvered " ;
VAL_ 683 ACC_ModDisp 0 " OFF Mode " 1 " Passive Mode " 2 " StandBy Mode " 3 " Active-Control Mode " 4 " Brake-Only Mode " 5 " Override " 6 " Reserved " 7 " ACC and PEBS Failure mode " 8 " ACC Failure mode  " 9 " Reserved " ;
VAL_ 683 ACC_FctSts 0 " Fuction Not  Available " 1 " Fuction Available  " 2 " Performance degradation " 3 " Reserved " ;
VAL_ 683 ACC_TgtObjBarDisp 0 " No display " 1 " Distance_1 one bar " 2 " Distance_2 two bars " 3 " Distance_3 three bars " 4 " Distance_4 four bars " 5 " Resvered " ;
VAL_ 683 ACC_TimeGapSet 0 " No display " 1 " TimeGap_1 1s " 2 " TimeGap_2 1.4s " 3 " TimeGap_3 1.8s " 4 " TimeGap_4 2.1s " 5 " Reserved " ;
VAL_ 683 ACC_SpdSetValue 0 " Valid value " 255 " No display " ;
VAL_ 683 Longctrl_HazActv 0 " Not active " 1 " AEB active " 2 " Safestop active " 3 " Reserved " ;
VAL_ 683 TJA_ACC_SelSts 0 " off " 1 " ACC selected " 2 " TJA/ICA selected " 3 " Off selected " 4 " ACC on " 5 " TJA/ICA on " 6 " Reserved " ;
VAL_ 683 TJA_ICA_ModDisp 0 " OFF mode " 1 " Passive mode " 2 " Active mode " 3 " Ready mode " 4 " Failure " 5 " Reserved   " ;
VAL_ 683 TJA_ICA_InterSysInfoDisp 0 " No display " 1 " Unable to activate TJA/ICA due to other limitation " 2 " TJA/ICA active control is cancelled " 3 " TJA/ICA   temporarily unavailable    " 4 " Current IGN Cycle Function Inhibit " 5 " Resvered  " ;
VAL_ 683 ISL_InterSysInfoDisp 0 " No display " 1 " Speed Limit Confirm Request " 2 " Speed Limit Take Over Request " 3 " Resvered " ;
VAL_ 683 CruCha_ModDisp 0 " OFF mode " 1 " Idle mode " 2 " Ready mode " 3 " Active " 4 " Reserved " 5 " Warning Level 1 " 6 " Warning Level 2 " 7 " Warning Level 3 " 8 " Reserved " 9 " Failure " 10 " Reserved  " ;
VAL_ 683 CruChar_InterSysInfoDisp 0 " No display " 1 " Unable to activate CruiseChauffer due to other limitation " 2 " CruiseChauffer active control is cancelled " 3 " CruiseChauffer temporarily unavailable " 4 " Take over request " 5 " Current IGN Cycle Function Inhibit " 6 " Please Keep Attention " 7 " To cross the tunnel, please take over  in time " 8 " Have a branch road ahead. Please take over in time " 9 " Hands off warning " 10 " Reserved " ;
VAL_ 683 RollingCounter_ACC4 0 " Valid value " 15 " Invalid value " ;
VAL_ 683 Checksum_ACC6 0 " Valid value " ;
VAL_ 683 ACC_PotentialTgtDy 0 " Valid value " 161 " Reserved " ;
VAL_ 683 ACC_PotentialTgtDx 0 " Valid value " 301 " Reserved " ;
VAL_ 683 ACC_RlvTgtDetn 0 " Not dectected " 1 " Dectected " 2 " Reserved " 3 " Invalid " ;
VAL_ 683 ACC_EgoStatus 0 " No Display " 1 " Override " 2 " Deceleration " 3 " Reserved " ;
VAL_ 683 ACC_RlvTgtTyp 0 " Unkown " 1 " Sedan " 2 " Truck " 3 " Motorcycle " 4 " Pedestrian " 5 " Bicycle " 6 " Reserved " 7 " Invalid " ;
VAL_ 683 ACC_RlvTgtDy 0 " Valid value " 161 " Reserved " ;
VAL_ 683 ACC_RlvTgtDx 0 " Valid value " 301 " Reserved " ;
VAL_ 683 ACC_PotentialTgtDetn 0 " Not dectected " 1 " Dectected " 2 " Reserved " 3 " Invalid " ;
VAL_ 683 ACC_PotentialTgtTyp 0 " Unkown " 1 " Sedan " 2 " Truck " 3 " Motorcycle " 4 " Pedestrian " 5 " Bicycle " 6 " Reserved " 7 " Invalid " ;
VAL_ 683 IntelligentCurveAct 0 " inactive " 1 " active " ;
VAL_ 683 RollingCounter_ACC6 0 " Valid value " 15 " Invalid value " ;
VAL_ 683 Checksum_ACC7 0 " Valid value " ;
VAL_ 683 Request_driveoff 5 "Reserve" 4 " 0x4 " 3 " 0x3 " 0 " no request " 1 " The front car has started " 2 " The front car has started,Please pay attention to the road environment " ;
VAL_ 683 ACC_LeTgtDy 0 " Valid value " 161 " Reserved " ;
VAL_ 683 ACC_LeTgtDx 0 " Valid value " 301 " Reserved " ;
VAL_ 683 ACC_LeTgtTyp 0 " Unkown " 1 " Sedan " 2 " Truck " 3 " Motorcycle " 4 " Pedestrian " 5 " Bicycle " 6 " Reserved " 7 " Invalid " ;
VAL_ 683 ACC_LeTargrtDection 0 " Not dectected " 1 " Dectected " 2 " Reserved " 3 " Invalid " ;
VAL_ 683 ACC_RiTargrtDetn 0 " Not dectected " 1 " Dectected " 2 " Reserved " 3 " Invalid " ;
VAL_ 683 ACC_RiTgtDy 0 " Valid value " 161 " Reserved " ;
VAL_ 683 ACC_RiTgtDx 0 " Valid value " 301 " Reserved " ;
VAL_ 683 ACC_RiTgtTyp 0 " Unkown " 1 " Sedan " 2 " Truck " 3 " Motorcycle " 4 " Pedestrian " 5 " Bicycle " 6 " Reserved " 7 " Invalid " ;
VAL_ 683 RollingCounter_ACC7 0 " Valid value " 15 " Invalid value " ;
VAL_ 683 ACC_RlvTgtfusion 0 " no fusion " 1 " fusion " ;
VAL_ 683 ACC_RlvTgtHeading 0 " valid value " 61 " Reserved " ;
VAL_ 683 ACC_LeTgtfusion 0 " no fusion " 1 " fusion " ;
VAL_ 683 ACC_LeTgtHeading 0 " valid value " 61 " Reserved " ;
VAL_ 683 ACC_RiTgtfusion 0 " no fusion " 1 " fusion " ;
VAL_ 683 ACC_RiTgtHeading 0 " valid value " 61 " Reserved " ;
VAL_ 683 ACC_PotentialTgtfusion 0 " no fusion " 1 " fusion " ;
VAL_ 683 ACC_PotentialTgtHeading 0 " valid value " 61 " Reserved " ;
VAL_ 683 TargetCutinPro 0 " valid value " 50 " Reserved " ;
VAL_ 683 TargetCutoutPro 0 " valid value " 50 " Reserved " ;
VAL_ 692 AEB_LePedDetn 0 " Not dectected " 1 " Dectected " 2 " Reserved " 3 " Invalid " ;
VAL_ 692 AEB_LePedDy 0 " Valid value " 161 " Reserved " ;
VAL_ 692 AEB_LePedTyp 0 " Unkown " 1 " Sedan " 2 " Truck " 3 " Motorcycle " 4 " Pedestrian " 5 " Bicycle " 6 " Reserved " 7 " Invalid " ;
VAL_ 692 AEB_LePed_collisionprob 0 " no collisionprob " 1 " collisionprob " ;
VAL_ 692 AEB_RiPedDetn 0 " Not dectected " 1 " Dectected " 2 " Reserved " 3 " Invalid " ;
VAL_ 692 AEB_RiPedDy 0 " Valid value " 161 " Reserved " ;
VAL_ 692 AEB_RiPedTyp 0 " Unkown " 1 " Sedan " 2 " Truck " 3 " Motorcycle " 4 " Pedestrian " 5 " Bicycle " 6 " Reserved " 7 " Invalid " ;
VAL_ 692 AEB_RiPed_collisionprob 0 " no collisionprob " 1 " collisionprob " ;
VAL_ 692 AEB_LeCyclistDy 0 " Valid value " 161 " Reserved " ;
VAL_ 692 AEB_LeCyclist_collisionprob 0 " no collisionprob " 1 " collisionprob " ;
VAL_ 692 AEB_RiCyclistDy 0 " Valid value " 161 " Reserved " ;
VAL_ 692 AEB_RiCyclist_collisionprob 0 " no collisionprob " 1 " collisionprob " ;
VAL_ 692 JAPedObjExist 0 " Valid Value " ;
VAL_ 692 AEBJAObjID 0 " Valid Value " 255 " No Object " ;
VAL_ 692 AEBJAObjExist 0 " Valid Value " ;
VAL_ 692 JAPedObjID 0 " Valid Value " 255 " No Object " ;
VAL_ 692 AEBJAObjVideoCfmd 0 " No Fusion " 1 " Fusion " ;
VAL_ 692 AEBJAObjVx 0 " Valid Value " 4081 " Reserved " ;
VAL_ 692 AEBJAObjDx 0 " Valid Value " ;
VAL_ 692 JAPedObjVideoCfmd 0 " No Fusion " 1 " Fusion " ;
VAL_ 692 AEBJAObjState 0 " UNDEFINED " 1 " PRECEDING " 2 " STATIONARY " 3 " STOPPED " 4 " ONCOMING " 5 " Reserved " ;
VAL_ 692 AEBJAObjCntAlive 0 " Valid Value " 3856 " Reserved " ;
VAL_ 692 AEBJAObjDy 0 " Valid Value " ;
VAL_ 692 JAPedObjState 0 " UNDEFINED " 1 " PRECEDING " 2 " STATIONARY " 3 " STOPPED " 4 " ONCOMING " 5 " Reserved " ;
VAL_ 692 AEBJAObjObstcl 0 " Valid Value " ;
VAL_ 692 AEBJAObjVy 0 " Valid Value " ;
VAL_ 692 AEBJAObjAx 0 " Valid Value " ;
VAL_ 692 AEBJAObjAy 0 " Valid Value " ;
VAL_ 692 JAPedObjObstcl 0 " Valid Value " ;
VAL_ 692 JAPedObjDy 0 " Valid Value " ;
VAL_ 692 JAPedObjDx 0 " Valid Value " ;
VAL_ 692 FCWAEB_JATTC 0 " No Display " 1 " valid value " ;
VAL_ 692 JAPedObjVx 0 " Valid Value " 4081 " Reserved " ;
VAL_ 692 JAPedObjVy 0 " Valid Value " ;
VAL_ 692 JAPedObjAy 0 " Valid Value " ;
VAL_ 692 JAPedObjCntAlive 0 " Valid Value " 3856 " Reserved " ;
VAL_ 692 AEB_LePedHeading 0 " valid value " 61 " Reserved " ;
VAL_ 692 AEB_RiPedHeading 0 " valid value " 61 " Reserved " ;
VAL_ 692 AEB_LeCyclistHeading 0 " valid value " 61 " Reserved " ;
VAL_ 692 AEB_RiCyclistHeading 0 " valid value " 61 " Reserved " ;
VAL_ 692 FCWAEB_longTTC 0 " No Display " 1 " valid value " ;
VAL_ 692 FCWAEB_crossingTTC 0 " No Display " 1 " valid value " ;
VAL_ 692 JAPedObjAx 0 " Valid Value " ;
VAL_ 692 AEB_LePedDx 0 " Valid value " 301 " Reserved " ;
VAL_ 692 AEB_RiPedDx 0 " Valid value " 301 " Reserved " ;
VAL_ 692 AEB_LeCyclistDetn 0 " Not dectected " 1 " Dectected " 2 " Reserved " 3 " Invalid " ;
VAL_ 692 AEB_LeCyclistDx 0 " Valid value " 301 " Reserved " ;
VAL_ 692 AEB_LeCyclistTyp 0 " Unkown " 1 " Sedan " 2 " Truck " 3 " Motorcycle " 4 " Pedestrian " 5 " Bicycle " 6 " Reserved " 7 " Invalid " ;
VAL_ 692 AEB_RiCyclistDetn 0 " Not dectected " 1 " Dectected " 2 " Reserved " 3 " Invalid " ;
VAL_ 692 AEB_RiCyclistDx 0 " Valid value " 301 " Reserved " ;
VAL_ 692 AEB_RiCyclistTyp 0 " Unkown " 1 " Sedan " 2 " Truck " 3 " Motorcycle " 4 " Pedestrian " 5 " Bicycle " 6 " Reserved " 7 " Invalid " ;
VAL_ 696 AEBObjID 0 " Valid Value " 255 " No Object " ;
VAL_ 696 AEBObjExist 0 " Valid Value " ;
VAL_ 696 AEBObjVideoCfmd 0 " No Fusion " 1 " Fusion " ;
VAL_ 696 AEBObjVx 0 " Valid Value " 4081 " Reserved " ;
VAL_ 696 AEBObjDx 0 " Valid Value " ;
VAL_ 696 AEBObjCntAlive 0 " Valid Value " 3856 " Reserved " ;
VAL_ 696 AEBObjDy 0 " Valid Value " ;
VAL_ 696 AEBObjState 0 " UNDEFINED " 1 " PRECEDING " 2 " STATIONARY " 3 " STOPPED " 4 " Reserved " ;
VAL_ 696 AEBObjObstcl 0 " Valid Value " ;
VAL_ 696 AEBObjVy 0 " Valid Value " ;
VAL_ 696 CyclistObjExist 0 " Valid Value " ;
VAL_ 696 AEBObjAx 0 " Valid Value " ;
VAL_ 696 AEBObjAy 0 " Valid Value " ;
VAL_ 696 CyclistObjDx 0 " Valid Value " ;
VAL_ 696 CyclistObjID 0 " Valid Value " 255 " No Object " ;
VAL_ 696 CyclistObjObstcl 0 " Valid Value " ;
VAL_ 696 CyclistObjDy 0 " Valid Value " ;
VAL_ 696 CyclistObjVx 0 " Valid Value " 4081 " Reserved " ;
VAL_ 696 CyclistObjCntAlive 0 " Valid Value " 3856 " Reserved " ;
VAL_ 696 CyclistObjVy 0 " Valid Value " ;
VAL_ 696 CyclistObjState 0 " UNDEFINED " 1 " PRECEDING " 2 " STATIONARY " 3 " STOPPED " 4 " Reserved " ;
VAL_ 696 CyclistObjVideoCfmd 0 " No Fusion " 1 " Fusion " ;
VAL_ 696 CyclistObjAx 0 " Valid Value " ;
VAL_ 696 CyclistObjAy 0 " Valid Value " ;
VAL_ 696 PedObjExist 0 " Valid Value " ;
VAL_ 696 PedObjID 0 " Valid Value " 255 " No Object " ;
VAL_ 696 PedObjObstcl 0 " Valid Value " ;
VAL_ 696 PedObjDy 0 " Valid Value " ;
VAL_ 696 PedObjDx 0 " Valid Value " ;
VAL_ 696 PedObjVx 0 " Valid Value " 4081 " Reserved " ;
VAL_ 696 PedObjVy 0 " Valid Value " ;
VAL_ 696 PedObjVideoCfmd 0 " No Fusion " 1 " Fusion " ;
VAL_ 696 ACCTgtObjDx 0 " Valid Value " ;
VAL_ 696 PedObjAy 0 " Valid Value " ;
VAL_ 696 PedObjCntAlive 0 " Valid Value " 3856 " Reserved " ;
VAL_ 696 PedObjAx 0 " Valid Value " ;
VAL_ 696 ACCTgtObjID 0 " Valid Value " 255 " No Object " ;
VAL_ 696 ACCTgtObjObstcl 0 " Valid Value " ;
VAL_ 696 ACCTgtObjDy 0 " Valid Value " ;
VAL_ 696 ACCTgtObjExist 0 " Valid Value " ;
VAL_ 696 ACCTgtObjVy 0 " Valid Value " ;
VAL_ 696 ACCTgtObjVx 0 " Valid Value " 4081 " Reserved " ;
VAL_ 696 ACCTgtObjAx 0 " Valid Value " ;
VAL_ 696 ACCTgtObjAy 0 " Valid Value " ;
VAL_ 696 ACCTgtObjState 0 " UNDEFINED " 1 " PRECEDING " 2 " STATIONARY " 3 " STOPPED " 4 " Reserved " ;
VAL_ 696 ACCTgtObjVideoCfmd 0 " No Fusion " 1 " Fusion " ;
VAL_ 696 ACCTgtObjCntAlive 0 " Valid Value " 3856 " Reserved " ;
VAL_ 696 RadarHorMisalign 0 " Valid Value " ;
VAL_ 696 HandsoffDetd 0 " Unknown " 1 " Hands off " 2 " Not hands off " 3 " Reserved " ;
VAL_ 696 DrvgOnHiWay 0 " Unknown " 1 " On Hignway " 2 " Not on hgh way " 3 " Reserved " ;
VAL_ 696 RoadCrvt 0 " Valid Value(Left bend) " 511 " Straightaway " 512 " Valid Value((Reft bend)) " 1022 " Reserved " 1023 " Unknown " ;
VAL_ 696 SpdLimitDst 0 " Valid Value " 61 " Out of Range " 62 " Reserved " 63 " Unknown " ;
VAL_ 696 RoadCrvtFar 0 " Valid Value(Left bend) " 511 " Straightaway " 512 " Valid Value((Reft bend)) " 1022 " Reserved " 1023 " Unknown " ;
VAL_ 696 RampDst 0 " Valid Value " 61 " Out of Range " 62 " Reserved " 63 " Unknown " ;
VAL_ 696 SpdLimit 0 " No SPL " 1 " SPL 5 " 2 " SPL 10 " 3 " SPL 15 " 4 " SPL 20 " 5 " SPL 25 " 6 " SPL 30 " 7 " SPL 35 " 8 " SPL 40 " 9 " SPL 45 " 10 " SPL 50 " 11 " SPL 55 " 12 " SPL 60 " 13 " SPL 65 " 14 " SPL 70 " 15 " SPL 75 " 16 " SPL 80 " 17 " SPL 85 " 18 " SPL 90 " 19 " SPL 95 " 20 " SPL 100 " 21 " SPL 105 " 22 " SPL 110 " 23 " SPL 115 " 24 " SPL 120 " 25 " SPL 120 " 26 " SPL 130 " 27 " SPL 135 " 28 " SPL 140 " 29 " SPL 145 " 30 " SPL 150 " 31 " Reserved " 63 " Invalid " ;
VAL_ 696 CurveDst 0 " Valid Value " 61 " Out of Range " 62 " Reserved " 63 " Unknown " ;
VAL_ 696 NavSpdLimUnit 0 " Unknown " 1 " KMH " 2 " MPH " 3 " Reserved " ;
VAL_ 696 TunnelDst 0 " Valid Value " 61 " Out of Range " 62 " Reserved " 63 " Unknown " ;
VAL_ 696 DrvgOnRiLane 0 " Unknown " 1 " On right most lane " 2 " Not on right most lane " 3 " Reserved " ;
VAL_ 696 BrdgDst 0 " Valid Value " 61 " Out of Range " 62 " Reserved " 63 " Unknown " ;
VAL_ 696 RadarDrvrAttentive 0 " Inattentive " 1 " Attentive " ;
VAL_ 696 ACC_DataRecReq 0 " No Demand " 1 " TakeOver Demand " 2 " SafeStop Demand " 3 " AEB Demand " 4 " Reserved " ;
VAL_ 696 ACC_SOSReq 0 " No Request " 1 " Request " 2 " Reserved " 3 " Invalid " ;
VAL_ 696 PedObjState 0 " UNDEFINED " 1 " PRECEDING " 2 " STATIONARY " 3 " STOPPED " 4 " Reserved " ;
VAL_ 696 MapDataValid 0 " Valid " 1 " Invalid " ;
VAL_ 696 DrvrSts 0 " Good " 1 " Unbelievable " 2 " Low " 3 " Middle " 4 " High Level 1 " 5 " High Level 2 " 6 " Reserved " ;
VAL_ 696 AEBObjOverlap 0 " Valid  " 21 " reserved  " 31 " invalid " ;
VAL_ 696 AEBObjDrvby 0 " Valid  " 21 " reserved  " 31 " invalid " ;
VAL_ 707 IFC_SnvtySet 0 " Normal " 1 " High sensitivity " 2 " Low sensitivity " 3 " Reserved " ;
VAL_ 707 DOWSwtReq 0 " OFF " 1 " ON " ;
VAL_ 707 AEB_PedSwtReq 0 " OFF " 1 " ON " ;
VAL_ 707 LCASwtReq 0 " OFF " 1 " ON " ;
VAL_ 707 RCTASwtReq 0 " OFF " 1 " ON " ;
VAL_ 707 RCTABrkSwtReq 0 " OFF " 1 " ON " ;
VAL_ 707 RCWSwtReq 0 " OFF " 1 " ON " ;
VAL_ 707 FCW_SnvtySet 0 " Normal " 1 " High sensitivity " 2 " Low sensitivity " 3 " Reserved " ;
VAL_ 707 AEB_VehSwtReq 0 " OFF " 1 " ON " ;
VAL_ 707 LKASwtReq 0 " OFF " 1 " ON " ;
VAL_ 707 LCKSwtReq 0 " OFF " 1 " ON " ;
VAL_ 707 ELKSwtReq 0 " OFF " 1 " ON " ;
VAL_ 707 ESS_PedSwtReq 0 " OFF " 1 " ON " ;
VAL_ 707 ESS_VehSwtReq 0 " OFF " 1 " ON " ;
VAL_ 707 LDWSwtReq 0 " OFF " 1 " ON " ;
VAL_ 707 TSRSwtReq 0 " OFF " 1 " ON " ;
VAL_ 707 TSRWarnSwtReq 0 " OFF " 1 " ON " ;
VAL_ 707 ICA_HandsOffSwtReq 0 " OFF " 1 " ON " ;
VAL_ 707 ISLSwtReq 0 " OFF " 1 " ON " ;
VAL_ 707 TSR_SnvtySet 0 " valid " 31 " Invalid " ;
VAL_ 707 LSSWarnFormSwtReq 0 " Voice " 1 " Haptic " 2 " Voice+Haptic " 3 " Reserved " ;
VAL_ 707 LSSSwtReq 0 " OFF " 1 " ON " ;
VAL_ 707 IntelligentEvaSwtReq 0 " OFF " 1 " ON " ;
VAL_ 707 NavVehToTrafEyeDist 0 " Valid value " ;
VAL_ 707 NavRoadType 0 " Unknown " 1 " Expressway " 2 " City expressway " 3 " National rode " 4 " Provincial rode " 5 " County rode " 6 " City or Village rode " 7 " ramp " 8 " Tunnel " 9 " Side rode " 10 " Channel " 11 " Reserved " ;
VAL_ 707 NavSpdLimType 0 " Unknown " 1 " Traffic sign " 2 " Electronic eye " 3 " Rode Default " ;
VAL_ 707 NavSpdLimValue 0 " No Display " 1 " SPL 5 " 2 " SPL 10 " 3 " SPL 15 " 4 " SPL 20 " 5 " SPL 25 " 6 " SPL 30 " 7 " SPL 35 " 8 " SPL 40 " 9 " SPL 45 " 10 " SPL 50 " 11 " SPL 55 " 12 " SPL 60 " 13 " SPL 65 " 14 " SPL 70 " 15 " SPL 75 " 16 " SPL 80 " 17 " SPL 85 " 18 " SPL 90 " 19 " SPL 95 " 20 " SPL 100 " 21 " SPL 105 " 22 " SPL 110 " 23 " SPL 115 " 24 " SPL 120 " 25 " SPL 125 " 26 " SPL 130 " 27 " SPL 135 " 28 " SPL 140 " 29 " SPL 145 " 30 " SPL 150 " 31 " Reserved " 63 " Invalid " ;
VAL_ 707 NavSpdLimUnit_HUT 0 " Unknown " 1 " KMH " 2 " MPH " 3 " Reserved " ;
VAL_ 707 NavCtryType 0 " Reserved " 156 " China " 157 " Reserved " ;
VAL_ 707 NavSpdLimSignSts 0 " Unknow " 1 " Exist SPL sign " 2 " Exist Traffic sign " 3 " Exist SPL and Traffic sign " 4 " None " 5 " Plural " 6 " Reserved " ;
VAL_ 707 NavTSRTrafSign 0 " None " 1 " Snow  " 2 " Fog  " 3 " ThunderStorm  " 4 " Rain  " 5 " FWay  " 6 " EFWay  " 7 " Straight  " 8 " FrontageLeft  " 9 " TurnLeftRight  " 10 " FrontageRight  " 11 " Right  " 12 " TurnRight  " 13 " Left  " 14 " TurnLeft  " 15 " RelieveNoOvertake  " 16 " NoOvertake  " 17 " StopGiveWay  " 18 " GiveWay  " 19 " NoPass  " 20 " NoEntry  " 21 " NoCar  " 22 " NoTruck  " 23 " NoBus  " 24 " NoTurnaround  " 25 " NoStraightLeftTurn  " 26 " NoStraightRightTurn  " 27 " NoLeftRightTurn  " 28 " NoLeftTurn  " 29 " NoRightTurn  " 30 " NoStraight  " 31 " WarnKids  " 32 " WarnPed  " 33 " WarnBike  " 34 " WarnWorks  " 35 " WarnWildanimal  " 36 " WarnCattle  " 37 " ACCidentProneSection  " 38 " Town  " 39 " Slow  " 40 " SharpTurnR  " 41 " SharpTurnL  " 42 " ReverseCurveL  " 43 " ReverseCurveR  " 44 " ContinuousBend  " 45 " Crossroads  " 46 " ConfluenceR  " 47 " ConfluenceL  " 48 " Reserved  " 255 " Invalid  " ;
VAL_ 707 FCTASwtReq 0 " OFF " 1 " ON " ;
VAL_ 707 AESSwtReq 0 " OFF " 1 " ON " ;
VAL_ 707 FCTABrkSwtReq 0 " OFF " 1 " ON " ;
VAL_ 707 HWA_SwtReq 0 " OFF " 1 " ON " ;
VAL_ 707 HWA_SnvtySet 0 " Normal " 1 " High sensitivity " 2 " Low sensitivity " 3 " Reserved " ;
VAL_ 707 AEB_JASwtReq 0 " OFF " 1 " ON " ;
VAL_ 707 ALC_SwtReq 0 " OFF " 1 " ON " ;
VAL_ 707 ADAS_Posn_MsgTye 0 " System Specific " 1 " Position " 2 " Segment " 3 " Stub " 4 " Profile Short " 5 " Profile Long " 6 " Meta-data " 7 " Reserved " ;
VAL_ 707 ADAS_Posn_Offset 0 " Valid value " 8191 " Invalid data " ;
VAL_ 707 ADAS_Posn_CycCnt 0 " Valid value " ;
VAL_ 707 ADAS_Posn_Pathldx 0 " Valid value " ;
VAL_ 707 ADAS_Posn_Idx 0 " Valid value " ;
VAL_ 707 ADAS_Posn_PosProbb 0 " Unknown " 1 " Valid data " 31 " Invalid " ;
VAL_ 707 ADAS_Posn_Age 0 " 0~2545ms " 510 " >2545ms " 511 " Invalid data " ;
VAL_ 707 ADAS_Posn_PosConfdc 0 " Valid value " 7 " Invalid value " ;
VAL_ 707 ADAS_Posn_CurLane 0 " Unknown " 1 " Emergency lane " 2 " Single-lane road " 3 " Left-most lane " 4 " Right-most lane " 5 " One of middle lanes on road with three or more lanes  " 6 " Reserved " 7 " Invalid data " ;
VAL_ 707 ADAS_Posn_Spd 0 " б▄ -12.8 m/s " 1 " (-12.6)~(-0.2)m/s " 64 " Standing still " 65 " (+0.2)~(+89.0)m/s " 510 " б▌ +89.2 m/s " 511 " Invalid data " ;
VAL_ 707 ADAS_Posn_Rehead 0 " In path direction " 1 " 1.417 degrees right " 2 " Right from path direction " 126 " 178.583 degrees right " 127 " Opposite direction " 128 " 178.583 degrees left (181.417 degrees right) " 129 " Left from path direction " 253 " 1.417 degrees left (358.583 degrees right) " 254 " Unknown " 255 " Invalid " ;
VAL_ 714 RSDS_Driver_LED_Sts 0 " no error " 1 " error " ;
VAL_ 714 DrvMirrFold_UnfoldSts 0 " Unfold " 1 " Fold " ;
VAL_ 717 PassMirrFold_UnfoldSts 0 " Unfold " 1 " Fold " ;
VAL_ 717 RSDS_Pass_LED_Sts 0 " no error " 1 " error " ;
VAL_ 719 Checksum_IFC7 0 " Valid value " ;
VAL_ 719 TSRResp 0 " OFF " 1 " ON " ;
VAL_ 719 TSRSpdLimUnit 0 " Unknown " 1 " KMH " 2 " MPH " 3 " Reserved " ;
VAL_ 719 TSRSpdLim 0 " No Display " 1 " SPL 5 " 2 " SPL 10 " 3 " SPL 15 " 4 " SPL 20 " 5 " SPL 25 " 6 " SPL 30 " 7 " SPL 35 " 8 " SPL 40 " 9 " SPL 45 " 10 " SPL 50 " 11 " SPL 55 " 12 " SPL 60 " 13 " SPL 65 " 14 " SPL 70 " 15 " SPL 75 " 16 " SPL 80 " 17 " SPL 85 " 18 " SPL 90 " 19 " SPL 95 " 20 " SPL 100 " 21 " SPL 105 " 22 " SPL 110 " 23 " SPL 115 " 24 " SPL 120 " 25 " SPL 125 " 26 " SPL 130 " 27 " SPL 135 " 28 " SPL 140 " 29 " SPL 145 " 30 " SPL 150 " 31 " Reserved " 63 " Invalid " ;
VAL_ 719 TSRSpdLimCfdc 0 " Null " 1 " Implicit " 2 " Explicit " 3 " Reserved " ;
VAL_ 719 TSRSts 0 " Off " 1 " Fusion mode " 2 " Vision mode " 3 " Navigation only mode " 4 " Failed " 5 " Reserved " ;
VAL_ 719 TSRSpdLimSts 0 " No Speed Limit " 1 " Speed Limit                       " 2 " Speed Limit Cancel   " 3 " Reserved " ;
VAL_ 719 TSRTrfcSignValCfdc 0 " Null " 1 " Implicit " 2 " Explicit " 3 " Reserved " ;
VAL_ 719 TSRTrfcSignVal 0 " None  " 1 " Snow  " 2 " Fog  " 3 " ThunderStorm  " 4 " Rain  " 5 " FWay  " 6 " EFWay  " 7 " Straight  " 8 " FrontageLeft  " 9 " TurnLeftRight  " 10 " FrontageRight  " 11 " Right  " 12 " TurnRight  " 13 " Left  " 14 " TurnLeft  " 15 " RelieveNoOvertake  " 16 " NoOvertake  " 17 " StopGiveWay  " 18 " GiveWay  " 19 " NoPass  " 20 " NoEntry  " 21 " NoCar  " 22 " NoTruck  " 23 " NoBus  " 24 " NoTurnaround  " 25 " NoStraightLeftTurn  " 26 " NoStraightRightTurn  " 27 " NoLeftRightTurn  " 28 " NoLeftTurn  " 29 " NoRightTurn  " 30 " NoStraight  " 31 " WarnKids  " 32 " WarnPed  " 33 " WarnBike  " 34 " WarnWorks  " 35 " WarnWildanimal  " 36 " WarnCattle  " 37 " ACCidentProneSection  " 38 " Town  " 39 " Slow  " 40 " SharpTurnR  " 41 " SharpTurnL  " 42 " ReverseCurveL  " 43 " ReverseCurveR  " 44 " ContinuousBend  " 45 " Crossroads  " 46 " ConfluenceR  " 47 " ConfluenceL  " 48 " Rain/Wetness " 49 " Snow/Icy " 50 " Time " 51 " Distance For " 52 " Distance In " 53 " Straight " 54 " FrontageLeft " 55 " TurnLeftRight " 56 " FrontageRight " 57 " Right " 58 " Turn Right " 59 " Left " 60 " Turn Left " 61 " Highway Start " 62 " Highway End " 63 " Mortorway Start " 64 " Mortorway End " 65 " City Entry " 66 " City Exit " 67 " Residential zones Entry " 68 " Residential zones Exit " 69 " Trailer " 70 " Reserved  " 255 " Invalid  " ;
VAL_ 719 TSRSpdLimWarn 0 " No Warning " 1 " Warning " ;
VAL_ 719 TSRWarnResp 0 " OFF " 1 " ON " ;
VAL_ 719 TSR_Snvty 0 " valid " 31 " Invalid " ;
VAL_ 719 HMA_Sts 0 " off " 1 " passive " 2 " active " 3 " Temporary fault " 4 " Permanently  fault " 5 " reserved. " ;
VAL_ 719 HMA_HibeamReq 0 " High beam request OFF " 1 " High beam request ON " 2 " High beam and laser beam request ON " 3 " Reserved " ;
VAL_ 719 RollingCounter_IFC7 0 " Valid value " 15 " Invalid value " ;
VAL_ 728 ADAS_Stub_MsgTyp 0 " System Specific " 1 " Position " 2 " Segment " 3 " Stub " 4 " Profile Short " 5 " Profile Long " 6 " Meta-data " 7 " Reserved " ;
VAL_ 728 ADAS_Stub_Offset 0 " Valid data " 8191 " Invalid data " ;
VAL_ 728 ADAS_Stub_CycCnt 0 " Valid value " ;
VAL_ 728 ADAS_Stub_PathIdx 0 " Valid value " ;
VAL_ 728 ADAS_Stub_StubPathIdx 0 " Valid value " ;
VAL_ 728 ADAS_Stub_Retr 0 " False " 1 " True " ;
VAL_ 728 ADAS_Stub_Update 0 " False " 1 " True " ;
VAL_ 728 ADAS_Stub_RelProbb 0 " unknown " 1 " Valid data " 31 " Invalid " ;
VAL_ 728 ADAS_Stub_FuncRoadClass 0 " Unkown " 1 " Expressway " 2 " City expressway " 3 " National road " 4 " Provincial rode or County road " 5 " City or Village road " 6 " Other road " 7 " Invalid " ;
VAL_ 728 ADAS_Stub_PartOfCalcRoute 0 " New path from this point on is not part of Calculated Route " 1 " New path from this point on is part of Calculated Route " 2 " Unknown " 3 " invalid " ;
VAL_ 728 ADAS_Stub_CmplxInsct 0 " New path is not part of complex intersection " 1 " New path is part of a complex intersection " 2 " Unknown " 3 " invalid " ;
VAL_ 728 ADAS_Stub_FormOfWay 0 " Unkown " 1 " Freeway or Controlled Access road that is not a slip road/ramp " 2 " Multiple Carriageway or Multiply Digitized Road " 3 " Single Carriageway (default) " 4 " Roundabout Circle " 5 " Traffic Square/Special Traffic Figure " 6 " Reserved " 8 " Parallel Road (as special type of a slip road/ramp) " 9 " Slip Road/Ramp on a Freeway or Controlled ACCess road " 10 " Slip Road/Ramp (not on a Freeway or Controlled ACCess road) " 11 " Service Road or Frontage Road " 12 " Entrance to or exit of a Car Park " 13 " Entrance to or exit to Service " 14 " Pedestrian Zone " 15 " Unknow " ;
VAL_ 728 ADAS_Stub_TurnAngl 0 " In path direction " 1 " 1.417 degrees right " 2 " Right from path direction " 126 " 178.583 degrees right " 127 " Opposite direction " 128 " 178.583 degrees left (181.417 degrees right) " 129 " Left from path direction " 253 " 1.417 degrees left (358.583 degrees right) " 254 " Unknown " 255 " Invalid " ;
VAL_ 728 ADAS_Stub_LastStub 0 " False " 1 " True " ;
VAL_ 728 ADAS_Stub_RtOfWay 0 " Drvg towards this stub has priority over all conflicting vehicle movements " 1 " Drvg towards this stub might require yielding to conflicting vehicle movements " 2 " Unknown " 3 " Invalid " ;
VAL_ 728 ADAS_Stub_NumOfLaneOppDir 0 " one-direction road " 1 " one lane only " 2 " indicates 2 or more lanes " 3 " invalid " ;
VAL_ 728 ADAS_Stub_NumOfLaneDrvDir 0 " One-direction road driven in wrong direction " 1 " Verbatim values " 6 " 6 or more lanes " 7 " invalid " ;
VAL_ 730 ADAS_Seg_MsgTyp 0 " System Specific " 1 " Position " 2 " Segment " 3 " Stub " 4 " Profile Short " 5 " Profile Long " 6 " Meta-data " 7 " Reserved " ;
VAL_ 730 ADAS_Seg_Offset 0 " Valid data " 8191 " Invalid data " ;
VAL_ 730 ADAS_Seg_CycCnt 0 " Valid value " ;
VAL_ 730 ADAS_Seg_PathIdx 0 " Valid value " ;
VAL_ 730 ADAS_Seg_Tunnel 0 " Segment is not part of a tunnel " 1 " Segment is part of a tunnel " 2 " Unknown " 3 " Invalid " ;
VAL_ 730 ADAS_Seg_Brdg 0 " Segment is not part of a bridge " 1 " Segment is part of a bridge " 2 " Unknown " 3 " Invalid " ;
VAL_ 730 ADAS_Seg_BuildUpArea 0 " Segment is not part of a built-up area " 1 " Segment is part of a built-up area " 2 " Unknown " 3 " Invalid " ;
VAL_ 730 ADAS_Seg_Retr 0 " False " 1 " True " ;
VAL_ 730 ADAS_Seg_Update 0 " False " 1 " True " ;
VAL_ 730 ADAS_Seg_RelProbb 0 " Unknown " 1 " Valid data " 31 " Invalid " ;
VAL_ 730 ADAS_Seg_FuncRoadClass 0 " Unkown " 1 " Expressway " 2 " City expressway " 3 " National road " 4 " Provincial rode or County road " 5 " City or Village road " 6 " Other road " 7 " Invalid " ;
VAL_ 730 ADAS_Seg_PartOfCalcRoute 0 " Segment is not part of Calculated Route " 1 " Segment is part of Calculated Route " 2 " Unknown " 3 " Invalid " ;
VAL_ 730 ADAS_Seg_CmplxInsct 0 " Segment is not part of complex intersection " 1 " Segment is part of a complex intersection " 2 " Unknown " 3 " Invalid " ;
VAL_ 730 ADAS_Seg_FormOfWay 0 " Unkown " 1 " Freeway or Controlled Access road that is not a slip road/ramp " 2 " Multiple Carriageway or Multiply Digitized Road " 3 " Single Carriageway (default) " 4 " Roundabout Circle " 5 " Traffic Square/Special Traffic Figure " 6 " Reserved " 8 " Parallel Road (as special type of a slip road/ramp) " 9 " Slip Road/Ramp on a Freeway or Controlled ACCess road " 10 " Slip Road/Ramp (not on a Freeway or Controlled ACCess road) " 11 " Service Road or Frontage Road " 12 " Entrance to or exit of a Car Park " 13 " Entrance to or exit to Service " 14 " Pedestrian Zone " 15 " Unknow " ;
VAL_ 730 ADAS_Seg_EffSpdLmt 0 " Unknown (including variable speed sign controlled) " 1 " value б▄ 5 km/h [mph] " 2 " 5 < value б▄ 7 km/h [mph] " 3 " 7 < value б▄ 10 km/h [mph] " 4 " 10 < value б▄ 15 km/h [mph] " 5 " 15 < value б▄ 20 km/h [mph] " 6 " 20 < value б▄ 25 km/h [mph] " 7 " 25 < value б▄ 30 km/h [mph] " 8 " 30 < value б▄ 35 km/h [mph] " 9 " 35 < value б▄ 40 km/h [mph] " 10 " 40 < value б▄ 45 km/h [mph] " 11 " 45 < value б▄ 50 km/h [mph] " 12 " 50 < value б▄ 55 km/h [mph] " 13 " 55 < value б▄ 60 km/h [mph] " 14 " 60 < value б▄ 65 km/h [mph] " 15 " 65 < value б▄ 70 km/h [mph] " 16 " 70 < value б▄ 75 km/h [mph] " 17 " 75 < value б▄ 80 km/h [mph] " 18 " 80 < value б▄ 85 km/h [mph] " 19 " 85 < value б▄ 90 km/h [mph] " 20 " 90 < value б▄ 95 km/h [mph] " 21 " 95 < value б▄ 100 km/h [mph] " 22 " 100 < value б▄ 105 km/h [mph] " 23 " 105 < value б▄ 110 km/h [mph] " 24 " 110 < value б▄ 115 km/h [mph] " 25 " 115 < value б▄ 120 km/h [mph] " 26 " 120 < value б▄ 130 km/h [mph] " 27 " 130 < value б▄ 140 km/h [mph] " 28 " 140 < value б▄ 150 km/h [mph] " 29 " 150 < value < unlimited " 30 " Unlimited " 31 " N/A " ;
VAL_ 730 ADAS_Seg_EffSpdLmtTyp 0 " Implicit (for instance, default speed limit in the cities) " 1 " Explicit иC on traffic sign " 2 " Explicit иC by night " 3 " Explicit иC by day " 4 " Explicit иC time of day " 5 " Explicit иC Electronic eye " 6 " Explicit иC snow " 7 " Unknown " ;
VAL_ 730 ADAS_Seg_DivideRoad 0 " Segment is not part of a divided road/dual carriageway " 1 " Segment is part of a divided road/dual carriageway " 2 " Unknown " 3 " N/A " ;
VAL_ 730 ADAS_Seg_NumOfLaneOppDir 0 " One-direction road " 1 " One lane only " 2 " Indicates 2 or more lanes " 3 " Invalid " ;
VAL_ 730 ADAS_Seg_NumOfLaneDrvDir 0 " One-direction road driven in wrong direction " 1 " Verbatim values " 6 " Six or more lanes " 7 " invalid " ;
VAL_ 733 ADAS_ProfShort_MsgTyp 0 " System Specific " 1 " Position " 2 " Segment " 3 " Stub " 4 " Profile Short " 5 " Profile Long " 6 " Meta-data " 7 " Reserved " ;
VAL_ 733 ADAS_ProfShort_Offset 0 " 0-8190m " 8191 " Invalid " ;
VAL_ 733 ADAS_ProfShort_CycCnt 0 " Valid value " ;
VAL_ 733 ADAS_ProfShort_PathIdx 0 " Valid value " ;
VAL_ 733 ADAS_ProfShort_ProfTyp 0 " Unknow " 1 " Curvature " 2 " Route Number Types " 3 " Slopeгиstepгй " 4 " Slopeгиlinerгй " 5 " Road ACCessibility " 6 " Road condition " 7 " Variable Speed Sign Position " 8 " Heading Change " 9 " Reserved for standard types " 16 " Reserved for system specific types " 18 " History average speed " 19 " Traffic Flow " 20 " Reserved for system specific types " ;
VAL_ 733 ADAS_ProfShort_CtrlPoint 0 " false " 1 " true " ;
VAL_ 733 ADAS_ProfShort_Retr 0 " false " 1 " true " ;
VAL_ 733 ADAS_ProfShort_Update 0 " false " 1 " true " ;
VAL_ 733 ADAS_ProfShort_AccurClass 0 " Hiest accuracy " 1 " Medium accuracy " 2 " Lowest accuracy " 3 " Unknown " ;
VAL_ 733 ADAS_ProfShort_Dist1 0 " no other profile values are defined in this message " 1 " Valid value " 1023 " Invalid " ;
VAL_ 733 ADAS_ProfShort_Value0 0 " Valid data " 1023 " Unknow " ;
VAL_ 733 ADAS_ProfShort_Value1 0 " Valid data " 1023 " Unknow " ;
VAL_ 734 ADAS_ProfLong_MsgTyp 0 " System Specific " 1 " Position " 2 " Segment " 3 " Stub " 4 " Profile Short " 5 " Profile Long " 6 " Meta-data " 7 " Reserved " ;
VAL_ 734 ADAS_ProfLong_Offset 0 " Valid value " 8191 " Invalid " ;
VAL_ 734 ADAS_ProfLong_CycCnt 0 " Valid value " ;
VAL_ 734 ADAS_ProfLong_PathIdx 0 " Valid value " ;
VAL_ 734 ADAS_ProfLong_ProfTyp 0 " unkown " 1 " Longitude " 2 " Latitude " 3 " Altitude " 4 " Control Point Longitude " 5 " Control Point Latitude " 6 " Control Point Altitude " 7 " Link Identifier " 8 " Traffic Sign " 9 " Truck Speed Limits " 10 " Extended Lane " 11 " Reserved for standard types " 16 " Reserved for system specific types " 19 " Traffic Event " 20 " weather " 21 " Reserved for system specific types " ;
VAL_ 734 ADAS_ProfLong_CtrlPoint 0 " false " 1 " true " ;
VAL_ 734 ADAS_ProfLong_Retr 0 " false " 1 " true " ;
VAL_ 734 ADAS_ProfLong_Update 0 " false " 1 " true " ;
VAL_ 734 ADAS_ProfLong_Value 0 " Valid value " -2147483648 " invalid " ;
VAL_ 743 Checksum_BCM10 0 " Valid values " ;
VAL_ 743 HiBeamWorkCmd 0 " Off " 1 " On " ;
VAL_ 743 LowBeamWorkCmd 0 " Off " 1 " On " ;
VAL_ 743 RTurnLmpWorkCmd 0 " Off " 1 " On " ;
VAL_ 743 LTurnLampWorkCmd 0 " Off " 1 " On " ;
VAL_ 743 FFogLmpAsstSts 0 " Not active " 1 " Active " ;
VAL_ 743 HornWorkCmd 0 " Off " 1 " On " ;
VAL_ 743 RDayRunngLmpWorkCmd 0 " Off " 1 " On " ;
VAL_ 743 LDayRunngLmpWorkCmd 0 " Off " 1 " On " ;
VAL_ 743 RFFogLmpWorkCmd 0 " Off " 1 " On " ;
VAL_ 743 LFFogLmpWorkCmd 0 " Off " 1 " On " ;
VAL_ 743 AsstPosnLmpSts 0 " Not active " 1 " Active " ;
VAL_ 743 ChildLockProtWorkCmd 0 " No action " 1 " Lock " 2 " Unlock " 3 " Reserved " ;
VAL_ 743 LicPlateLmpWorkCmd 0 " Off " 1 " On " ;
VAL_ 743 ReversLampWorkCmd 0 " Off " 1 " On " ;
VAL_ 743 BrkLmpWorkCmd 0 " Off " 1 " On " ;
VAL_ 743 RFogLmpWorkCmd 0 " Off " 1 " On " ;
VAL_ 743 LasHdLmpWorkCmd 0 " Off " 1 " On " ;
VAL_ 743 LCornrLmpWorkCmd 0 " Off " 1 " On " ;
VAL_ 743 RCornrLmpWorkCmd 0 " Off " 1 " On " ;
VAL_ 743 RHorseRaceLmpWorkCmd 0 " Off " 1 " On " ;
VAL_ 743 LHorseRaceLmpWorkCmd 0 " Off " 1 " On " ;
VAL_ 743 TrunkLmpWorkCmd 0 " Off " 1 " On " ;
VAL_ 743 Rollingcounter_BCM10 0 " Valid value " 15 " Invalid value " ;
VAL_ 745 HUT_OD_Obj7_ID 0 " Valid values " 10 " Invalid values " ;
VAL_ 745 HUT_OD_Obj7_type 0 " No target " 1 " Pedestrian or Biker " 2 " Vehicle " 3 " Ground Locker or Barrier " 4 " Unknown type " 5 " Invalid values " ;
VAL_ 745 HUT_OD_Obj7_Confidence 0 " 0-1 " 11 " Invalid values " ;
VAL_ 745 HUT_OD_Obj7_width 0 " Valid values " 127 " Invalid values " ;
VAL_ 745 HUT_OD_Obj7_Ground_Pos_X 0 " Valid values " 4001 " Reserved " 4095 " Invalid values " ;
VAL_ 745 HUT_OD_Obj7_Ground_Pos_Y 0 " Valid values " 4001 " Reserved " 4095 " Invalid values " ;
VAL_ 745 HUT_OD_WorkSts 0 " OFF " 1 " FOD Active " 2 " ROD Active " 3 " Reserved " ;
VAL_ 745 HUT_OD_Obj_Timestamp 0 " Valid values " ;
VAL_ 745 HUT_FSD1_distance 0 " Valid values " 61 " Invalid values " ;
VAL_ 745 HUT_FSD2_distance 0 " Valid values " 61 " Invalid values " ;
VAL_ 745 HUT_FSD3_distance 0 " Valid values " 61 " Invalid values " ;
VAL_ 745 HUT_FSD4_distance 0 " Valid values " 61 " Invalid values " ;
VAL_ 745 HUT_FSD5_distance 0 " Valid values " 61 " Invalid values " ;
VAL_ 745 HUT_FSD6_distance 0 " Valid values " 61 " Invalid values " ;
VAL_ 745 HUT_FSD7_distance 0 " Valid values " 61 " Invalid values " ;
VAL_ 745 HUT_FSD8_distance 0 " Valid values " 61 " Invalid values " ;
VAL_ 745 HUT_FSD9_distance 0 " Valid values " 61 " Invalid values " ;
VAL_ 745 HUT_FSD10_distance 0 " Valid values " 61 " Invalid values " ;
VAL_ 745 HUT_FSD11_distance 0 " Valid values " 61 " Invalid values " ;
VAL_ 745 HUT_FSD12_distance 0 " Valid values " 61 " Invalid values " ;
VAL_ 745 HUT_FSD13_distance 0 " Valid values " 61 " Invalid values " ;
VAL_ 745 HUT_FSD14_distance 0 " Valid values " 61 " Invalid values " ;
VAL_ 745 HUT_FSD15_distance 0 " Valid values " 61 " Invalid values " ;
VAL_ 745 HUT_FSD16_distance 0 " Valid values " 61 " Invalid values " ;
VAL_ 745 HUT_FSD17_distance 0 " Valid values " 61 " Invalid values " ;
VAL_ 745 HUT_FSD18_distance 0 " Valid values " 61 " Invalid values " ;
VAL_ 748 DVR_360VideoCaptureReq 0 " Off " 1 " On " ;
VAL_ 762 HCU_RdyLmpSts 0 " OFF " 1 " ON " ;
VAL_ 769 MaxEngTrqNorm 0 " Valid values " 103 " Rserved " ;
VAL_ 769 EngLimpHomeSts 0 " Not in limp home mode " 1 " In limp home mode " ;
VAL_ 778 RCTA_B_TTC 0 " No Display " 1 " valid value " ;
VAL_ 778 BSD_LCA_Left_TTC 0 " No Display " 1 " valid value " ;
VAL_ 778 BSD_LCA_Right_TTC 0 " No Display " 1 " valid value " ;
VAL_ 778 RCW_TTC 0 " No Display " 1 " valid value " ;
VAL_ 778 RSDS_LeTgt_01 0 " No target " 1 " target detected " ;
VAL_ 778 RSDS_LeTgt_01_dx 0 " Valid Value " 951 " Reserved " ;
VAL_ 778 RSDS_LeTgt_01_dy 0 " Valid Value " 81 " Reserved " ;
VAL_ 778 RSDS_LeTgt_02 0 " No target " 1 " target detected " ;
VAL_ 778 RSDS_LeTgt_02_dx 0 " Valid Value " 951 " Reserved " ;
VAL_ 778 RSDS_LeTgt_02_dy 0 " Valid Value " 81 " Reserved " ;
VAL_ 778 RSDS_RiTgt_01 0 " No target " 1 " target detected " ;
VAL_ 778 RSDS_RiTgt_01_dx 0 " Valid Value " 951 " Reserved " ;
VAL_ 778 RSDS_RiTgt_01_dy 0 " Valid Value " 81 " Reserved " ;
VAL_ 778 RSDS_RiTgt_02 0 " No target " 1 " target detected " ;
VAL_ 778 RSDS_RiTgt_02_dx 0 " Valid Value " 951 " Reserved " ;
VAL_ 778 RSDS_RiTgt_02_dy 0 " Valid Value " 81 " Reserved " ;
VAL_ 778 RSDS_MidTgt_01 0 " No target " 1 " target detected " ;
VAL_ 778 RSDS_MidTgt_01_dx 0 " Valid Value " 951 " Reserved " ;
VAL_ 778 RSDS_MidTgt_01_dy 0 " Valid Value " 81 " Reserved " ;
VAL_ 778 RSDS_MidTgt_02 0 " No target " 1 " target detected " ;
VAL_ 778 RSDS_MidTgt_02_dx 0 " Valid Value " 951 " Reserved " ;
VAL_ 778 RSDS_MidTgt_02_dy 0 " Valid Value " 81 " Reserved " ;
VAL_ 793 TrunkSts 0 " Closed " 1 " Open " ;
VAL_ 793 DrvDoorSts 0 " Closed " 1 " Open " ;
VAL_ 793 LRDoorSts 0 " Closed " 1 " Open " ;
VAL_ 793 PassengerDoorSts 0 " Closed " 1 " Open " ;
VAL_ 793 RRDoorSts 0 " Closed " 1 " Open " ;
VAL_ 793 WindshldWiprActvSts 0 " Not active " 1 " Active " ;
VAL_ 793 BrkPedalSts_BCM 0 " Off " 1 " On " ;
VAL_ 793 BrkPedalFailSts 0 " No failure " 1 " Failure " ;
VAL_ 793 ParkBrkSts 0 " Off " 1 " On " 2 " Reserved " 3 " Not available " ;
VAL_ 793 ReversGearSts 0 " Off " 1 " On " 2 " Reserved " 3 " Not available " ;
VAL_ 793 PosnLightReq 0 " Off " 1 " On " ;
VAL_ 793 RLSFailSts 0 " No failure " 1 " Failure " ;
VAL_ 833 FLTirePressIndSts 0 " Normal " 1 " Low  " 2 " Reserved  " 3 " High " 4 " Not available " 5 " Reserved " ;
VAL_ 833 FRTirePressIndSts 0 " Normal " 1 " Low  " 2 " Reserved  " 3 " High " 4 " Not available " 5 " Reserved " ;
VAL_ 833 TirePressSysFailrIndcn 0 " No failure " 1 " Failure " 2 " Reserved " ;
VAL_ 833 RLTirePressIndSts 0 " Normal " 1 " Low  " 2 " Reserved  " 3 " High " 4 " Not available " 5 " Reserved " ;
VAL_ 833 RRTirePressIndSts 0 " Normal " 1 " Low  " 2 " Reserved  " 3 " High " 4 " Not available " 5 " Reserved " ;
VAL_ 833 FLTireTempSts 0 " Normal " 1 " High " 2 " Not available " 3 " Reserved " ;
VAL_ 833 FRTireTempSts 0 " Normal " 1 " High " 2 " Not available " 3 " Reserved " ;
VAL_ 833 RLTireTempSts 0 " Normal " 1 " High " 2 " Not available " 3 " Reserved " ;
VAL_ 833 RRTireTempSts 0 " Normal " 1 " High " 2 " Not available " 3 " Reserved " ;
VAL_ 833 TPMS_AutoLoctSts 0 " Auto-Learn or Auto-Locate not in progress / TPMS is base system " 1 " Auto-Learn in progress " 2 " Auto-Locate in progress (Auto-Learn complete) " 3 " Auto-Locate complete " 4 " Auto-Learn timeout " 5 " Auto-Locate timeout " 6 " Reserved " ;
VAL_ 837 BCM_HWPWorkSts 0 " Disable " 1 " Enable " 2 " Active " 3 " Failed " ;
VAL_ 837 HazardLmpSwtSts 0 " Off " 1 " On " ;
VAL_ 846 Sync_CRC 0 " Valid value " ;
VAL_ 846 Sync_OVS 0 " Valid value " ;
VAL_ 846 Sync_Resd 0 " Valid value " ;
VAL_ 846 Sync_Counter 0 " Valid value " ;
VAL_ 846 Sync_SGW 0 " Valid value " ;
VAL_ 846 Sync_SyncTime 0 " Valid value " ;
VAL_ 846 Sync_TimeDomain 0 " Valid value " ;
VAL_ 846 Sync_Type 0 " Valid value " ;
VAL_ 849 CheckSum_ABM1 0 " Valid values " ;
VAL_ 849 DrvSBR 0 " No reminder " 1 " Reminder " ;
VAL_ 849 PassSBR 0 " No reminder " 1 " Reminder " ;
VAL_ 849 PABSwtSts 0 " Switch OFF_PAB Ban " 1 " Switch ON_PAB Not Ban " ;
VAL_ 849 SecRowLSBR 0 " No reminder " 1 " Reminder " ;
VAL_ 849 AirbFailLmpCmd 0 " Lamp off " 1 " Lamp on " ;
VAL_ 849 SecRowMidSBR 0 " No reminder " 1 " Reminder " ;
VAL_ 849 SecRowRSBR 0 " No reminder " 1 " Reminder " ;
VAL_ 849 PassSBR_Visual 0 " Lamp off " 1 " Lamp on " 2 " Reserved " 3 " Lamp  blink & sound remind " ;
VAL_ 849 DrvSBR_Visual 0 " Lamp off " 1 " Lamp on " 2 " Reserved " 3 " Lamp  blink & sound remind " ;
VAL_ 849 SecRowLSBR_Visual 0 " Lamp off " 1 " Lamp on " 2 " Reserved " 3 " Lamp  blink & sound remind " ;
VAL_ 849 SecRowMidSBR_Visual 0 " Lamp off " 1 " Lamp on " 2 " Reserved " 3 " Lamp  blink & sound remind " ;
VAL_ 849 SecRowRSBR_Visual 0 " Lamp off " 1 " Lamp on " 2 " Reserved " 3 " Lamp  blink & sound remind " ;
VAL_ 849 CrashOutputSts 0 " No crash " 1 " Reserved " 2 " Front First level " 3 " rear crash(Reserved) " 4 " Reserved " 8 " Right hand side " 9 " Reserved " 16 " Left hand side  " 17 " Rollover(Reserved) " 18 " Static Roll(Reserved)  " 19 " Reserved " ;
VAL_ 849 RollingCounter_ABM1 0 " Valid value " 15 " Invalid value " ;
VAL_ 880 TimeMod 0 " 24 " 1 " 12 " ;
VAL_ 880 TimeIndcn 0 " am " 1 " pm " ;
VAL_ 880 Time_Hour 0 " Valid hour " 24 " Reserved " 31 " Invalid " ;
VAL_ 880 Time_Minutes 0 " Valid minute " 60 " Reserved " 63 " Invalid " ;
VAL_ 880 Time_Second 0 " Valid second " 60 " Reserved " 63 " Invalid " ;
VAL_ 880 Time_Year_Left 0 " Valid year " 10 " Reserved " 15 " Invalid " ;
VAL_ 880 Time_Year_Right 0 " Valid year " 10 " Reserved " 15 " Invalid " ;
VAL_ 880 Time_Month 0 " Invalid " 1 " Valid month " 13 " Reserved " ;
VAL_ 880 Time_Day 0 " Invalid " 1 " Valid day " ;
VAL_ 901 ACAmbTemp 0 " Valid value " 254 " Initial value " 255 " Invalid Value " ;
VAL_ 901 ACFrntBlwrSpd 0 " Off " 1 " Level 1гиLowгй-7гиHiгй " 8 " Reserved " 14 " Auto blower level " 15 " Initial value " ;
VAL_ 1001 T_Box_SysErrSts 0 " No error " 1 " Error " 2 " Reserved " ;
VAL_ 1045 ADAS_Meta_MsgTyp 0 " System Specific " 1 " Position " 2 " Segment " 3 " Stub " 4 " Profile Short " 5 " Profile Long " 6 " Meta-data " 7 " Reserved " ;
VAL_ 1045 ADAS_Meta_MapProvider 0 " Unknown " 1 " Nokia HERE (NAVTEQ) " 2 " TomTom (Tele Atlas) " 3 " Zenrin " 4 " IPC " 5 " NavInfo " 6 " Other " 7 " N/A " ;
VAL_ 1045 ADAS_Meta_CountryCode 0 " Unknown " 1 " Valid values " ;
VAL_ 1045 ADAS_Meta_CycCnt 0 " Valid values " ;
VAL_ 1045 ADAS_Meta_ProtVer_Major 0 " Valid values " ;
VAL_ 1045 ADAS_Meta_ProtVer_MinorSub 0 " Valid values " ;
VAL_ 1045 ADAS_Meta_HwVer 0 " Unknown " 1 " Valid values " ;
VAL_ 1045 ADAS_Meta_DrvSide 0 " Drvg Side Left " 1 " Drvg Side Right " ;
VAL_ 1045 ADAS_Meta_RegionCode 0 " Unknow " 1 " Valid values " 32767 " Invalid " ;
VAL_ 1045 ADAS_Meta_MapVerQtr 0 " Valid values " ;
VAL_ 1045 ADAS_Meta_MapVerYear 0 " Valid values " 63 " invalid " ;
VAL_ 1045 ADAS_Meta_SpdUnits 0 " KM/H " 1 " MPH " ;
VAL_ 1045 ADAS_Meta_ProtVer_Minor 0 " Valid values " ;
VAL_ 1305 Destination_HC_NM 1 "GW" 2 "PEPS" 3 "ESCL" 4 "LRSDS" 5 "RRSDS" 6 "BCM" 7 "Trailer" 8 "T-Box" 9 "CMS" 10 "AC" 11 "SCM" 12 "DSM" 13 "DDCM" 14 "PDCM" 15 "HUT" 16 "HCM" 17 "AC_RCP" 18 "TPMS" 32 "ACU" 33 "HCU" 34 "OBC" 35 "BMS" 36 "MCU" 37 "BSG" ;
VAL_ 1305 OpCode_HC_NM 1 "Alive" 2 "ring" 4 "limphome" 18 "ring_sleep_ind" 20 "limphome_sleep_ind" 50 "ring_sleep_ack" ;
VAL_ 1308 Destination_IDC_L3_NM 1 "GW" 2 "PEPS" 3 "ESCL" 4 "LRSDS" 5 "RRSDS" 6 "BCM" 7 "Trailer" 8 "T-Box" 9 "CMS" 10 "AC" 11 "SCM" 12 "DSM" 13 "DDCM" 14 "PDCM" 15 "HUT" 16 "HCM" 17 "AC_RCP" 18 "TPMS" 32 "ACU" 33 "HCU" 34 "OBC" 35 "BMS" 36 "MCU" 37 "BSG" ;
VAL_ 1308 OpCode_IDC_L3_NM 1 "Alive" 2 "ring" 4 "limphome" 18 "ring_sleep_ind" 20 "limphome_sleep_ind" 50 "ring_sleep_ack" ;
VAL_ 1309 Destination_RRR_NM 1 "GW" 2 "PEPS" 3 "ESCL" 4 "LRSDS" 5 "RRSDS" 6 "BCM" 7 "Trailer" 8 "T-Box" 9 "CMS" 10 "AC" 11 "SCM" 12 "DSM" 13 "DDCM" 14 "PDCM" 15 "HUT" 16 "HCM" 17 "AC_RCP" 18 "TPMS" 32 "ACU" 33 "HCU" 34 "OBC" 35 "BMS" 36 "MCU" 37 "BSG" ;
VAL_ 1309 OpCode_RRR_NM 1 "Alive" 2 "ring" 4 "limphome" 18 "ring_sleep_ind" 20 "limphome_sleep_ind" 50 "ring_sleep_ack" ;
VAL_ 1310 Destination_SRR_L_NM 1 "GW" 2 "PEPS" 3 "ESCL" 4 "LRSDS" 5 "RRSDS" 6 "BCM" 7 "Trailer" 8 "T-Box" 9 "CMS" 10 "AC" 11 "SCM" 12 "DSM" 13 "DDCM" 14 "PDCM" 15 "HUT" 16 "HCM" 17 "AC_RCP" 18 "TPMS" 32 "ACU" 33 "HCU" 34 "OBC" 35 "BMS" 36 "MCU" 37 "BSG" ;
VAL_ 1310 OpCode_SRR_L_NM 1 "Alive" 2 "ring" 4 "limphome" 18 "ring_sleep_ind" 20 "limphome_sleep_ind" 50 "ring_sleep_ack" ;
VAL_ 1311 Destination_SRR_R_NM 1 "GW" 2 "PEPS" 3 "ESCL" 4 "LRSDS" 5 "RRSDS" 6 "BCM" 7 "Trailer" 8 "T-Box" 9 "CMS" 10 "AC" 11 "SCM" 12 "DSM" 13 "DDCM" 14 "PDCM" 15 "HUT" 16 "HCM" 17 "AC_RCP" 18 "TPMS" 32 "ACU" 33 "HCU" 34 "OBC" 35 "BMS" 36 "MCU" 37 "BSG" ;
VAL_ 1311 OpCode_SRR_R_NM 1 "Alive" 2 "ring" 4 "limphome" 18 "ring_sleep_ind" 20 "limphome_sleep_ind" 50 "ring_sleep_ack" ;
VAL_ 1281 Destination_GW_NM 1 "GW" 2 "PEPS" 3 "ESCL" 4 "LRSDS" 5 "RRSDS" 6 "BCM" 7 "Trailer" 8 "T-Box" 9 "CMS" 10 "AC" 11 "SCM" 12 "DSM" 13 "DDCM" 14 "PDCM" 15 "HUT" 16 "HCM" 17 "AC_RCP" 18 "TPMS" 32 "ACU" 33 "HCU" 34 "OBC" 35 "BMS" 36 "MCU" 37 "BSG" ;
VAL_ 1281 OpCode_GW_NM 1 "Alive" 2 "ring" 4 "limphome" 18 "ring_sleep_ind" 20 "limphome_sleep_ind" 50 "ring_sleep_ack" ;
